VERSION ""

NS_ :

BS_:
BU_: SC PT BMS ME SC01 BMS01

BO_ 1600 SC01_DebugSlowMpex: 8 SC01
 SG_ pumpMAHLEshortCircuitErr_SC01 m44 : 26|1@0+ (1,0) [0|0] "" Vector__XXX
 SG_ pumpMAHLElowLoadOpErr_SC01 m44 : 25|1@0+ (1,0) [0|0] "" Vector__XXX
 SG_ pumpMAHLEstallFaultErr_SC01 m44 : 24|1@0+ (1,0) [0|0] "" Vector__XXX
 SG_ pumpMAHLEvoltageDeratingWarn_SC0 m44 : 39|1@0+ (1,0) [0|0] "" Vector__XXX
 SG_ pumpMAHLEunderVoltageErr_SC01 m44 : 38|1@0+ (1,0) [0|0] "" Vector__XXX
 SG_ pumpMAHLEoverVoltageErr_SC01 m44 : 37|1@0+ (1,0) [0|0] "" Vector__XXX
 SG_ pumpMAHLEoverTemperatureDerWarn_ m44 : 36|1@0+ (1,0) [0|0] "" Vector__XXX
 SG_ pumpMAHLEoverTemperatureErr_SC01 m44 : 35|1@0+ (1,0) [0|0] "" Vector__XXX
 SG_ pumpMAHLEoverCurrentErr_SC01 m44 : 34|1@0+ (1,0) [0|0] "" Vector__XXX
 SG_ pumpMAHLEinternalFaultErr_SC01 m44 : 33|1@0+ (1,0) [0|0] "" Vector__XXX
 SG_ pumpMAHLElinErr_SC01 m44 : 32|1@0+ (1,0) [0|0] "" Vector__XXX
 SG_ cmbSM30MinSettleTime_SC01 m44 : 15|16@0+ (1,0) [0|65535] "ms"  PT
 SG_ cmbSM30SettleTimeFault_SC01 m32 : 42|1@0+ (1,0) [0|1] ""  PT
 SG_ pressureSensSpecHumidity2_SC01 m43 : 55|16@0+ (0.01,0) [0|642.55] "g/kg" Vector__XXX
 SG_ pressureSensRelHumidity2_SC01 m43 : 15|8@0+ (0.4,0) [0|100] "%" Vector__XXX
 SG_ pressureSensIntakeTemp2_SC01 m43 : 23|16@0+ (0.03125,-273) [-273|1734.96875] "C" Vector__XXX
 SG_ pressureSensIntakePres2_SC01 m43 : 39|16@0+ (0.0078125,-250) [-250|251.99] "kPa" Vector__XXX
 SG_ pressure2_SC01 m22 : 15|8@0+ (0.4,0) [0|102] "psi" Vector__XXX
 SG_ cmbSM29ScoutTempIndex_SC01 m42 : 15|8@0+ (1,0) [0|255] "" Vector__XXX
 SG_ cmbSM19ScoutPDO_SC01 m42 : 55|16@0+ (0.0001,0) [0|6.5] "V" Vector__XXX
 SG_ cmbMaxSM15ratio_SC01 m41 : 39|16@0+ (0.00390625,0) [0|255.99609375] ""  PT
 SG_ cmbMinSM15ratio_SC01 m41 : 55|16@0+ (0.00390625,0) [0|255.99609375] ""  PT
 SG_ cmbMinSM17Ratio m42 : 39|16@0+ (0.00390625,0) [0|255.99609375] ""  PT
 SG_ cmbMaxSM17Ratio m42 : 23|16@0+ (0.00390625,0) [0|255.99609375] ""  PT
 SG_ cmbMaxSM16DiffC2S_SC01 m41 : 23|16@0+ (0.2,0) [0|13107] "mV"  PT
 SG_ isolationResInternRelaxed_SC01 m32 : 23|16@0+ (2,0) [0|130000] "kOhm"  PT
 SG_ pressureSensSpecHumidity_SC01 m40 : 55|16@0+ (0.01,0) [0|642.55] "g/kg"  PT
 SG_ pressureSensIntakePres_SC01 m40 : 39|16@0+ (0.0078125,-250) [-250|251.99] "kPa"  PT
 SG_ pressureSensIntakeTemp_SC01 m40 : 23|16@0+ (0.03125,-273) [-273|1734.96875] "C"  PT
 SG_ pressureSensRelHumidity_SC01 m40 : 15|8@0+ (0.4,0) [0|100] "%"  PT
 SG_ cmbVariantCodingVoltage_SC01 m32 : 55|16@0+ (0.0001,0) [0|6.5] "V"  PT
 SG_ isolationSelftestMaxDiff_SC01 m32 : 39|8@0+ (0.1,0) [0|25.5] "V"  PT
 SG_ packTypeDeterminationTime_SC01 m22 : 39|32@0+ (1,0) [0|0] "ms"  PT
 SG_ FEESector2Flags_SC01 m22 : 23|16@0+ (1,0) [0|0] ""  PT
 SG_ appTask500HzMaxAvg_SC01 m23 : 63|8@0+ (0.02,0) [0|5.1] "ms"  PT
 SG_ safetyHangLastLinkReg_SC01 m39 : 23|32@0+ (1,0) [0|4294967295] ""  PT
 SG_ safetyHangPresentLinkReg_SC01 m38 : 23|32@0+ (1,0) [0|4294967295] ""  PT
 SG_ safetyHangDataFaultStatus_SC01 m37 : 23|32@0+ (1,0) [0|4294967295] ""  PT
 SG_ safetyHangDataFaultAddr_SC01 m36 : 23|32@0+ (1,0) [0|4294967295] ""  PT
 SG_ safetyHangLastARMMode_SC01 m35 : 63|8@0+ (1,0) [0|255] ""  PT
 SG_ safetyHangPresARMMode_SC01 m35 : 55|8@0+ (1,0) [0|255] ""  PT
 SG_ safetyHangESMGrp3Reg_SC01 m35 : 23|32@0+ (1,0) [0|4294967295] ""  PT
 SG_ safetyHangInstrFaultStatus_SC01 m34 : 23|32@0+ (1,0) [0|4294967295] ""  PT
 SG_ safetyHangInstrFaultAddr_SC01 m33 : 23|32@0+ (1,0) [0|4294967295] ""  PT
 SG_ eaglePackType_SC01 m4 : 53|2@0+ (1,0) [0|3] ""  PT
 SG_ pressure_SC01 m4 : 63|8@0+ (0.4,0) [0|102] "psi"  PT
 SG_ cmbMaxSM33Diff_SC01 m31 : 15|8@0+ (0.001,0) [0|0.255] "V"  PT
 SG_ cmbMinSM29Diff_SC01 m17 : 15|8@0+ (0.001,0) [0|0.255] "V"  PT
 SG_ cmbSM4MinIndex_SC01 m24 : 15|8@0+ (1,0) [0|0] ""  PT
 SG_ cmbSM4DiffC2_SC01 m31 : 23|16@0+ (0.0001,0) [0|6.5] "V"  PT
 SG_ cmbMinSM4Diff_SC01 m31 : 39|16@0+ (0.0001,0) [0|6.5] "V"  PT
 SG_ cmbMaxSM4Diff_SC01 m21 : 55|16@0+ (0.0001,0) [0|6.5] "V"  PT
 SG_ cmbSM27MinIndex_SC01 m15 : 63|8@0+ (1,0) [0|0] ""  PT
 SG_ cmbSM27DiffC2_SC01 m24 : 55|16@0+ (0.0001,0) [0|6.5] "V"  PT
 SG_ cmbMinSM27Diff_SC01 m31 : 55|16@0+ (0.0001,0) [0|6.5] "V"  PT
 SG_ cmbMaxSM27Diff_SC01 m25 : 55|16@0+ (0.0001,0) [0|6.5] "V"  PT
 SG_ adcDriverFail_SC01 m4 : 51|4@0+ (1,0) [0|0] ""  PT
 SG_ mainUcHvilState_SC01 m32 : 41|2@0+ (1,0) [0|0] ""  PT
 SG_ mainUcIntIsoErr_SC01 m32 : 13|2@0+ (1,0) [0|0] ""  PT
 SG_ mainUcExtIsoErr_SC01 m32 : 15|2@0+ (1,0) [0|0] ""  PT
 SG_ safetyUcThermalStatus_SC01 m32 : 9|2@0+ (1,0) [0|0] ""  PT
 SG_ mainUcThermalStatus_SC01 m32 : 11|2@0+ (1,0) [0|0] ""  PT
 SG_ selfTestErrorAddress_SC01 m30 : 23|32@0+ (1,0) [0|4294967295] ""  PT
 SG_ selfTestDataFaultStatus_SC01 m29 : 23|32@0+ (1,0) [0|4294967295] ""  PT
 SG_ selfTestInstrFaultAddr_SC01 m28 : 23|32@0+ (1,0) [0|4294967295] ""  PT
 SG_ selfTestDataFaultAddr_SC01 m27 : 23|32@0+ (1,0) [0|4294967295] ""  PT
 SG_ selfTestInstrFaultStatus_SC01 m26 : 23|32@0+ (1,0) [0|4294967295] ""  PT
 SG_ internalIsolationError_SC01 m25 : 11|2@0+ (1,0) [0|0] ""  PT
 SG_ externalIsolationError_SC01 m25 : 13|2@0+ (1,0) [0|0] ""  PT
 SG_ isolationTestState_SC01 m25 : 9|2@0+ (1,0) [0|0] ""  PT
 SG_ isolationResistanceIntern_SC01 m25 : 23|16@0+ (2,0) [0|130000] "kOhm"  PT
 SG_ isolationResistanceExtern_SC01 m25 : 39|16@0+ (2,0) [0|130000] "kOhm"  PT
 SG_ maxAdolV13Diff_SC01 m24 : 23|16@0+ (0.0001,0) [0|6.5] "V"  PT
 SG_ maxAdolV7Diff_SC01 m24 : 39|16@0+ (0.0001,0) [0|6.5] "V"  PT
 SG_ pumpType_SC01 m23 : 55|8@0+ (1,0) [0|0] ""  PT
 SG_ pumpJomaLinErr_SC01 m23 : 30|1@0+ (1,0) [0|0] ""  PT
 SG_ pumpJomaPumpState_SC01 m23 : 18|3@0+ (1,0) [0|0] ""  PT
 SG_ pumpBoschPwmInStat_SC01 m23 : 27|2@0+ (1,0) [0|0] ""  PT
 SG_ pumpBoschRpmMonStat_SC01 m23 : 25|2@0+ (1,0) [0|0] ""  PT
 SG_ pumpBoschWakeupStat_SC01 m23 : 39|2@0+ (1,0) [0|0] ""  PT
 SG_ pumpBoschPostRunMode_SC01 m23 : 44|3@0+ (1,0) [0|0] ""  PT
 SG_ pumpPhaseCurrent_SC01 m23 : 15|8@0+ (0.1,0) [0|0] "A"  PT
 SG_ hvWithstandTestQual_SC01 m21 : 15|8@0+ (1,0) [0|255] ""  PT
 SG_ ESM_RAM_ODD_ADDR_UNCORR_SC01 m21 : 18|1@0+ (1,0) [0|0] ""  PT
 SG_ ESM_RAM_EVEN_ADDR_UNCORR_SC01 m21 : 17|1@0+ (1,0) [0|0] ""  PT
 SG_ ESM_FMC_UNCORR_ERR_SC01 m21 : 40|1@0+ (1,0) [0|0] ""  PT
 SG_ ESM_RAM_ODDECC_UNCORR_SC01 m21 : 23|1@0+ (1,0) [0|0] ""  PT
 SG_ ESM_RAM_EVENECC_UNCORR_SC01 m21 : 22|1@0+ (1,0) [0|0] ""  PT
 SG_ ESM_EFUSE_FARM_ERR_SC01 m21 : 21|1@0+ (1,0) [0|0] ""  PT
 SG_ ESM_RTI_WWD_NMI_SC01 m21 : 20|1@0+ (1,0) [0|0] ""  PT
 SG_ ESM_TCM_ECC_LIVE_LOCK_SC01 m21 : 19|1@0+ (1,0) [0|0] ""  PT
 SG_ ESM_RAM_ODD_UNCORR_ERR_SC01 m21 : 16|1@0+ (1,0) [0|0] ""  PT
 SG_ ESM_RAM_EVEN_UNCORR_ERR_SC01 m21 : 31|1@0+ (1,0) [0|0] ""  PT
 SG_ ESM_FMC_ADDR_UNCORR_ERR_SC01 m21 : 30|1@0+ (1,0) [0|0] ""  PT
 SG_ ESM_CCM4_COMPARE_FAULT_SC01 m21 : 29|1@0+ (1,0) [0|0] ""  PT
 SG_ ESM_RAM_ODD_CORR_ERR_SC01 m21 : 28|1@0+ (1,0) [0|0] ""  PT
 SG_ ESM_RAM_EVEN_CORR_ERR_SC01 m21 : 27|1@0+ (1,0) [0|0] ""  PT
 SG_ ESM_CLK_MONITOR_SC01 m21 : 26|1@0+ (1,0) [0|0] ""  PT
 SG_ ESM_PLL_SLIP_SC01 m21 : 25|1@0+ (1,0) [0|0] ""  PT
 SG_ ESM_FMC_CORR_ERR_SC01 m21 : 24|1@0+ (1,0) [0|0] ""  PT
 SG_ analogMMCUSleepTrigger_SC01 m20 : 55|8@0+ (0.015,0) [0|0] "V"  PT
 SG_ analogPyroLSDStatus_SC01 m20 : 63|8@0+ (0.015,0) [0|0] "V"  PT
 SG_ analogGPIO2Volt_SC01 m19 : 47|8@0+ (0.1,0) [0|25] "V"  PT
 SG_ analogGPIO2Current_SC01 m19 : 55|8@0+ (0.015,0) [0|3.825] "A"  PT
 SG_ analogGPIO1Volt_SC01 m19 : 63|8@0+ (0.1,0) [0|25] "V"  PT
 SG_ analogGPIO1Current_SC01 m20 : 15|8@0+ (0.015,0) [0|3.825] "A"  PT
 SG_ currentModuleMax_SC01 m1 : 55|16@0+ (0.1,-3200) [-3200|3200] "A"  PT
 SG_ currentModuleMin_SC01 m1 : 39|16@0+ (0.1,-3200) [-3200|3200] "A"  PT
 SG_ cmbSumOfCellSTATRef_SC01 m20 : 39|16@0+ (0.0015,0) [0|131.07] "V"  PT
 SG_ cmbSumOfCells_SC01 m20 : 23|16@0+ (0.0015,0) [0|131.07] "V"  PT
 SG_ maxCMBDieTemp_SC01 m1 : 31|8@0+ (1,-40) [-40|200] "C"  PT
 SG_ minCMBDieTemp_SC01 m1 : 23|8@0+ (1,-40) [-40|200] "C"  PT
 SG_ pumpBoschSuppVoltErr_SC01 m23 : 35|2@0+ (1,0) [0|0] ""  PT
 SG_ pumpBoschRsErr_SC01 m23 : 45|1@0+ (1,0) [0|0] ""  PT
 SG_ pumpBoschOverTempErr_SC01 m23 : 29|2@0+ (1,0) [0|0] ""  PT
 SG_ pumpBoschOverCurrErr_SC01 m23 : 47|2@0+ (1,0) [0|0] ""  PT
 SG_ pumpBoschElectricErr_SC01 m23 : 41|2@0+ (1,0) [0|0] ""  PT
 SG_ pumpBoschDryRunErr_SC01 m23 : 33|2@0+ (1,0) [0|0] ""  PT
 SG_ pumpDiagnosticBit_SC01 m23 : 31|1@0+ (1,0) [0|0] ""  PT
 SG_ pumpBoschBlockErr_SC01 m23 : 37|2@0+ (1,0) [0|0] ""  PT
 SG_ appTaskSpiRxTx_SC01 m16 : 15|8@0+ (0.02,0) [0|5.1] "ms"  PT
 SG_ variantCodingCounts_SC01 m4 : 39|8@0+ (1,0) [0|0] ""  PT
 SG_ cmbMaxUpdateTime_SC01 m17 : 23|8@0+ (2,0) [0|500] "ms"  PT
 SG_ pumpSetSpeed_SC01 m18 : 55|8@0+ (1,0) [0|255] "PCT"  PT
 SG_ hvilResistance_SC01 m17 : 31|8@0+ (2,0) [0|0] "Ohm"  PT
 SG_ cmbAvgUpdateTime_SC01 m18 : 63|8@0+ (2,0) [0|500] "ms"  PT
 SG_ pumpHCPTempProtect_SC01 m18 : 40|1@0+ (1,0) [0|0] ""  PT
 SG_ pumpHCPCommandErr_SC01 m18 : 41|1@0+ (1,0) [0|0] ""  PT
 SG_ pumpHCPRunDry_SC01 m18 : 42|1@0+ (1,0) [0|0] ""  PT
 SG_ pumpHCPUnderVoltage_SC01 m18 : 43|1@0+ (1,0) [0|0] ""  PT
 SG_ pumpHCPOverVoltage_SC01 m18 : 44|1@0+ (1,0) [0|0] ""  PT
 SG_ pumpHCPOverTemp_SC01 m18 : 45|1@0+ (1,0) [0|0] ""  PT
 SG_ pumpHCPHiCurrShutDown_SC01 m18 : 46|1@0+ (1,0) [0|0] ""  PT
 SG_ pumpHCPHwFault_SC01 m18 : 47|1@0+ (1,0) [0|0] ""  PT
 SG_ pumpTemperature_SC01 m18 : 39|8@0+ (1,-50) [0|0] "C"  PT
 SG_ pumpSpeed_SC01 m18 : 15|8@0+ (1,0) [0|255] "PCT"  PT
 SG_ pumpVoltage_SC01 m18 : 23|8@0+ (0.1,0) [0|0] "V"  PT
 SG_ pumpCurrent_SC01 m18 : 31|8@0+ (0.1,0) [0|0] "A"  PT
 SG_ posLink3_SC01 m17 : 39|16@0+ (0.04,-1250) [-1250|1371.4] "V"  PT
 SG_ negLink3_SC01 m17 : 55|16@0+ (0.04,-1250) [-1250|1371.4] "V"  PT
 SG_ posLink2_SC01 m16 : 39|16@0+ (0.04,-1250) [-1250|1371.4] "V"  PT
 SG_ negLink2_SC01 m16 : 55|16@0+ (0.04,-1250) [-1250|1371.4] "V"  PT
 SG_ cmbNrOfSamples_SC01 m16 : 23|8@0+ (1,0) [0|0] ""  PT
 SG_ cmbTaskTime_SC01 m16 : 31|8@0+ (1,0) [0|0] "ms"  PT
 SG_ appTask500HzMax_SC01 m15 : 15|8@0+ (0.02,0) [0|5.1] "ms"  PT
 SG_ moduleCount_SC01 m6 : 15|8@0+ (1,0) [0|0] ""  PT
 SG_ analogHallSense_SC01 m15 : 23|16@0+ (0.0001,0) [0|6.5535] "V"  PT
 SG_ cmbMaxDiagStepPeriodicity_SC01 m15 : 55|8@0+ (4,0) [0|1019] "ms"  PT
 SG_ minBrickVoltageLimit_SC01 m15 : 39|16@0+ (0.0001,0) [0|6.5535] "V"  PT
 SG_ appTask100Hz_SC01 m14 : 63|8@0+ (0.02,0) [0|5.1] "ms"  PT
 SG_ appTask10Hz_SC01 m14 : 55|8@0+ (0.02,0) [0|5.1] "ms"  PT
 SG_ appTaskAnalog_SC01 m14 : 47|8@0+ (0.02,0) [0|5.1] "ms"  PT
 SG_ appTaskADC_SC01 m14 : 39|8@0+ (0.02,0) [0|5.1] "ms"  PT
 SG_ appTask500HzAvg_SC01 m14 : 31|8@0+ (0.02,0) [0|5.1] "ms"  PT
 SG_ appTaskSBC_SC01 m14 : 23|8@0+ (0.02,0) [0|5.1] "ms"  PT
 SG_ appTaskCMBDriver_SC01 m14 : 15|8@0+ (0.02,0) [0|5.1] "ms"  PT
 SG_ safetyInitTime_SC01 m12 : 15|8@0+ (2,0) [0|500] "ms"  PT
 SG_ debugSlowMpex_SC01 M : 7|8@0+ (1,0) [0|0] ""  PT
 SG_ sbcWUAuto_SC01 m11 : 9|1@0+ (1,0) [0|0] ""  PT
 SG_ sbcWUUnknown_SC01 m11 : 8|1@0+ (1,0) [0|0] ""  PT
 SG_ sbcWUDebug_SC01 m11 : 10|1@0+ (1,0) [0|0] ""  PT
 SG_ sbcWUPOR_SC01 m11 : 11|1@0+ (1,0) [0|0] ""  PT
 SG_ sbcWUPressure_SC01 m11 : 12|1@0+ (1,0) [0|0] ""  PT
 SG_ sbcWUClock_SC01 m11 : 13|1@0+ (1,0) [0|0] ""  PT
 SG_ sbcWUCAN_SC01 m11 : 14|1@0+ (1,0) [0|0] ""  PT
 SG_ sbcWUKey_SC01 m11 : 15|1@0+ (1,0) [0|0] ""  PT
 SG_ mux960N3VRef_SC01 m13 : 39|16@0+ (-0.000805664,0) [0|0] "V"  PT
 SG_ mux960P2P5VRef_SC01 m13 : 55|16@0+ (0.000805664,0) [0|0] "V"  PT
 SG_ mux440Gnd_SC01 m10 : 15|8@0+ (0.000805664,0) [0|0] "V"  PT
 SG_ analogHallGain_SC01 m13 : 23|16@0+ (1E-005,0.8) [0.8|1.455] "k"  PT
 SG_ analogHallOffset_SC01 m13 : 15|8@0+ (0.0001,-0.005) [-0.005|0.0205] "V"  PT
 SG_ negPackPrime_SC01 m12 : 55|16@0+ (0.04,-1250) [-1250|1250] "V"  PT
 SG_ posPackPrime_SC01 m12 : 39|16@0+ (0.04,-1250) [-1250|1250] "V"  PT
 SG_ packVoltage_SC01 m12 : 23|16@0+ (0.04,-1250) [-1250|1250] "V"  PT
 SG_ sleepTime_SC01 m11 : 23|16@0+ (1,0) [0|0] "s"  PT
 SG_ analogNegHVOffset_SC01 m10 : 63|8@0+ (1,-120) [-120|120] "Bits"  PT
 SG_ analogPosHVOffset_SC01 m10 : 55|8@0+ (1,-120) [-120|120] "Bits"  PT
 SG_ analogNegHVGain_SC01 m10 : 39|16@0+ (1E-005,0.8) [0|0] "k"  PT
 SG_ analogPosHVGain_SC01 m10 : 23|16@0+ (1E-005,0.8) [0.8|1.45535] "k"  PT
 SG_ mux910Gnd_SC01 m8 : 15|8@0+ (0.000805664,0) [0|0] "V"  PT
 SG_ mux960Gnd_SC01 m9 : 15|8@0+ (0.000805664,0) [0|0] "V"  PT
 SG_ analogAddr5_SC01 m9 : 55|16@0+ (0.000805861,0) [0|0] "V"  PT
 SG_ analogAddr4_SC01 m9 : 39|16@0+ (0.000805861,0) [0|0] "V"  PT
 SG_ analogAddr3_SC01 m9 : 23|16@0+ (0.000805861,0) [0|0] "V"  PT
 SG_ analogAddr2_SC01 m8 : 55|16@0+ (0.000805861,0) [0|0] "V"  PT
 SG_ analogAddr1_SC01 m8 : 39|16@0+ (0.000805861,0) [0|0] "V"  PT
 SG_ analogAddr0_SC01 m8 : 23|16@0+ (0.000805861,0) [0|0] "V"  PT
 SG_ sbcVREF2P5_SC01 m7 : 15|8@0+ (0.003222656,2.25) [2.25|3.0715] "V"  PT
 SG_ mux910N3VRef_SC01 m7 : 39|16@0+ (-0.000805664,0) [0|0] "V"  PT
 SG_ mux910P2P5VRef_SC01 m7 : 55|16@0+ (0.000805664,0) [0|0] "V"  PT
 SG_ analogHvilCurrentPWM_SC01 m3 : 31|8@0+ (1,0) [0|255] "mA"  PT
 SG_ analogSBCSupply_SC01 m4 : 47|8@0+ (0.1,0) [0|25] "V"  PT
 SG_ analogHvilCurrent_SC01 m3 : 23|8@0+ (1,0) [0|255] "mA"  PT
 SG_ analogPressureSense_SC01 m4 : 23|8@0+ (0.025,0) [0|6.375] "V"  PT
 SG_ analog5VSensorSupply_SC01 m4 : 15|8@0+ (0.025,0) [0|6.375] "V"  PT
 SG_ analogPrechgRel2CoilMinus_SC01 m2 : 23|8@0+ (0.2,0) [0|51] "V"  PT
 SG_ analogPrechgRel1CoilMinus_SC01 m3 : 55|8@0+ (0.2,0) [0|51] "V"  PT
 SG_ analogNegCntr3CoilMinus_SC01 m2 : 31|8@0+ (0.2,0) [0|51] "V"  PT
 SG_ analogNegCntr2CoilMinus_SC01 m2 : 39|8@0+ (0.2,0) [0|51] "V"  PT
 SG_ analogNegCntr1CoilMinus_SC01 m2 : 47|8@0+ (0.2,0) [0|51] "V"  PT
 SG_ analogPosCntr3CoilMinus_SC01 m2 : 55|8@0+ (0.2,0) [0|51] "V"  PT
 SG_ analogPosCntr2CoilMinus_SC01 m2 : 63|8@0+ (0.2,0) [0|51] "V"  PT
 SG_ analogPosCntr1CoilMinus_SC01 m3 : 15|8@0+ (0.2,0) [0|51] "V"  PT
 SG_ minModuleTemperature_SC01 m1 : 15|8@0+ (1,-40) [-40|200] "C"  PT
 SG_ maxModuleTemperature_SC01 m2 : 15|8@0+ (1,-40) [-40|200] "C"  PT
 SG_ analogHvilReturn_SC01 m3 : 39|8@0+ (0.1,0) [0|25] "V"  PT
 SG_ analog5VDSupply_SC01 m3 : 47|8@0+ (0.025,0) [0|6.375] "V"  PT
 SG_ analogHvilOut_SC01 m3 : 63|8@0+ (0.1,0) [0|25] "V"  PT
 SG_ analogCurrentSensor12V_SC01 m4 : 31|8@0+ (0.075,0) [0|19] "V"  PT
 SG_ cmbErrorCounter_SC01 m6 : 47|8@0+ (1,0) [0|255] ""  PT
 SG_ PECErrorCounter_SC01 m6 : 39|8@0+ (1,0) [0|255] ""  PT
 SG_ maxVREF2_SC01 m7 : 23|16@0+ (0.0001,0) [0|6.5] "V"  PT
 SG_ minVREF2_SC01 m6 : 55|16@0+ (0.0001,0) [0|6.5] "V"  PT
 SG_ currentPlausiCounter_SC01 m5 : 15|8@0+ (1,0) [0|0] ""  PT
 SG_ hallCurrentOffset_SC01 m5 : 39|16@0+ (0.001,-30) [-30|30] "A"  PT
 SG_ sumOfCurrentsFiltered_SC01 m5 : 23|16@0+ (0.1,-3200) [-3200|3353.5] "A"  PT
 SG_ hallCurrentAveraged_SC01 m5 : 55|16@0+ (0.1,-3200) [-3200|3200] "A"  PT
 SG_ analogHallSupply_SC01 m6 : 23|16@0+ (0.0005,0) [0|32.7675] "V"  PT
 SG_ SWVersion_SC01 m11 : 39|32@0+ (1,0) [0|4294967295] ""  PT
 SG_ contactorControlPos1_SC01 m19 : 23|4@0+ (1,0) [0|7] ""  PT
 SG_ contactorControlNeg1_SC01 m19 : 19|4@0+ (1,0) [0|7] ""  PT
 SG_ contactorControlPre1_SC01 m19 : 11|4@0+ (1,0) [0|7] ""  PT
 SG_ contactorControlPos2_SC01 m19 : 31|4@0+ (1,0) [0|7] ""  PT
 SG_ contactorControlNeg2_SC01 m19 : 27|4@0+ (1,0) [0|7] ""  PT
 SG_ contactorControlPre2_SC01 m19 : 15|4@0+ (1,0) [0|7] ""  PT
 SG_ contactorControlPos3_SC01 m19 : 39|4@0+ (1,0) [0|7] ""  PT
 SG_ contactorControlNeg3_SC01 m19 : 35|4@0+ (1,0) [0|7] ""  PT

BO_ 1664 SC01_DebugFastMpex: 8 SC01
 SG_ selfTestFaultCntrCtrl_SC01 m11 : 23|8@0+ (1,0) [0|0] ""  PT
 SG_ cmbASICFault_SC01 m11 : 15|8@0+ (1,0) [0|0] ""  PT
 SG_ DIGIO_PYRO_LSD_EN_SC01 m2 : 12|1@0+ (1,0) [0|0] ""  PT
 SG_ mainUcExtIsoResistance_SC01 m10 : 55|16@0+ (1,0) [0|0] "KOhm"  PT
 SG_ BMS_C38_AR2MsgFault_SC01 m10 : 47|2@0+ (1,0) [0|0] ""  PT
 SG_ stateCoolant_SC01 m10 : 45|1@0+ (1,0) [0|0] ""  PT
 SG_ stateThermalEvent_SC01 m10 : 44|1@0+ (1,0) [0|0] ""  PT
 SG_ stateCANTx_SC01 m10 : 43|1@0+ (1,0) [0|0] ""  PT
 SG_ CANTxFaultTriggerFailed_SC01 m10 : 42|1@0+ (1,0) [0|0] ""  PT
 SG_ CANTxBMS1ST3MsgFault_SC01 m10 : 10|1@0+ (1,0) [0|0] ""  PT
 SG_ CANTxBMSDispReqMsgFault_SC01 m10 : 9|1@0+ (1,0) [0|0] ""  PT
 SG_ CANTxHVBatMsgFault_SC01 m10 : 8|1@0+ (1,0) [0|0] ""  PT
 SG_ mainUcCntrCtrlReq_SC01 m10 : 41|2@0+ (1,0) [0|0] ""  PT
 SG_ mainUcCntrWeldState_SC01 m10 : 39|4@0+ (1,0) [0|0] ""  PT
 SG_ safetyUcCntrState_SC01 m10 : 33|2@0+ (1,0) [0|0] ""  PT
 SG_ mainUcCntrState_SC01 m10 : 35|2@0+ (1,0) [0|0] ""  PT
 SG_ safetyCANMsg4Fault_SC01 m10 : 31|4@0+ (1,0) [0|0] ""  PT
 SG_ safetyCANMsg3Fault_SC01 m10 : 27|4@0+ (1,0) [0|0] ""  PT
 SG_ safetyCANMsg2Fault_SC01 m10 : 23|4@0+ (1,0) [0|0] ""  PT
 SG_ safetyCANMsg1Fault_SC01 m10 : 19|4@0+ (1,0) [0|0] ""  PT
 SG_ cmbBalancingDesired_SC01 m10 : 15|1@0+ (1,0) [0|0] ""  PT
 SG_ DIGIO_GPIO1_ON_SC01 m2 : 10|1@0+ (1,0) [0|0] ""  PT
 SG_ DIGIO_ZDW_LSD_EN_SC01 m2 : 11|1@0+ (1,0) [0|0] ""  PT
 SG_ currentShortCircuit_SC01 m2 : 9|1@0+ (1,0) [0|0] ""  PT
 SG_ contactorCntrSelfTest_SC01 m10 : 14|4@0+ (1,0) [0|15] ""  PT
 SG_ maxBrickVoltage_SC01 m11 : 39|16@0+ (0.0001,0) [0|6.5] "V"  PT
 SG_ minBrickVoltage_SC01 m11 : 55|16@0+ (0.0001,0) [0|6.5] "V"  PT
 SG_ cmbLastUpdateTime_SC01 m0 : 55|8@0+ (2,0) [0|500] "ms"  PT
 SG_ weldCheckState_SC01 m2 : 15|3@0+ (1,0) [0|0] ""  PT
 SG_ debugFastMpex_SC01 M : 7|8@0+ (1,0) [0|0] ""  PT
 SG_ SPIRxTxTimeAllPckts_SC01 m0 : 63|8@0+ (2,0) [0|500] "ms"  PT
 SG_ sleepRqASW_SC01 m2 : 8|1@0+ (1,0) [0|0] ""  PT
 SG_ prechgCtr1OnReqASW_SC01 m1 : 27|1@0+ (1,0) [0|0] ""  PT
 SG_ negCtr1OnReqASW_SC01 m1 : 25|1@0+ (1,0) [0|0] ""  PT
 SG_ posCtr1OnReqASW_SC01 m1 : 26|1@0+ (1,0) [0|0] ""  PT
 SG_ key_SC01 m1 : 24|1@0+ (1,0) [0|0] ""  PT
 SG_ stateContactorControl_SC01 m0 : 41|1@0+ (1,0) [0|0] ""  PT
 SG_ DIGIO_MULTIPLEX_m101_S3_SC01 m0 : 40|1@0+ (1,0) [0|0] ""  PT
 SG_ analogCntrPwrPlus_SC01 m1 : 15|8@0+ (0.2,0) [0|50] "V"  PT
 SG_ weldedState_SC01 m0 : 42|1@0+ (1,0) [0|0] ""  PT
 SG_ stateVoltage_SC01 m0 : 43|1@0+ (1,0) [0|0] ""  PT
 SG_ stateTemperature_SC01 m0 : 44|1@0+ (1,0) [0|0] ""  PT
 SG_ stateSelfTest_SC01 m0 : 45|1@0+ (1,0) [0|0] ""  PT
 SG_ stateHVIL_SC01 m0 : 46|1@0+ (1,0) [0|0] ""  PT
 SG_ stateCurrent_SC01 m0 : 47|1@0+ (1,0) [0|0] ""  PT
 SG_ stateCrash2_SC01 m0 : 36|1@0+ (1,0) [0|0] ""  PT
 SG_ stateCrash1_SC01 m0 : 37|1@0+ (1,0) [0|0] ""  PT
 SG_ stateContactors_SC01 m0 : 38|1@0+ (1,0) [0|0] ""  PT
 SG_ stateCANRx_SC01 m0 : 39|1@0+ (1,0) [0|0] ""  PT
 SG_ itemState_SC01 m0 : 35|4@0+ (1,0) [0|0] ""  PT
 SG_ DIGIO_SAFETY_GPIO0_SC01 m0 : 8|1@0+ (1,0) [0|0] ""  PT
 SG_ DIGIO_SC_LED501_CONTROL_SC01 m0 : 9|1@0+ (1,0) [0|0] ""  PT
 SG_ DIGIO_LNK_ISO_TST_SW_SC01 m0 : 10|1@0+ (1,0) [0|0] ""  PT
 SG_ DIGIO_SC_LED500_CONTROL_SC01 m0 : 11|1@0+ (1,0) [0|0] ""  PT
 SG_ DIGIO_POS_CNTR1_ON_SC01 m0 : 12|1@0+ (1,0) [0|0] ""  PT
 SG_ DIGIO_NEG_CNTR3_ON_SC01 m0 : 13|1@0+ (1,0) [0|0] ""  PT
 SG_ DIGIO_PRECHG_REL2_ON_SC01 m0 : 14|1@0+ (1,0) [0|0] ""  PT
 SG_ DIGIO_NEG_ISO_TEST_SW_SC01 m0 : 15|1@0+ (1,0) [0|0] ""  PT
 SG_ DIGIO_PRECHG_REL1_ON_SC01 m0 : 16|1@0+ (1,0) [0|0] ""  PT
 SG_ DIGIO_POS_ISO_TEST_SC01 m0 : 17|1@0+ (1,0) [0|0] ""  PT
 SG_ DIGIO_HVIL_PWM_SC01 m0 : 18|1@0+ (1,0) [0|0] ""  PT
 SG_ DIGIO_CNTR_HISIDE_ON_SC_SC01 m0 : 19|1@0+ (1,0) [0|0] ""  PT
 SG_ DIGIO_CRASH_DETECT_SC01 m0 : 20|1@0+ (1,0) [0|0] ""  PT
 SG_ DIGIO_NEG_CNTR2_ON_SC01 m0 : 21|1@0+ (1,0) [0|0] ""  PT
 SG_ DIGIO_NEG_CNTR1_ON_SC01 m0 : 22|1@0+ (1,0) [0|0] ""  PT
 SG_ DIGIO_POS_CNTR3_ON_SC01 m0 : 23|1@0+ (1,0) [0|0] ""  PT
 SG_ DIGIO_POS_CNTR2_ON_SC01 m0 : 24|1@0+ (1,0) [0|0] ""  PT
 SG_ DIGIO_MULTIPLEX_m101_S2_SC01 m0 : 25|1@0+ (1,0) [0|0] ""  PT
 SG_ DIGIO_MULTIPLEX_8TO1_S1_SC01 m0 : 26|1@0+ (1,0) [0|0] ""  PT
 SG_ DIGIO_CNTR_CLOSE_OK_CHCKD_SC01 m0 : 27|1@0+ (1,0) [0|0] ""  PT
 SG_ DIGIO_MULTIPLEX_8TO1_S2_SC01 m0 : 28|1@0+ (1,0) [0|0] ""  PT
 SG_ DIGIO_CNTR_CLOSE_OK_SC01 m0 : 29|1@0+ (1,0) [0|0] ""  PT
 SG_ DIGIO_MULTIPLEX_m101_S1_SC01 m0 : 30|1@0+ (1,0) [0|0] ""  PT
 SG_ DIGIO_CNTR_HISIDE_ON_CHCKD_SC01 m0 : 31|1@0+ (1,0) [0|0] ""  PT
 SG_ posPack_SC01 m2 : 23|16@0+ (0.04,-1250) [-1250|1250] "V"  PT
 SG_ posLink_SC01 m2 : 55|16@0+ (0.04,-1250) [-1250|1371.4] "V"  PT
 SG_ negPack_SC01 m2 : 39|16@0+ (0.04,-1250) [-1250|1250] "V"  PT
 SG_ negLink_SC01 m1 : 39|16@0+ (0.04,-1250) [-1250|1371.4] "V"  PT
 SG_ hallCurrent_SC01 m1 : 23|12@0+ (0.6,-1200) [-1200|1257] "A"  PT
 SG_ analogCntrPwrPlusISense_SC01 m1 : 63|8@0+ (0.05,0) [0|12.5] "A"  PT
 SG_ analogCntrPwrPlusSwitched_SC01 m1 : 55|8@0+ (0.2,0) [0|50] "V"  PT
 SG_ BIT_ANALOG_REF_FAIL_SC01 m3 : 8|1@0+ (1,0) [0|0] ""  PT
 SG_ BIT_ANALOG_ADCDRIVER_FAIL_SC01 m3 : 9|1@0+ (1,0) [0|0] ""  PT
 SG_ BIT_ANALOG_MUX910_HW_SC01 m3 : 10|1@0+ (1,0) [0|0] ""  PT
 SG_ BIT_ANALOG_MUX960_HW_SC01 m3 : 11|1@0+ (1,0) [0|0] ""  PT
 SG_ BIT_ANALOG_MUX301_HW_SC01 m3 : 12|1@0+ (1,0) [0|0] ""  PT
 SG_ BIT_ANALOG_MUX440_HW_SC01 m3 : 13|1@0+ (1,0) [0|0] ""  PT
 SG_ BIT_ANALOG_5VA_FAIL_SC01 m3 : 14|1@0+ (1,0) [0|0] ""  PT
 SG_ BIT_ANALOG_HV_SIGN_SC01 m3 : 15|1@0+ (1,0) [0|0] ""  PT
 SG_ BIT_CAN_ISENSE01_MIA_SC01 m3 : 24|1@0+ (1,0) [0|0] ""  PT
 SG_ BIT_CAN_ISENSE02_MIA_SC01 m3 : 25|1@0+ (1,0) [0|0] ""  PT
 SG_ BIT_CAN_ISENSE03_MIA_SC01 m3 : 26|1@0+ (1,0) [0|0] ""  PT
 SG_ BIT_CAN_ISENSE04_MIA_SC01 m3 : 27|1@0+ (1,0) [0|0] ""  PT
 SG_ BIT_CAN_ISENSE05_MIA_SC01 m3 : 28|1@0+ (1,0) [0|0] ""  PT
 SG_ BIT_CAN_PT_MIA_SC01 m3 : 29|1@0+ (1,0) [0|0] ""  PT
 SG_ BIT_CAN_PT_CRC_SC01 m3 : 30|1@0+ (1,0) [0|0] ""  PT
 SG_ BIT_CAN_PT_ALIVE_SC01 m3 : 31|1@0+ (1,0) [0|0] ""  PT
 SG_ BIT_CAN_SAFETYLIN_MIA_SC01 m3 : 32|1@0+ (1,0) [0|0] ""  PT
 SG_ BIT_CAN_SAFETYLIN_SHUTDOWN_SC01 m3 : 33|1@0+ (1,0) [0|0] ""  PT
 SG_ BIT_CMB_GPIO_SHORT_SC01 m3 : 40|1@0+ (1,0) [0|0] ""  PT
 SG_ BIT_CMB_C2S_LEAK_SC01 m3 : 41|1@0+ (1,0) [0|0] ""  PT
 SG_ BIT_CMB_SENSE_LINE_SC01 m3 : 42|1@0+ (1,0) [0|0] ""  PT
 SG_ BIT_CMB_SUMOFCELL_CHECK_SC01 m3 : 43|1@0+ (1,0) [0|0] ""  PT
 SG_ BIT_CMB_DRIVER_TIMING_SC01 m3 : 44|1@0+ (1,0) [0|0] ""  PT
 SG_ BIT_CMB_CLEAR_SC01 m3 : 45|1@0+ (1,0) [0|0] ""  PT
 SG_ BIT_CMB_SELFTEST_SC01 m3 : 46|1@0+ (1,0) [0|0] ""  PT
 SG_ BIT_CMB_GPIO_OPEN_SC01 m3 : 47|1@0+ (1,0) [0|0] ""  PT
 SG_ BIT_CMB_CELLV_RANGE_ERR_SC01 m3 : 48|1@0+ (1,0) [0|0] ""  PT
 SG_ BIT_CMB_ADOL_CHECK_SC01 m3 : 49|1@0+ (1,0) [0|0] ""  PT
 SG_ BIT_CMB_BALANCING_STUCK_SC01 m3 : 50|1@0+ (1,0) [0|0] ""  PT
 SG_ BIT_CMB_SUPPLY_SC01 m3 : 51|1@0+ (1,0) [0|0] ""  PT
 SG_ BIT_CMB_DEFECT_SC01 m3 : 52|1@0+ (1,0) [0|0] ""  PT
 SG_ BIT_CMB_PEC_ERROR_SC01 m3 : 53|1@0+ (1,0) [0|0] ""  PT
 SG_ BIT_CMB_GPIO_ERROR_SC01 m3 : 54|1@0+ (1,0) [0|0] ""  PT
 SG_ BIT_CMB_DIGTLREDNCY_LF_SC01 m3 : 55|1@0+ (1,0) [0|0] ""  PT
 SG_ BIT_CCTRL_SELFTEST_SC01 m4 : 8|1@0+ (1,0) [0|0] ""  PT
 SG_ BIT_CCTRL_DRIVER_FAULT_SC01 m4 : 9|1@0+ (1,0) [0|0] ""  PT
 SG_ BIT_CCTRL_HISIDE_STCLSD_SC01 m4 : 10|1@0+ (1,0) [0|0] ""  PT
 SG_ BIT_CCTRL_LOSIDE_STCLSD_SC01 m4 : 11|1@0+ (1,0) [0|0] ""  PT
 SG_ BIT_CCTRL_HISIDE_STUCK_OPEN_SC01 m4 : 12|1@0+ (1,0) [0|0] ""  PT
 SG_ BIT_CCTRL_HVOLTAGE_COND_SC01 m4 : 13|1@0+ (1,0) [0|0] ""  PT
 SG_ BIT_CCTRL_POS1_OPENCIRC_SC01 m4 : 14|1@0+ (1,0) [0|0] ""  PT
 SG_ BIT_CCTRL_NEG1_OPENCIRC_SC01 m4 : 15|1@0+ (1,0) [0|0] ""  PT
 SG_ BIT_CCTRL_PRECHG1_OPENCIRC_SC01 m4 : 16|1@0+ (1,0) [0|0] ""  PT
 SG_ BIT_CCTRL_POS2_OPENCIRC_SC01 m4 : 17|1@0+ (1,0) [0|0] ""  PT
 SG_ BIT_CCTRL_NEG2_OPENCIRC_SC01 m4 : 18|1@0+ (1,0) [0|0] ""  PT
 SG_ BIT_CCTRL_LOSDE_STOPEN_SC01 m4 : 19|1@0+ (1,0) [0|0] ""  PT
 SG_ BIT_CCTRL_POS3_OPENCIRC_SC01 m4 : 20|1@0+ (1,0) [0|0] ""  PT
 SG_ BIT_CCTRL_PRECHG2_OPENCIRC_SC01 m4 : 21|1@0+ (1,0) [0|0] ""  PT
 SG_ BIT_CCTRL_ITEM_OFF_OPEN_SC01 m4 : 22|1@0+ (1,0) [0|0] ""  PT
 SG_ BIT_CCTRL_UNEXPECTED_OPEN_SC01 m4 : 23|1@0+ (1,0) [0|0] ""  PT
 SG_ BIT_CNTR_ISOLATION_SC01 m4 : 24|1@0+ (1,0) [0|0] ""  PT
 SG_ BIT_CNTR_ISO_AND_POT_WELD_SC01 m4 : 25|1@0+ (1,0) [0|0] ""  PT
 SG_ BIT_CNTR_POS1_WELDED_SC01 m4 : 26|1@0+ (1,0) [0|0] ""  PT
 SG_ BIT_CNTR_NEG1_WELDED_SC01 m4 : 27|1@0+ (1,0) [0|0] ""  PT
 SG_ BIT_CNTR_POS2_WELDED_SC01 m4 : 28|1@0+ (1,0) [0|0] ""  PT
 SG_ BIT_CNTR_NEG2_WELDED_SC01 m4 : 29|1@0+ (1,0) [0|0] ""  PT
 SG_ BIT_CNTR_POS3_WELDED_SC01 m4 : 30|1@0+ (1,0) [0|0] ""  PT
 SG_ BIT_CNTR_NEG3_WELDED_SC01 m4 : 31|1@0+ (1,0) [0|0] ""  PT
 SG_ BIT_CNTR_P_ANDOR_N_WELD_SC01 m4 : 32|1@0+ (1,0) [0|0] ""  PT
 SG_ BIT_CNTR_HIGH_CY_SC01 m4 : 33|1@0+ (1,0) [0|0] ""  PT
 SG_ BIT_CNTR_WELDCHECK_TIMEOUT_SC01 m4 : 34|1@0+ (1,0) [0|0] ""  PT
 SG_ BIT_CURRENT_PLAUSIBILITY_SC01 m4 : 40|1@0+ (1,0) [0|0] ""  PT
 SG_ BIT_CURRENT_OVERCHARGE_SC01 m4 : 41|1@0+ (1,0) [0|0] ""  PT
 SG_ BIT_CURRENT_OVERDISCHARGE_SC01 m4 : 42|1@0+ (1,0) [0|0] ""  PT
 SG_ BIT_CURRENT_ISENSE1_INVALID_SC01 m4 : 43|1@0+ (1,0) [0|0] ""  PT
 SG_ BIT_CURRENT_ISENSE2_INVALID_SC01 m4 : 44|1@0+ (1,0) [0|0] ""  PT
 SG_ BIT_CURRENT_ISENSE3_INVALID_SC01 m4 : 45|1@0+ (1,0) [0|0] ""  PT
 SG_ BIT_CURRENT_ISENSE4_INVALID_SC01 m4 : 46|1@0+ (1,0) [0|0] ""  PT
 SG_ BIT_CURRENT_ISENSE5_INVALID_SC01 m4 : 47|1@0+ (1,0) [0|0] ""  PT
 SG_ BIT_CURRENT_HALL_INVALID_SC01 m4 : 48|1@0+ (1,0) [0|0] ""  PT
 SG_ BIT_CURRENT_OFFSET_FAULT_SC01 m4 : 49|1@0+ (1,0) [0|0] ""  PT
 SG_ BIT_FLUXGATE1_CURRENT_FAULT_SC01 m5 : 8|1@0+ (1,0) [0|0] ""  PT
 SG_ BIT_FLUXGATE_12V_LOW_SC01 m5 : 18|1@0+ (1,0) [0|0] ""  PT
 SG_ BIT_HALL_INVALID_SC01 m5 : 24|1@0+ (1,0) [0|0] ""  PT
 SG_ BIT_HALL_PWR_FAIL_LO_SC01 m5 : 25|1@0+ (1,0) [0|0] ""  PT
 SG_ BIT_HALL_SENSELO_SC01 m5 : 26|1@0+ (1,0) [0|0] ""  PT
 SG_ BIT_HALL_SENSEHI_SC01 m5 : 27|1@0+ (1,0) [0|0] ""  PT
 SG_ BIT_HVIL_HW_FAULT_SC01 m5 : 40|1@0+ (1,0) [0|0] ""  PT
 SG_ BIT_HVIL_OPEN_CIRCUIT_SC01 m5 : 41|1@0+ (1,0) [0|0] ""  PT
 SG_ BIT_HVIL_SHORT_SUPPLY_SC01 m5 : 42|1@0+ (1,0) [0|0] ""  PT
 SG_ BIT_HVIL_SHORT_CHASSIS_SC01 m5 : 43|1@0+ (1,0) [0|0] ""  PT
 SG_ BIT_HVIL_RESISTANCE_HIGH_SC01 m5 : 44|1@0+ (1,0) [0|0] ""  PT
 SG_ BIT_HVIL_SHORT_CIRCUIT_SC01 m5 : 45|1@0+ (1,0) [0|0] ""  PT
 SG_ BIT_ISASHUNT1_CURRENT_FAULT_SC01 m7 : 24|1@0+ (1,0) [0|0] ""  PT
 SG_ BIT_ISASHUNT2_CURRENT_FAULT_SC01 m7 : 25|1@0+ (1,0) [0|0] ""  PT
 SG_ BIT_ISASHUNT3_CURRENT_FAULT_SC01 m7 : 26|1@0+ (1,0) [0|0] ""  PT
 SG_ BIT_ISASHUNT4_CURRENT_FAULT_SC01 m7 : 27|1@0+ (1,0) [0|0] ""  PT
 SG_ BIT_ISASHUNT5_CURRENT_FAULT_SC01 m7 : 28|1@0+ (1,0) [0|0] ""  PT
 SG_ BIT_ISASHUNT1_CHARGE_FAULT_SC01 m7 : 29|1@0+ (1,0) [0|0] ""  PT
 SG_ BIT_ISASHUNT2_CHARGE_FAULT_SC01 m7 : 30|1@0+ (1,0) [0|0] ""  PT
 SG_ BIT_ISASHUNT3_CHARGE_FAULT_SC01 m7 : 31|1@0+ (1,0) [0|0] ""  PT
 SG_ BIT_ISASHUNT4_CHARGE_FAULT_SC01 m7 : 32|1@0+ (1,0) [0|0] ""  PT
 SG_ BIT_ISASHUNT5_CHARGE_FAULT_SC01 m7 : 33|1@0+ (1,0) [0|0] ""  PT
 SG_ BIT_ISASHUNT_SUPPLY_LOW_SC01 m7 : 34|1@0+ (1,0) [0|0] ""  PT
 SG_ BIT_LINK_POS_HW_FAIL_SC01 m7 : 40|1@0+ (1,0) [0|0] ""  PT
 SG_ BIT_LINK_NEG_HW_FAIL_SC01 m7 : 41|1@0+ (1,0) [0|0] ""  PT
 SG_ BIT_PUMP_LIN_FAILURE_SC01 m8 : 8|1@0+ (1,0) [0|0] ""  PT
 SG_ BIT_PUMP_OVERTEMPERATURE_SC01 m8 : 9|1@0+ (1,0) [0|0] ""  PT
 SG_ BIT_PUMP_SPEED_HIGH_SC01 m8 : 10|1@0+ (1,0) [0|0] ""  PT
 SG_ BIT_PUMP_SPEED_LOW_SC01 m8 : 11|1@0+ (1,0) [0|0] ""  PT
 SG_ BIT_PUMP_DRY_RUN_SC01 m8 : 12|1@0+ (1,0) [0|0] ""  PT
 SG_ BIT_SBC_VCORE_OOR_SC01 m6 : 8|1@0+ (1,0) [0|0] ""  PT
 SG_ BIT_SBC_SELFTEST_SC01 m6 : 9|1@0+ (1,0) [0|0] ""  PT
 SG_ BIT_SBC_INIT_SC01 m6 : 10|1@0+ (1,0) [0|0] ""  PT
 SG_ BIT_SBC_WATCHDOG_SC01 m6 : 11|1@0+ (1,0) [0|0] ""  PT
 SG_ BIT_SBC_FECBITFLIP_SC01 m6 : 12|1@0+ (1,0) [0|0] ""  PT
 SG_ BIT_SBC_VREUV_SC01 m6 : 13|1@0+ (1,0) [0|0] ""  PT
 SG_ BIT_SBC_FAILSAFE_SC01 m6 : 14|1@0+ (1,0) [0|0] ""  PT
 SG_ BIT_SBC_VAUX_OOR_SC01 m6 : 15|1@0+ (1,0) [0|0] ""  PT
 SG_ BIT_SBC_VCCA_OOR_SC01 m6 : 16|1@0+ (1,0) [0|0] ""  PT
 SG_ BIT_SBC_FCRBM_OOR_SC01 m6 : 17|1@0+ (1,0) [0|0] ""  PT
 SG_ BIT_SBC_FLT_ERR_CNTR_SC01 m6 : 18|1@0+ (1,0) [0|0] ""  PT
 SG_ BIT_SBC_FS0B_FAIL_SC01 m6 : 19|1@0+ (1,0) [0|0] ""  PT
 SG_ BIT_SBC_SPI_ERRORS_SC01 m6 : 20|1@0+ (1,0) [0|0] ""  PT
 SG_ BIT_SBC_SPI_TX_FAIL_SC01 m6 : 21|1@0+ (1,0) [0|0] ""  PT
 SG_ BIT_SBC_NERROR_ACTIVE_SC01 m6 : 22|1@0+ (1,0) [0|0] ""  PT
 SG_ BIT_SELFTEST_RAM_SC01 m6 : 24|1@0+ (1,0) [0|0] ""  PT
 SG_ BIT_SELFTEST_FLASH_SC01 m6 : 25|1@0+ (1,0) [0|0] ""  PT
 SG_ BIT_SELFTEST_CLOCK_SC01 m6 : 26|1@0+ (1,0) [0|0] ""  PT
 SG_ BIT_SELFTEST_WATCHDOG_SC01 m6 : 27|1@0+ (1,0) [0|0] ""  PT
 SG_ BIT_SELFTEST_STACK_SC01 m6 : 28|1@0+ (1,0) [0|0] ""  PT
 SG_ BIT_SELFTEST_L2L3_SC01 m6 : 29|1@0+ (1,0) [0|0] ""  PT
 SG_ BIT_SELFTEST_RTI_REG_SC01 m6 : 30|1@0+ (1,0) [0|0] ""  PT
 SG_ BIT_SELFTEST_EXCEPTION_SC01 m6 : 31|1@0+ (1,0) [0|0] ""  PT
 SG_ BIT_SELFTEST_5VD_FAIL_SC01 m6 : 32|1@0+ (1,0) [0|0] ""  PT
 SG_ BIT_SELFTEST_VIM_SC01 m6 : 33|1@0+ (1,0) [0|0] ""  PT
 SG_ BIT_SELFTEST_TASKTIME_SC01 m6 : 34|1@0+ (1,0) [0|0] ""  PT
 SG_ BIT_SELFTEST_RTI_SC01 m6 : 35|1@0+ (1,0) [0|0] ""  PT
 SG_ BIT_SELFTEST_ESM_SC01 m6 : 36|1@0+ (1,0) [0|0] ""  PT
 SG_ BIT_SELFTEST_IOM_SC01 m6 : 37|1@0+ (1,0) [0|0] ""  PT
 SG_ BIT_SELFTEST_SBC_SC01 m6 : 38|1@0+ (1,0) [0|0] ""  PT
 SG_ BIT_SELFTEST_CPU_SC01 m6 : 39|1@0+ (1,0) [0|0] ""  PT
 SG_ BIT_TEMP_MODULEOVERTEMP_SC01 m6 : 40|1@0+ (1,0) [0|0] ""  PT
 SG_ BIT_TEMP_MODULETEMP_INVALID_SC01 m6 : 41|1@0+ (1,0) [0|0] ""  PT
 SG_ BIT_TEMP_NTC_OPENWIRE_SC01 m6 : 42|1@0+ (1,0) [0|0] ""  PT
 SG_ BIT_TEMP_NTC_SHORT_SC01 m6 : 43|1@0+ (1,0) [0|0] ""  PT
 SG_ BIT_TEMP_PLAUSIBILITY_SC01 m6 : 44|1@0+ (1,0) [0|0] ""  PT
 SG_ BIT_VOLTAGE_BRICKV_INVALID_SC01 m7 : 8|1@0+ (1,0) [0|0] ""  PT
 SG_ BIT_VOLTAGE_BRICKUV_SC01 m7 : 9|1@0+ (1,0) [0|0] ""  PT
 SG_ BIT_VOLTAGE_BRICKOV_SC01 m7 : 10|1@0+ (1,0) [0|0] ""  PT
 SG_ BIT_VOLTAGE_BRICKDEEPDSCHG_SC01 m7 : 11|1@0+ (1,0) [0|0] ""  PT
 SG_ BIT_VOLTAGE_PACKV_INVALID_SC01 m7 : 12|1@0+ (1,0) [0|0] ""  PT
 SG_ BIT_VOLTAGE_PLAUSIBILITY_SC01 m7 : 13|1@0+ (1,0) [0|0] ""  PT
 SG_ BIT_VOLTAGE_CMB_PLAUSI_SC01 m7 : 14|1@0+ (1,0) [0|0] ""  PT
 SG_ BIT_VOLTAGE_SENSE_OPENWIRE_SC01 m7 : 15|1@0+ (1,0) [0|0] ""  PT
 SG_ BIT_VOLTAGE_BRICKV_FROZEN_SC01 m7 : 16|1@0+ (1,0) [0|0] ""  PT
 SG_ BIT_PUMP_BLOCK_SC01 m8 : 13|1@0+ (1,0) [0|0] ""  PT
 SG_ BIT_PUMP_SUPPLY_SC01 m8 : 14|1@0+ (1,0) [0|0] ""  PT
 SG_ BIT_PUMP_OVERCURRENT_SC01 m8 : 15|1@0+ (1,0) [0|0] ""  PT
 SG_ BIT_PUMP_ELECTRIC_SC01 m8 : 16|1@0+ (1,0) [0|0] ""  PT
 SG_ BIT_PUMP_RS_SC01 m8 : 17|1@0+ (1,0) [0|0] ""  PT
 SG_ BIT_HALL_PWR_FAIL_HI_SC01 m5 : 28|1@0+ (1,0) [0|0] ""  PT
 SG_ BIT_VOLTAGE_OUT_OF_RANGE_SC01 m7 : 17|1@0+ (1,0) [0|0] ""  PT
 SG_ BIT_ISO_OFF_TIME_SHORT_SC01 m8 : 24|1@0+ (1,0) [0|0] ""  PT
 SG_ BIT_ISO_ON_TIME_SHORT_SC01 m8 : 25|1@0+ (1,0) [0|0] ""  PT
 SG_ BIT_ISO_INTERNAL_INACTIVE_SC01 m8 : 26|1@0+ (1,0) [0|0] ""  PT
 SG_ BIT_ISO_SW_STATE_INVALID_SC01 m8 : 27|1@0+ (1,0) [0|0] ""  PT
 SG_ BIT_ISO_PACKV_SNA_SWOFF_SC01 m8 : 28|1@0+ (1,0) [0|0] ""  PT
 SG_ BIT_ISO_PACKV_SNA_SWON_SC01 m8 : 29|1@0+ (1,0) [0|0] ""  PT
 SG_ BIT_ISO_EXTERNAL_INACTIVE_SC01 m8 : 30|1@0+ (1,0) [0|0] ""  PT
 SG_ BIT_CANTX_CNTR_STAT_FAULT_SC01 m8 : 40|1@0+ (1,0) [0|0] ""  PT
 SG_ BIT_CANTX_CNTR_WELD_FAULT_SC01 m8 : 41|1@0+ (1,0) [0|0] ""  PT
 SG_ BIT_CANTX_THERMAL_FAULT_SC01 m8 : 42|1@0+ (1,0) [0|0] ""  PT
 SG_ BIT_CANTX_ISOLATION_FAULT_SC01 m8 : 43|1@0+ (1,0) [0|0] ""  PT
 SG_ BIT_CANTX_HVIL_FAULT_SC01 m8 : 44|1@0+ (1,0) [0|0] ""  PT
 SG_ BIT_VOLTAGE_STATELATCHED_SC01 m7 : 18|1@0+ (1,0) [0|0] ""  PT
 SG_ BIT_CANTX_ISOLATION_PREFLT_SC01 m8 : 45|1@0+ (1,0) [0|0] ""  PT
 SG_ BIT_CANTX_FLTRIGGER_FAILED_SC01 m8 : 46|1@0+ (1,0) [0|0] ""  PT
 SG_ BIT_ISO_TEST_SWITCH_FAULT_SC01 m8 : 31|1@0+ (1,0) [0|0] ""  PT
 SG_ BIT_THERMAL_ADC_FAULT_SC01 m9 : 8|1@0+ (1,0) [0|0] ""  PT
 SG_ BIT_THERMAL_PRESSURE_VHI_SC01 m9 : 9|1@0+ (1,0) [0|0] ""  PT
 SG_ BIT_THERMAL_PRESSURE_VLO_SC01 m9 : 10|1@0+ (1,0) [0|0] ""  PT
 SG_ BIT_THERMAL_PRIMARY_EVT_SC01 m9 : 11|1@0+ (1,0) [0|0] ""  PT
 SG_ BIT_THERMAL_SECONRY_EVT_SC01 m9 : 12|1@0+ (1,0) [0|0] ""  PT
 SG_ BIT_THERMAL_PRESSURE_INV_SC01 m9 : 13|1@0+ (1,0) [0|0] ""  PT
 SG_ BIT_THERMAL_EVTLATCHED_SC01 m9 : 14|1@0+ (1,0) [0|0] ""  PT
 SG_ BIT_COOLANT_CANMIA_SC01 m9 : 24|1@0+ (1,0) [0|0] ""  PT
 SG_ BIT_COOLANT_SENSRFAIL_SC01 m9 : 25|1@0+ (1,0) [0|0] ""  PT
 SG_ BIT_COOLANT_WATERDETCD_SC01 m9 : 26|1@0+ (1,0) [0|0] ""  PT
 SG_ BIT_COOLANT_LATCHED_SC01 m9 : 27|1@0+ (1,0) [0|0] ""  PT
 SG_ BIT_ANALOG_PULLUP_DSBLD_SC01 m3 : 17|1@0+ (1,0) [0|0] ""  PT
 SG_ BIT_ANALOG_PULLUP_DSBLRQ_SC01 m3 : 16|1@0+ (1,0) [0|0] ""  PT
 SG_ BIT_SBC_REG_ERROR_SC01 m6 : 23|1@0+ (1,0) [0|0] ""  PT
 SG_ BIT_CURRENT_LATCHED_SC01 m4 : 50|1@0+ (1,0) [0|0] ""  PT
 SG_ BIT_TEMP_LATCHED_SC01 m6 : 45|1@0+ (1,0) [0|0] ""  PT
 SG_ BIT_ISO_PLAUSI_SWOFF_SC01 m8 : 32|1@0+ (1,0) [0|0] ""  PT
 SG_ BIT_ISO_PLAUSI_SWON_SC01 m8 : 33|1@0+ (1,0) [0|0] ""  PT
 SG_ BIT_ISO_RELAXED_INACTIVE_SC01 m8 : 34|1@0+ (1,0) [0|0] ""  PT
 SG_ BIT_THERMAL_PRESSURE_MIA_SC01 m9 : 15|1@0+ (1,0) [0|0] ""  PT
 SG_ BIT_LINK_PACK_MISMATCH_SC01 m7 : 42|1@0+ (1,0) [0|0] ""  PT
 SG_ BIT_CAN_PT_EMERGENCY_SC01 m3 : 34|1@0+ (1,0) [0|0] ""  PT

BO_ 1920 BMS01_DebugOnboard: 7 BMS01
 SG_ cmbOnboardPressure32_BMS01 m32 : 39|16@0+ (1,0) [0|600] "kPa"  PT
 SG_ cmbOnboardPressure31_BMS01 m31 : 39|16@0+ (1,0) [0|600] "kPa"  PT
 SG_ cmbOnboardPressure30_BMS01 m30 : 39|16@0+ (1,0) [0|600] "kPa"  PT
 SG_ cmbOnboardPressure29_BMS01 m29 : 39|16@0+ (1,0) [0|600] "kPa"  PT
 SG_ cmbOnboardPressure28_BMS01 m28 : 39|16@0+ (1,0) [0|600] "kPa"  PT
 SG_ cmbOnboardPressure27_BMS01 m27 : 39|16@0+ (1,0) [0|600] "kPa"  PT
 SG_ cmbOnboardPressure26_BMS01 m26 : 39|16@0+ (1,0) [0|600] "kPa"  PT
 SG_ cmbOnboardPressure25_BMS01 m25 : 39|16@0+ (1,0) [0|600] "kPa"  PT
 SG_ cmbOnboardPressure24_BMS01 m24 : 39|16@0+ (1,0) [0|600] "kPa"  PT
 SG_ cmbOnboardPressure23_BMS01 m23 : 39|16@0+ (1,0) [0|600] "kPa"  PT
 SG_ cmbOnboardPressure22_BMS01 m22 : 39|16@0+ (1,0) [0|600] "kPa"  PT
 SG_ cmbOnboardPressure21_BMS01 m21 : 39|16@0+ (1,0) [0|600] "kPa"  PT
 SG_ cmbOnboardPressure20_BMS01 m20 : 39|16@0+ (1,0) [0|600] "kPa"  PT
 SG_ cmbOnboardPressure19_BMS01 m19 : 39|16@0+ (1,0) [0|600] "kPa"  PT
 SG_ cmbOnboardPressure18_BMS01 m18 : 39|16@0+ (1,0) [0|600] "kPa"  PT
 SG_ cmbOnboardPressure17_BMS01 m17 : 39|16@0+ (1,0) [0|600] "kPa"  PT
 SG_ cmbOnboardPressure16_BMS01 m16 : 39|16@0+ (1,0) [0|600] "kPa"  PT
 SG_ cmbOnboardPressure15_BMS01 m15 : 39|16@0+ (1,0) [0|600] "kPa"  PT
 SG_ cmbOnboardPressure14_BMS01 m14 : 39|16@0+ (1,0) [0|600] "kPa"  PT
 SG_ cmbOnboardPressure13_BMS01 m13 : 39|16@0+ (1,0) [0|600] "kPa"  PT
 SG_ cmbOnboardPressure12_BMS01 m12 : 39|16@0+ (1,0) [0|600] "kPa"  PT
 SG_ cmbOnboardPressure11_BMS01 m11 : 39|16@0+ (1,0) [0|600] "kPa"  PT
 SG_ cmbOnboardPressure10_BMS01 m10 : 39|16@0+ (1,0) [0|600] "kPa"  PT
 SG_ cmbOnboardPressure09_BMS01 m9 : 39|16@0+ (1,0) [0|600] "kPa"  PT
 SG_ cmbOnboardPressure08_BMS01 m8 : 39|16@0+ (1,0) [0|600] "kPa"  PT
 SG_ cmbOnboardPressure07_BMS01 m7 : 39|16@0+ (1,0) [0|600] "kPa"  PT
 SG_ cmbOnboardPressure06_BMS01 m6 : 39|16@0+ (1,0) [0|600] "kPa"  PT
 SG_ cmbOnboardPressure05_BMS01 m5 : 39|16@0+ (1,0) [0|600] "kPa"  PT
 SG_ cmbOnboardPressure04_BMS01 m4 : 39|16@0+ (1,0) [0|600] "kPa"  PT
 SG_ cmbOnboardPressure03_BMS01 m3 : 39|16@0+ (1,0) [0|600] "kPa"  PT
 SG_ cmbOnboardPressure02_BMS01 m2 : 39|16@0+ (1,0) [0|600] "kPa"  PT
 SG_ cmbOnboardPressure01_BMS01 m1 : 39|16@0+ (1,0) [0|600] "kPa"  PT
 SG_ onboardMultiplexor_BMS01 M : 7|8@0+ (1,0) [0|0] ""  PT
 SG_ minCmbOnboardTemperature_BMS01 m0 : 31|8@0+ (1,-40) [-40|200] "C"  PT
 SG_ minCmbOnboardHumidity_BMS01 m0 : 47|8@0+ (0.5,0) [0|120] "PCT"  PT
 SG_ maxCmbOnboardTemperature_BMS01 m0 : 39|8@0+ (1,-40) [-40|200] "C"  PT
 SG_ maxCmbOnboardHumidity_BMS01 m0 : 55|8@0+ (0.5,0) [0|120] "PCT"  PT
 SG_ bmsOnboardTemperature_BMS01 m0 : 15|8@0+ (1,-40) [-40|200] "C"  PT
 SG_ bmsOnboardHumidity_BMS01 m0 : 23|8@0+ (0.5,0) [0|120] "PCT"  PT
 SG_ cmbOnboardTemperature01_BMS01 m1 : 15|8@0+ (1,-40) [-40|200] "C"  PT
 SG_ cmbOnboardHumidity01_BMS01 m1 : 23|8@0+ (0.5,0) [0|120] "PCT"  PT
 SG_ moduleHeaterCurrent01_BMS01 m1 : 31|8@0+ (0.05,0) [0|10] "A"  PT
 SG_ cmbOnboardTemperature02_BMS01 m2 : 15|8@0+ (1,-40) [-40|200] "C"  PT
 SG_ cmbOnboardHumidity02_BMS01 m2 : 23|8@0+ (0.5,0) [0|120] "PCT"  PT
 SG_ moduleHeaterCurrent02_BMS01 m2 : 31|8@0+ (0.05,0) [0|10] "A"  PT
 SG_ cmbOnboardTemperature03_BMS01 m3 : 15|8@0+ (1,-40) [-40|200] "C"  PT
 SG_ cmbOnboardHumidity03_BMS01 m3 : 23|8@0+ (0.5,0) [0|120] "PCT"  PT
 SG_ moduleHeaterCurrent03_BMS01 m3 : 31|8@0+ (0.05,0) [0|10] "A"  PT
 SG_ cmbOnboardTemperature04_BMS01 m4 : 15|8@0+ (1,-40) [-40|200] "C"  PT
 SG_ cmbOnboardHumidity04_BMS01 m4 : 23|8@0+ (0.5,0) [0|120] "PCT"  PT
 SG_ moduleHeaterCurrent04_BMS01 m4 : 31|8@0+ (0.05,0) [0|10] "A"  PT
 SG_ cmbOnboardTemperature05_BMS01 m5 : 15|8@0+ (1,-40) [-40|200] "C"  PT
 SG_ cmbOnboardHumidity05_BMS01 m5 : 23|8@0+ (0.5,0) [0|120] "PCT"  PT
 SG_ moduleHeaterCurrent05_BMS01 m5 : 31|8@0+ (0.05,0) [0|10] "A"  PT
 SG_ cmbOnboardTemperature06_BMS01 m6 : 15|8@0+ (1,-40) [-40|200] "C"  PT
 SG_ cmbOnboardHumidity06_BMS01 m6 : 23|8@0+ (0.5,0) [0|120] "PCT"  PT
 SG_ moduleHeaterCurrent06_BMS01 m6 : 31|8@0+ (0.05,0) [0|10] "A"  PT
 SG_ cmbOnboardTemperature07_BMS01 m7 : 15|8@0+ (1,-40) [-40|200] "C"  PT
 SG_ cmbOnboardHumidity07_BMS01 m7 : 23|8@0+ (0.5,0) [0|120] "PCT"  PT
 SG_ moduleHeaterCurrent07_BMS01 m7 : 31|8@0+ (0.05,0) [0|10] "A"  PT
 SG_ cmbOnboardTemperature08_BMS01 m8 : 15|8@0+ (1,-40) [-40|200] "C"  PT
 SG_ cmbOnboardHumidity08_BMS01 m8 : 23|8@0+ (0.5,0) [0|120] "PCT"  PT
 SG_ moduleHeaterCurrent08_BMS01 m8 : 31|8@0+ (0.05,0) [0|10] "A"  PT
 SG_ cmbOnboardTemperature09_BMS01 m9 : 15|8@0+ (1,-40) [-40|200] "C"  PT
 SG_ cmbOnboardHumidity09_BMS01 m9 : 23|8@0+ (0.5,0) [0|120] "PCT"  PT
 SG_ moduleHeaterCurrent09_BMS01 m9 : 31|8@0+ (0.05,0) [0|10] "A"  PT
 SG_ cmbOnboardTemperature10_BMS01 m10 : 15|8@0+ (1,-40) [-40|200] "C"  PT
 SG_ cmbOnboardHumidity10_BMS01 m10 : 23|8@0+ (0.5,0) [0|120] "PCT"  PT
 SG_ moduleHeaterCurrent10_BMS01 m10 : 31|8@0+ (0.05,0) [0|10] "A"  PT
 SG_ cmbOnboardTemperature11_BMS01 m11 : 15|8@0+ (1,-40) [-40|200] "C"  PT
 SG_ cmbOnboardHumidity11_BMS01 m11 : 23|8@0+ (0.5,0) [0|120] "PCT"  PT
 SG_ moduleHeaterCurrent11_BMS01 m11 : 31|8@0+ (0.05,0) [0|10] "A"  PT
 SG_ cmbOnboardTemperature12_BMS01 m12 : 15|8@0+ (1,-40) [-40|200] "C"  PT
 SG_ cmbOnboardHumidity12_BMS01 m12 : 23|8@0+ (0.5,0) [0|120] "PCT"  PT
 SG_ moduleHeaterCurrent12_BMS01 m12 : 31|8@0+ (0.05,0) [0|10] "A"  PT
 SG_ cmbOnboardTemperature13_BMS01 m13 : 15|8@0+ (1,-40) [-40|200] "C"  PT
 SG_ cmbOnboardHumidity13_BMS01 m13 : 23|8@0+ (0.5,0) [0|120] "PCT"  PT
 SG_ moduleHeaterCurrent13_BMS01 m13 : 31|8@0+ (0.05,0) [0|10] "A"  PT
 SG_ cmbOnboardTemperature14_BMS01 m14 : 15|8@0+ (1,-40) [-40|200] "C"  PT
 SG_ cmbOnboardHumidity14_BMS01 m14 : 23|8@0+ (0.5,0) [0|120] "PCT"  PT
 SG_ moduleHeaterCurrent14_BMS01 m14 : 31|8@0+ (0.05,0) [0|10] "A"  PT
 SG_ cmbOnboardTemperature15_BMS01 m15 : 15|8@0+ (1,-40) [-40|200] "C"  PT
 SG_ cmbOnboardHumidity15_BMS01 m15 : 23|8@0+ (0.5,0) [0|120] "PCT"  PT
 SG_ moduleHeaterCurrent15_BMS01 m15 : 31|8@0+ (0.05,0) [0|10] "A"  PT
 SG_ cmbOnboardTemperature16_BMS01 m16 : 15|8@0+ (1,-40) [-40|200] "C"  PT
 SG_ cmbOnboardHumidity16_BMS01 m16 : 23|8@0+ (0.5,0) [0|120] "PCT"  PT
 SG_ moduleHeaterCurrent16_BMS01 m16 : 31|8@0+ (0.05,0) [0|10] "A"  PT
 SG_ cmbOnboardTemperature17_BMS01 m17 : 15|8@0+ (1,-40) [-40|200] "C"  PT
 SG_ cmbOnboardHumidity17_BMS01 m17 : 23|8@0+ (0.5,0) [0|120] "PCT"  PT
 SG_ moduleHeaterCurrent17_BMS01 m17 : 31|8@0+ (0.05,0) [0|10] "A"  PT
 SG_ cmbOnboardTemperature18_BMS01 m18 : 15|8@0+ (1,-40) [-40|200] "C"  PT
 SG_ cmbOnboardHumidity18_BMS01 m18 : 23|8@0+ (0.5,0) [0|120] "PCT"  PT
 SG_ moduleHeaterCurrent18_BMS01 m18 : 31|8@0+ (0.05,0) [0|10] "A"  PT
 SG_ cmbOnboardTemperature19_BMS01 m19 : 15|8@0+ (1,-40) [-40|200] "C"  PT
 SG_ cmbOnboardHumidity19_BMS01 m19 : 23|8@0+ (0.5,0) [0|120] "PCT"  PT
 SG_ moduleHeaterCurrent19_BMS01 m19 : 31|8@0+ (0.05,0) [0|10] "A"  PT
 SG_ cmbOnboardTemperature20_BMS01 m20 : 15|8@0+ (1,-40) [-40|200] "C"  PT
 SG_ cmbOnboardHumidity20_BMS01 m20 : 23|8@0+ (0.5,0) [0|120] "PCT"  PT
 SG_ moduleHeaterCurrent20_BMS01 m20 : 31|8@0+ (0.05,0) [0|10] "A"  PT
 SG_ cmbOnboardTemperature21_BMS01 m21 : 15|8@0+ (1,-40) [-40|200] "C"  PT
 SG_ cmbOnboardHumidity21_BMS01 m21 : 23|8@0+ (0.5,0) [0|120] "PCT"  PT
 SG_ moduleHeaterCurrent21_BMS01 m21 : 31|8@0+ (0.05,0) [0|10] "A"  PT
 SG_ cmbOnboardTemperature22_BMS01 m22 : 15|8@0+ (1,-40) [-40|200] "C"  PT
 SG_ cmbOnboardHumidity22_BMS01 m22 : 23|8@0+ (0.5,0) [0|120] "PCT"  PT
 SG_ moduleHeaterCurrent22_BMS01 m22 : 31|8@0+ (0.05,0) [0|10] "A"  PT
 SG_ cmbOnboardTemperature23_BMS01 m23 : 15|8@0+ (1,-40) [-40|200] "C"  PT
 SG_ cmbOnboardHumidity23_BMS01 m23 : 23|8@0+ (0.5,0) [0|120] "PCT"  PT
 SG_ moduleHeaterCurrent23_BMS01 m23 : 31|8@0+ (0.05,0) [0|10] "A"  PT
 SG_ cmbOnboardTemperature24_BMS01 m24 : 15|8@0+ (1,-40) [-40|200] "C"  PT
 SG_ cmbOnboardHumidity24_BMS01 m24 : 23|8@0+ (0.5,0) [0|120] "PCT"  PT
 SG_ moduleHeaterCurrent24_BMS01 m24 : 31|8@0+ (0.05,0) [0|10] "A"  PT
 SG_ cmbOnboardTemperature25_BMS01 m25 : 15|8@0+ (1,-40) [-40|200] "C"  PT
 SG_ cmbOnboardHumidity25_BMS01 m25 : 23|8@0+ (0.5,0) [0|120] "PCT"  PT
 SG_ moduleHeaterCurrent25_BMS01 m25 : 31|8@0+ (0.05,0) [0|10] "A"  PT
 SG_ cmbOnboardTemperature26_BMS01 m26 : 15|8@0+ (1,-40) [-40|200] "C"  PT
 SG_ cmbOnboardHumidity26_BMS01 m26 : 23|8@0+ (0.5,0) [0|120] "PCT"  PT
 SG_ moduleHeaterCurrent26_BMS01 m26 : 31|8@0+ (0.05,0) [0|10] "A"  PT
 SG_ cmbOnboardTemperature27_BMS01 m27 : 15|8@0+ (1,-40) [-40|200] "C"  PT
 SG_ cmbOnboardHumidity27_BMS01 m27 : 23|8@0+ (0.5,0) [0|120] "PCT"  PT
 SG_ moduleHeaterCurrent27_BMS01 m27 : 31|8@0+ (0.05,0) [0|10] "A"  PT
 SG_ cmbOnboardTemperature28_BMS01 m28 : 15|8@0+ (1,-40) [-40|200] "C"  PT
 SG_ cmbOnboardHumidity28_BMS01 m28 : 23|8@0+ (0.5,0) [0|120] "PCT"  PT
 SG_ moduleHeaterCurrent28_BMS01 m28 : 31|8@0+ (0.05,0) [0|10] "A"  PT
 SG_ cmbOnboardTemperature29_BMS01 m29 : 15|8@0+ (1,-40) [-40|200] "C"  PT
 SG_ cmbOnboardHumidity29_BMS01 m29 : 23|8@0+ (0.5,0) [0|120] "PCT"  PT
 SG_ moduleHeaterCurrent29_BMS01 m29 : 31|8@0+ (0.05,0) [0|10] "A"  PT
 SG_ cmbOnboardTemperature30_BMS01 m30 : 15|8@0+ (1,-40) [-40|200] "C"  PT
 SG_ cmbOnboardHumidity30_BMS01 m30 : 23|8@0+ (0.5,0) [0|120] "PCT"  PT
 SG_ moduleHeaterCurrent30_BMS01 m30 : 31|8@0+ (0.05,0) [0|10] "A"  PT
 SG_ cmbOnboardTemperature31_BMS01 m31 : 15|8@0+ (1,-40) [-40|200] "C"  PT
 SG_ cmbOnboardHumidity31_BMS01 m31 : 23|8@0+ (0.5,0) [0|120] "PCT"  PT
 SG_ moduleHeaterCurrent31_BMS01 m31 : 31|8@0+ (0.05,0) [0|10] "A"  PT
 SG_ cmbOnboardTemperature32_BMS01 m32 : 15|8@0+ (1,-40) [-40|200] "C"  PT
 SG_ cmbOnboardHumidity32_BMS01 m32 : 23|8@0+ (0.5,0) [0|120] "PCT"  PT
 SG_ moduleHeaterCurrent32_BMS01 m32 : 31|8@0+ (0.05,0) [0|10] "A"  PT

BO_ 1984 BMS01_DebugCMB: 8 BMS01
 SG_ cmbMultiplexor_BMS01 M : 7|8@0+ (1,0) [0|0] ""  PT
 SG_ moduleTemperature01_BMS01 m1 : 15|8@0+ (1,-40) [-40|200] "C"  PT
 SG_ brickVoltage001_BMS01 m1 : 23|16@0+ (0.0001,0) [0|6.5] "V"  PT
 SG_ brickVoltage002_BMS01 m1 : 39|16@0+ (0.0001,0) [0|6.5] "V"  PT
 SG_ brickVoltage003_BMS01 m1 : 55|16@0+ (0.0001,0) [0|6.5] "V"  PT
 SG_ moduleTemperature02_BMS01 m2 : 15|8@0+ (1,-40) [-40|200] "C"  PT
 SG_ brickVoltage004_BMS01 m2 : 23|16@0+ (0.0001,0) [0|6.5] "V"  PT
 SG_ brickVoltage005_BMS01 m2 : 39|16@0+ (0.0001,0) [0|6.5] "V"  PT
 SG_ brickVoltage006_BMS01 m2 : 55|16@0+ (0.0001,0) [0|6.5] "V"  PT
 SG_ moduleTemperature03_BMS01 m3 : 15|8@0+ (1,-40) [-40|200] "C"  PT
 SG_ brickVoltage007_BMS01 m3 : 23|16@0+ (0.0001,0) [0|6.5] "V"  PT
 SG_ brickVoltage008_BMS01 m3 : 39|16@0+ (0.0001,0) [0|6.5] "V"  PT
 SG_ brickVoltage009_BMS01 m3 : 55|16@0+ (0.0001,0) [0|6.5] "V"  PT
 SG_ moduleTemperature04_BMS01 m4 : 15|8@0+ (1,-40) [-40|200] "C"  PT
 SG_ brickVoltage010_BMS01 m4 : 23|16@0+ (0.0001,0) [0|6.5] "V"  PT
 SG_ brickVoltage011_BMS01 m4 : 39|16@0+ (0.0001,0) [0|6.5] "V"  PT
 SG_ brickVoltage012_BMS01 m4 : 55|16@0+ (0.0001,0) [0|6.5] "V"  PT
 SG_ moduleTemperature05_BMS01 m5 : 15|8@0+ (1,-40) [-40|200] "C"  PT
 SG_ brickVoltage013_BMS01 m5 : 23|16@0+ (0.0001,0) [0|6.5] "V"  PT
 SG_ brickVoltage014_BMS01 m5 : 39|16@0+ (0.0001,0) [0|6.5] "V"  PT
 SG_ brickVoltage015_BMS01 m5 : 55|16@0+ (0.0001,0) [0|6.5] "V"  PT
 SG_ moduleTemperature06_BMS01 m6 : 15|8@0+ (1,-40) [-40|200] "C"  PT
 SG_ brickVoltage016_BMS01 m6 : 23|16@0+ (0.0001,0) [0|6.5] "V"  PT
 SG_ brickVoltage017_BMS01 m6 : 39|16@0+ (0.0001,0) [0|6.5] "V"  PT
 SG_ brickVoltage018_BMS01 m6 : 55|16@0+ (0.0001,0) [0|6.5] "V"  PT
 SG_ moduleTemperature07_BMS01 m7 : 15|8@0+ (1,-40) [-40|200] "C"  PT
 SG_ brickVoltage019_BMS01 m7 : 23|16@0+ (0.0001,0) [0|6.5] "V"  PT
 SG_ brickVoltage020_BMS01 m7 : 39|16@0+ (0.0001,0) [0|6.5] "V"  PT
 SG_ brickVoltage021_BMS01 m7 : 55|16@0+ (0.0001,0) [0|6.5] "V"  PT
 SG_ moduleTemperature08_BMS01 m8 : 15|8@0+ (1,-40) [-40|200] "C"  PT
 SG_ brickVoltage022_BMS01 m8 : 23|16@0+ (0.0001,0) [0|6.5] "V"  PT
 SG_ brickVoltage023_BMS01 m8 : 39|16@0+ (0.0001,0) [0|6.5] "V"  PT
 SG_ brickVoltage024_BMS01 m8 : 55|16@0+ (0.0001,0) [0|6.5] "V"  PT
 SG_ moduleTemperature09_BMS01 m9 : 15|8@0+ (1,-40) [-40|200] "C"  PT
 SG_ brickVoltage025_BMS01 m9 : 23|16@0+ (0.0001,0) [0|6.5] "V"  PT
 SG_ brickVoltage026_BMS01 m9 : 39|16@0+ (0.0001,0) [0|6.5] "V"  PT
 SG_ brickVoltage027_BMS01 m9 : 55|16@0+ (0.0001,0) [0|6.5] "V"  PT
 SG_ moduleTemperature10_BMS01 m10 : 15|8@0+ (1,-40) [-40|200] "C"  PT
 SG_ brickVoltage028_BMS01 m10 : 23|16@0+ (0.0001,0) [0|6.5] "V"  PT
 SG_ brickVoltage029_BMS01 m10 : 39|16@0+ (0.0001,0) [0|6.5] "V"  PT
 SG_ brickVoltage030_BMS01 m10 : 55|16@0+ (0.0001,0) [0|6.5] "V"  PT
 SG_ moduleTemperature11_BMS01 m11 : 15|8@0+ (1,-40) [-40|200] "C"  PT
 SG_ brickVoltage031_BMS01 m11 : 23|16@0+ (0.0001,0) [0|6.5] "V"  PT
 SG_ brickVoltage032_BMS01 m11 : 39|16@0+ (0.0001,0) [0|6.5] "V"  PT
 SG_ brickVoltage033_BMS01 m11 : 55|16@0+ (0.0001,0) [0|6.5] "V"  PT
 SG_ moduleTemperature12_BMS01 m12 : 15|8@0+ (1,-40) [-40|200] "C"  PT
 SG_ brickVoltage034_BMS01 m12 : 23|16@0+ (0.0001,0) [0|6.5] "V"  PT
 SG_ brickVoltage035_BMS01 m12 : 39|16@0+ (0.0001,0) [0|6.5] "V"  PT
 SG_ brickVoltage036_BMS01 m12 : 55|16@0+ (0.0001,0) [0|6.5] "V"  PT
 SG_ moduleTemperature13_BMS01 m13 : 15|8@0+ (1,-40) [-40|200] "C"  PT
 SG_ brickVoltage037_BMS01 m13 : 23|16@0+ (0.0001,0) [0|6.5] "V"  PT
 SG_ brickVoltage038_BMS01 m13 : 39|16@0+ (0.0001,0) [0|6.5] "V"  PT
 SG_ brickVoltage039_BMS01 m13 : 55|16@0+ (0.0001,0) [0|6.5] "V"  PT
 SG_ moduleTemperature14_BMS01 m14 : 15|8@0+ (1,-40) [-40|200] "C"  PT
 SG_ brickVoltage040_BMS01 m14 : 23|16@0+ (0.0001,0) [0|6.5] "V"  PT
 SG_ brickVoltage041_BMS01 m14 : 39|16@0+ (0.0001,0) [0|6.5] "V"  PT
 SG_ brickVoltage042_BMS01 m14 : 55|16@0+ (0.0001,0) [0|6.5] "V"  PT
 SG_ moduleTemperature15_BMS01 m15 : 15|8@0+ (1,-40) [-40|200] "C"  PT
 SG_ brickVoltage043_BMS01 m15 : 23|16@0+ (0.0001,0) [0|6.5] "V"  PT
 SG_ brickVoltage044_BMS01 m15 : 39|16@0+ (0.0001,0) [0|6.5] "V"  PT
 SG_ brickVoltage045_BMS01 m15 : 55|16@0+ (0.0001,0) [0|6.5] "V"  PT
 SG_ moduleTemperature16_BMS01 m16 : 15|8@0+ (1,-40) [-40|200] "C"  PT
 SG_ brickVoltage046_BMS01 m16 : 23|16@0+ (0.0001,0) [0|6.5] "V"  PT
 SG_ brickVoltage047_BMS01 m16 : 39|16@0+ (0.0001,0) [0|6.5] "V"  PT
 SG_ brickVoltage048_BMS01 m16 : 55|16@0+ (0.0001,0) [0|6.5] "V"  PT
 SG_ moduleTemperature17_BMS01 m17 : 15|8@0+ (1,-40) [-40|200] "C"  PT
 SG_ brickVoltage049_BMS01 m17 : 23|16@0+ (0.0001,0) [0|6.5] "V"  PT
 SG_ brickVoltage050_BMS01 m17 : 39|16@0+ (0.0001,0) [0|6.5] "V"  PT
 SG_ brickVoltage051_BMS01 m17 : 55|16@0+ (0.0001,0) [0|6.5] "V"  PT
 SG_ moduleTemperature18_BMS01 m18 : 15|8@0+ (1,-40) [-40|200] "C"  PT
 SG_ brickVoltage052_BMS01 m18 : 23|16@0+ (0.0001,0) [0|6.5] "V"  PT
 SG_ brickVoltage053_BMS01 m18 : 39|16@0+ (0.0001,0) [0|6.5] "V"  PT
 SG_ brickVoltage054_BMS01 m18 : 55|16@0+ (0.0001,0) [0|6.5] "V"  PT
 SG_ moduleTemperature19_BMS01 m19 : 15|8@0+ (1,-40) [-40|200] "C"  PT
 SG_ brickVoltage055_BMS01 m19 : 23|16@0+ (0.0001,0) [0|6.5] "V"  PT
 SG_ brickVoltage056_BMS01 m19 : 39|16@0+ (0.0001,0) [0|6.5] "V"  PT
 SG_ brickVoltage057_BMS01 m19 : 55|16@0+ (0.0001,0) [0|6.5] "V"  PT
 SG_ moduleTemperature20_BMS01 m20 : 15|8@0+ (1,-40) [-40|200] "C"  PT
 SG_ brickVoltage058_BMS01 m20 : 23|16@0+ (0.0001,0) [0|6.5] "V"  PT
 SG_ brickVoltage059_BMS01 m20 : 39|16@0+ (0.0001,0) [0|6.5] "V"  PT
 SG_ brickVoltage060_BMS01 m20 : 55|16@0+ (0.0001,0) [0|6.5] "V"  PT
 SG_ moduleTemperature21_BMS01 m21 : 15|8@0+ (1,-40) [-40|200] "C"  PT
 SG_ brickVoltage061_BMS01 m21 : 23|16@0+ (0.0001,0) [0|6.5] "V"  PT
 SG_ brickVoltage062_BMS01 m21 : 39|16@0+ (0.0001,0) [0|6.5] "V"  PT
 SG_ brickVoltage063_BMS01 m21 : 55|16@0+ (0.0001,0) [0|6.5] "V"  PT
 SG_ moduleTemperature22_BMS01 m22 : 15|8@0+ (1,-40) [-40|200] "C"  PT
 SG_ brickVoltage064_BMS01 m22 : 23|16@0+ (0.0001,0) [0|6.5] "V"  PT
 SG_ brickVoltage065_BMS01 m22 : 39|16@0+ (0.0001,0) [0|6.5] "V"  PT
 SG_ brickVoltage066_BMS01 m22 : 55|16@0+ (0.0001,0) [0|6.5] "V"  PT
 SG_ moduleTemperature23_BMS01 m23 : 15|8@0+ (1,-40) [-40|200] "C"  PT
 SG_ brickVoltage067_BMS01 m23 : 23|16@0+ (0.0001,0) [0|6.5] "V"  PT
 SG_ brickVoltage068_BMS01 m23 : 39|16@0+ (0.0001,0) [0|6.5] "V"  PT
 SG_ brickVoltage069_BMS01 m23 : 55|16@0+ (0.0001,0) [0|6.5] "V"  PT
 SG_ moduleTemperature24_BMS01 m24 : 15|8@0+ (1,-40) [-40|200] "C"  PT
 SG_ brickVoltage070_BMS01 m24 : 23|16@0+ (0.0001,0) [0|6.5] "V"  PT
 SG_ brickVoltage071_BMS01 m24 : 39|16@0+ (0.0001,0) [0|6.5] "V"  PT
 SG_ brickVoltage072_BMS01 m24 : 55|16@0+ (0.0001,0) [0|6.5] "V"  PT
 SG_ moduleTemperature25_BMS01 m25 : 15|8@0+ (1,-40) [-40|200] "C"  PT
 SG_ brickVoltage073_BMS01 m25 : 23|16@0+ (0.0001,0) [0|6.5] "V"  PT
 SG_ brickVoltage074_BMS01 m25 : 39|16@0+ (0.0001,0) [0|6.5] "V"  PT
 SG_ brickVoltage075_BMS01 m25 : 55|16@0+ (0.0001,0) [0|6.5] "V"  PT
 SG_ moduleTemperature26_BMS01 m26 : 15|8@0+ (1,-40) [-40|200] "C"  PT
 SG_ brickVoltage076_BMS01 m26 : 23|16@0+ (0.0001,0) [0|6.5] "V"  PT
 SG_ brickVoltage077_BMS01 m26 : 39|16@0+ (0.0001,0) [0|6.5] "V"  PT
 SG_ brickVoltage078_BMS01 m26 : 55|16@0+ (0.0001,0) [0|6.5] "V"  PT
 SG_ moduleTemperature27_BMS01 m27 : 15|8@0+ (1,-40) [-40|200] "C"  PT
 SG_ brickVoltage079_BMS01 m27 : 23|16@0+ (0.0001,0) [0|6.5] "V"  PT
 SG_ brickVoltage080_BMS01 m27 : 39|16@0+ (0.0001,0) [0|6.5] "V"  PT
 SG_ brickVoltage081_BMS01 m27 : 55|16@0+ (0.0001,0) [0|6.5] "V"  PT
 SG_ moduleTemperature28_BMS01 m28 : 15|8@0+ (1,-40) [-40|200] "C"  PT
 SG_ brickVoltage082_BMS01 m28 : 23|16@0+ (0.0001,0) [0|6.5] "V"  PT
 SG_ brickVoltage083_BMS01 m28 : 39|16@0+ (0.0001,0) [0|6.5] "V"  PT
 SG_ brickVoltage084_BMS01 m28 : 55|16@0+ (0.0001,0) [0|6.5] "V"  PT
 SG_ moduleTemperature29_BMS01 m29 : 15|8@0+ (1,-40) [-40|200] "C"  PT
 SG_ brickVoltage085_BMS01 m29 : 23|16@0+ (0.0001,0) [0|6.5] "V"  PT
 SG_ brickVoltage086_BMS01 m29 : 39|16@0+ (0.0001,0) [0|6.5] "V"  PT
 SG_ brickVoltage087_BMS01 m29 : 55|16@0+ (0.0001,0) [0|6.5] "V"  PT
 SG_ moduleTemperature30_BMS01 m30 : 15|8@0+ (1,-40) [-40|200] "C"  PT
 SG_ brickVoltage088_BMS01 m30 : 23|16@0+ (0.0001,0) [0|6.5] "V"  PT
 SG_ brickVoltage089_BMS01 m30 : 39|16@0+ (0.0001,0) [0|6.5] "V"  PT
 SG_ brickVoltage090_BMS01 m30 : 55|16@0+ (0.0001,0) [0|6.5] "V"  PT
 SG_ moduleTemperature31_BMS01 m31 : 15|8@0+ (1,-40) [-40|200] "C"  PT
 SG_ brickVoltage091_BMS01 m31 : 23|16@0+ (0.0001,0) [0|6.5] "V"  PT
 SG_ brickVoltage092_BMS01 m31 : 39|16@0+ (0.0001,0) [0|6.5] "V"  PT
 SG_ brickVoltage093_BMS01 m31 : 55|16@0+ (0.0001,0) [0|6.5] "V"  PT
 SG_ moduleTemperature32_BMS01 m32 : 15|8@0+ (1,-40) [-40|200] "C"  PT
 SG_ brickVoltage094_BMS01 m32 : 23|16@0+ (0.0001,0) [0|6.5] "V"  PT
 SG_ brickVoltage095_BMS01 m32 : 39|16@0+ (0.0001,0) [0|6.5] "V"  PT
 SG_ brickVoltage096_BMS01 m32 : 55|16@0+ (0.0001,0) [0|6.5] "V"  PT
 SG_ brickVoltage097_BMS01 m33 : 23|16@0+ (0.0001,0) [0|6.5] "V"  PT
 SG_ brickVoltage098_BMS01 m33 : 39|16@0+ (0.0001,0) [0|6.5] "V"  PT
 SG_ brickVoltage099_BMS01 m33 : 55|16@0+ (0.0001,0) [0|6.5] "V"  PT
 SG_ brickVoltage100_BMS01 m34 : 23|16@0+ (0.0001,0) [0|6.5] "V"  PT
 SG_ brickVoltage101_BMS01 m34 : 39|16@0+ (0.0001,0) [0|6.5] "V"  PT
 SG_ brickVoltage102_BMS01 m34 : 55|16@0+ (0.0001,0) [0|6.5] "V"  PT
 SG_ brickVoltage103_BMS01 m35 : 23|16@0+ (0.0001,0) [0|6.5] "V"  PT
 SG_ brickVoltage104_BMS01 m35 : 39|16@0+ (0.0001,0) [0|6.5] "V"  PT
 SG_ brickVoltage105_BMS01 m35 : 55|16@0+ (0.0001,0) [0|6.5] "V"  PT
 SG_ brickVoltage106_BMS01 m36 : 23|16@0+ (0.0001,0) [0|6.5] "V"  PT
 SG_ brickVoltage107_BMS01 m36 : 39|16@0+ (0.0001,0) [0|6.5] "V"  PT
 SG_ brickVoltage108_BMS01 m36 : 55|16@0+ (0.0001,0) [0|6.5] "V"  PT
 SG_ brickVoltage109_BMS01 m37 : 23|16@0+ (0.0001,0) [0|6.5] "V"  PT
 SG_ brickVoltage110_BMS01 m37 : 39|16@0+ (0.0001,0) [0|6.5] "V"  PT
 SG_ brickVoltage111_BMS01 m37 : 55|16@0+ (0.0001,0) [0|6.5] "V"  PT
 SG_ brickVoltage112_BMS01 m38 : 23|16@0+ (0.0001,0) [0|6.5] "V"  PT
 SG_ brickVoltage113_BMS01 m38 : 39|16@0+ (0.0001,0) [0|6.5] "V"  PT
 SG_ brickVoltage114_BMS01 m38 : 55|16@0+ (0.0001,0) [0|6.5] "V"  PT
 SG_ brickVoltage115_BMS01 m39 : 23|16@0+ (0.0001,0) [0|6.5] "V"  PT
 SG_ brickVoltage116_BMS01 m39 : 39|16@0+ (0.0001,0) [0|6.5] "V"  PT
 SG_ brickVoltage117_BMS01 m39 : 55|16@0+ (0.0001,0) [0|6.5] "V"  PT
 SG_ brickVoltage118_BMS01 m40 : 23|16@0+ (0.0001,0) [0|6.5] "V"  PT
 SG_ brickVoltage119_BMS01 m40 : 39|16@0+ (0.0001,0) [0|6.5] "V"  PT
 SG_ brickVoltage120_BMS01 m40 : 55|16@0+ (0.0001,0) [0|6.5] "V"  PT
 SG_ brickVoltage121_BMS01 m41 : 23|16@0+ (0.0001,0) [0|6.5] "V"  PT
 SG_ brickVoltage122_BMS01 m41 : 39|16@0+ (0.0001,0) [0|6.5] "V"  PT
 SG_ brickVoltage123_BMS01 m41 : 55|16@0+ (0.0001,0) [0|6.5] "V"  PT
 SG_ brickVoltage124_BMS01 m42 : 23|16@0+ (0.0001,0) [0|6.5] "V"  PT
 SG_ brickVoltage125_BMS01 m42 : 39|16@0+ (0.0001,0) [0|6.5] "V"  PT
 SG_ brickVoltage126_BMS01 m42 : 55|16@0+ (0.0001,0) [0|6.5] "V"  PT
 SG_ brickVoltage127_BMS01 m43 : 23|16@0+ (0.0001,0) [0|6.5] "V"  PT
 SG_ brickVoltage128_BMS01 m43 : 39|16@0+ (0.0001,0) [0|6.5] "V"  PT
 SG_ brickVoltage129_BMS01 m43 : 55|16@0+ (0.0001,0) [0|6.5] "V"  PT
 SG_ brickVoltage130_BMS01 m44 : 23|16@0+ (0.0001,0) [0|6.5] "V"  PT
 SG_ brickVoltage131_BMS01 m44 : 39|16@0+ (0.0001,0) [0|6.5] "V"  PT
 SG_ brickVoltage132_BMS01 m44 : 55|16@0+ (0.0001,0) [0|6.5] "V"  PT
 SG_ brickVoltage133_BMS01 m45 : 23|16@0+ (0.0001,0) [0|6.5] "V"  PT
 SG_ brickVoltage134_BMS01 m45 : 39|16@0+ (0.0001,0) [0|6.5] "V"  PT
 SG_ brickVoltage135_BMS01 m45 : 55|16@0+ (0.0001,0) [0|6.5] "V"  PT
 SG_ brickVoltage136_BMS01 m46 : 23|16@0+ (0.0001,0) [0|6.5] "V"  PT
 SG_ brickVoltage137_BMS01 m46 : 39|16@0+ (0.0001,0) [0|6.5] "V"  PT
 SG_ brickVoltage138_BMS01 m46 : 55|16@0+ (0.0001,0) [0|6.5] "V"  PT
 SG_ brickVoltage139_BMS01 m47 : 23|16@0+ (0.0001,0) [0|6.5] "V"  PT
 SG_ brickVoltage140_BMS01 m47 : 39|16@0+ (0.0001,0) [0|6.5] "V"  PT
 SG_ brickVoltage141_BMS01 m47 : 55|16@0+ (0.0001,0) [0|6.5] "V"  PT
 SG_ brickVoltage142_BMS01 m48 : 23|16@0+ (0.0001,0) [0|6.5] "V"  PT
 SG_ brickVoltage143_BMS01 m48 : 39|16@0+ (0.0001,0) [0|6.5] "V"  PT
 SG_ brickVoltage144_BMS01 m48 : 55|16@0+ (0.0001,0) [0|6.5] "V"  PT
 SG_ brickVoltage145_BMS01 m49 : 23|16@0+ (0.0001,0) [0|6.5] "V"  PT
 SG_ brickVoltage146_BMS01 m49 : 39|16@0+ (0.0001,0) [0|6.5] "V"  PT
 SG_ brickVoltage147_BMS01 m49 : 55|16@0+ (0.0001,0) [0|6.5] "V"  PT
 SG_ brickVoltage148_BMS01 m50 : 23|16@0+ (0.0001,0) [0|6.5] "V"  PT
 SG_ brickVoltage149_BMS01 m50 : 39|16@0+ (0.0001,0) [0|6.5] "V"  PT
 SG_ brickVoltage150_BMS01 m50 : 55|16@0+ (0.0001,0) [0|6.5] "V"  PT
 SG_ brickVoltage151_BMS01 m51 : 23|16@0+ (0.0001,0) [0|6.5] "V"  PT
 SG_ brickVoltage152_BMS01 m51 : 39|16@0+ (0.0001,0) [0|6.5] "V"  PT
 SG_ brickVoltage153_BMS01 m51 : 55|16@0+ (0.0001,0) [0|6.5] "V"  PT
 SG_ brickVoltage154_BMS01 m52 : 23|16@0+ (0.0001,0) [0|6.5] "V"  PT
 SG_ brickVoltage155_BMS01 m52 : 39|16@0+ (0.0001,0) [0|6.5] "V"  PT
 SG_ brickVoltage156_BMS01 m52 : 55|16@0+ (0.0001,0) [0|6.5] "V"  PT
 SG_ brickVoltage157_BMS01 m53 : 23|16@0+ (0.0001,0) [0|6.5] "V"  PT
 SG_ brickVoltage158_BMS01 m53 : 39|16@0+ (0.0001,0) [0|6.5] "V"  PT
 SG_ brickVoltage159_BMS01 m53 : 55|16@0+ (0.0001,0) [0|6.5] "V"  PT
 SG_ brickVoltage160_BMS01 m54 : 23|16@0+ (0.0001,0) [0|6.5] "V"  PT
 SG_ brickVoltage161_BMS01 m54 : 39|16@0+ (0.0001,0) [0|6.5] "V"  PT
 SG_ brickVoltage162_BMS01 m54 : 55|16@0+ (0.0001,0) [0|6.5] "V"  PT
 SG_ brickVoltage163_BMS01 m55 : 23|16@0+ (0.0001,0) [0|6.5] "V"  PT
 SG_ brickVoltage164_BMS01 m55 : 39|16@0+ (0.0001,0) [0|6.5] "V"  PT
 SG_ brickVoltage165_BMS01 m55 : 55|16@0+ (0.0001,0) [0|6.5] "V"  PT
 SG_ brickVoltage166_BMS01 m56 : 23|16@0+ (0.0001,0) [0|6.5] "V"  PT
 SG_ brickVoltage167_BMS01 m56 : 39|16@0+ (0.0001,0) [0|6.5] "V"  PT
 SG_ brickVoltage168_BMS01 m56 : 55|16@0+ (0.0001,0) [0|6.5] "V"  PT
 SG_ brickVoltage169_BMS01 m57 : 23|16@0+ (0.0001,0) [0|6.5] "V"  PT
 SG_ brickVoltage170_BMS01 m57 : 39|16@0+ (0.0001,0) [0|6.5] "V"  PT
 SG_ brickVoltage171_BMS01 m57 : 55|16@0+ (0.0001,0) [0|6.5] "V"  PT
 SG_ brickVoltage172_BMS01 m58 : 23|16@0+ (0.0001,0) [0|6.5] "V"  PT
 SG_ brickVoltage173_BMS01 m58 : 39|16@0+ (0.0001,0) [0|6.5] "V"  PT
 SG_ brickVoltage174_BMS01 m58 : 55|16@0+ (0.0001,0) [0|6.5] "V"  PT
 SG_ brickVoltage175_BMS01 m59 : 23|16@0+ (0.0001,0) [0|6.5] "V"  PT
 SG_ brickVoltage176_BMS01 m59 : 39|16@0+ (0.0001,0) [0|6.5] "V"  PT
 SG_ brickVoltage177_BMS01 m59 : 55|16@0+ (0.0001,0) [0|6.5] "V"  PT
 SG_ brickVoltage178_BMS01 m60 : 23|16@0+ (0.0001,0) [0|6.5] "V"  PT
 SG_ brickVoltage179_BMS01 m60 : 39|16@0+ (0.0001,0) [0|6.5] "V"  PT
 SG_ brickVoltage180_BMS01 m60 : 55|16@0+ (0.0001,0) [0|6.5] "V"  PT
 SG_ brickVoltage181_BMS01 m61 : 23|16@0+ (0.0001,0) [0|6.5] "V"  PT
 SG_ brickVoltage182_BMS01 m61 : 39|16@0+ (0.0001,0) [0|6.5] "V"  PT
 SG_ brickVoltage183_BMS01 m61 : 55|16@0+ (0.0001,0) [0|6.5] "V"  PT
 SG_ brickVoltage184_BMS01 m62 : 23|16@0+ (0.0001,0) [0|6.5] "V"  PT
 SG_ brickVoltage185_BMS01 m62 : 39|16@0+ (0.0001,0) [0|6.5] "V"  PT
 SG_ brickVoltage186_BMS01 m62 : 55|16@0+ (0.0001,0) [0|6.5] "V"  PT
 SG_ brickVoltage187_BMS01 m63 : 23|16@0+ (0.0001,0) [0|6.5] "V"  PT
 SG_ brickVoltage188_BMS01 m63 : 39|16@0+ (0.0001,0) [0|6.5] "V"  PT
 SG_ brickVoltage189_BMS01 m63 : 55|16@0+ (0.0001,0) [0|6.5] "V"  PT
 SG_ brickVoltage190_BMS01 m64 : 23|16@0+ (0.0001,0) [0|6.5] "V"  PT
 SG_ brickVoltage191_BMS01 m64 : 39|16@0+ (0.0001,0) [0|6.5] "V"  PT
 SG_ brickVoltage192_BMS01 m64 : 55|16@0+ (0.0001,0) [0|6.5] "V"  PT
 SG_ brickVoltage193_BMS01 m65 : 23|16@0+ (0.0001,0) [0|6.5] "V"  PT
 SG_ brickVoltage194_BMS01 m65 : 39|16@0+ (0.0001,0) [0|6.5] "V"  PT
 SG_ brickVoltage195_BMS01 m65 : 55|16@0+ (0.0001,0) [0|6.5] "V"  PT
 SG_ brickVoltage196_BMS01 m66 : 23|16@0+ (0.0001,0) [0|6.5] "V"  PT
 SG_ brickVoltage197_BMS01 m66 : 39|16@0+ (0.0001,0) [0|6.5] "V"  PT
 SG_ brickVoltage198_BMS01 m66 : 55|16@0+ (0.0001,0) [0|6.5] "V"  PT
 SG_ brickVoltage199_BMS01 m67 : 23|16@0+ (0.0001,0) [0|6.5] "V"  PT
 SG_ brickVoltage200_BMS01 m67 : 39|16@0+ (0.0001,0) [0|6.5] "V"  PT
 SG_ brickVoltage201_BMS01 m67 : 55|16@0+ (0.0001,0) [0|6.5] "V"  PT
 SG_ brickVoltage202_BMS01 m68 : 23|16@0+ (0.0001,0) [0|6.5] "V"  PT
 SG_ brickVoltage203_BMS01 m68 : 39|16@0+ (0.0001,0) [0|6.5] "V"  PT
 SG_ brickVoltage204_BMS01 m68 : 55|16@0+ (0.0001,0) [0|6.5] "V"  PT
 SG_ brickVoltage205_BMS01 m69 : 23|16@0+ (0.0001,0) [0|6.5] "V"  PT
 SG_ brickVoltage206_BMS01 m69 : 39|16@0+ (0.0001,0) [0|6.5] "V"  PT
 SG_ brickVoltage207_BMS01 m69 : 55|16@0+ (0.0001,0) [0|6.5] "V"  PT
 SG_ brickVoltage208_BMS01 m70 : 23|16@0+ (0.0001,0) [0|6.5] "V"  PT
 SG_ brickVoltage209_BMS01 m70 : 39|16@0+ (0.0001,0) [0|6.5] "V"  PT
 SG_ brickVoltage210_BMS01 m70 : 55|16@0+ (0.0001,0) [0|6.5] "V"  PT
 SG_ brickVoltage211_BMS01 m71 : 23|16@0+ (0.0001,0) [0|6.5] "V"  PT
 SG_ brickVoltage212_BMS01 m71 : 39|16@0+ (0.0001,0) [0|6.5] "V"  PT
 SG_ brickVoltage213_BMS01 m71 : 55|16@0+ (0.0001,0) [0|6.5] "V"  PT
 SG_ brickVoltage214_BMS01 m72 : 23|16@0+ (0.0001,0) [0|6.5] "V"  PT
 SG_ brickVoltage215_BMS01 m72 : 39|16@0+ (0.0001,0) [0|6.5] "V"  PT
 SG_ brickVoltage216_BMS01 m72 : 55|16@0+ (0.0001,0) [0|6.5] "V"  PT
 SG_ brickVoltage217_BMS01 m73 : 23|16@0+ (0.0001,0) [0|6.5] "V"  PT
 SG_ brickVoltage218_BMS01 m73 : 39|16@0+ (0.0001,0) [0|6.5] "V"  PT
 SG_ brickVoltage219_BMS01 m73 : 55|16@0+ (0.0001,0) [0|6.5] "V"  PT
 SG_ brickVoltage220_BMS01 m74 : 23|16@0+ (0.0001,0) [0|6.5] "V"  PT
 SG_ brickVoltage221_BMS01 m74 : 39|16@0+ (0.0001,0) [0|6.5] "V"  PT
 SG_ brickVoltage222_BMS01 m74 : 55|16@0+ (0.0001,0) [0|6.5] "V"  PT
 SG_ brickVoltage223_BMS01 m75 : 23|16@0+ (0.0001,0) [0|6.5] "V"  PT
 SG_ brickVoltage224_BMS01 m75 : 39|16@0+ (0.0001,0) [0|6.5] "V"  PT
 SG_ brickVoltage225_BMS01 m75 : 55|16@0+ (0.0001,0) [0|6.5] "V"  PT
 SG_ brickVoltage226_BMS01 m76 : 23|16@0+ (0.0001,0) [0|6.5] "V"  PT
 SG_ brickVoltage227_BMS01 m76 : 39|16@0+ (0.0001,0) [0|6.5] "V"  PT
 SG_ brickVoltage228_BMS01 m76 : 55|16@0+ (0.0001,0) [0|6.5] "V"  PT
 SG_ brickVoltage229_BMS01 m77 : 23|16@0+ (0.0001,0) [0|6.5] "V"  PT
 SG_ brickVoltage230_BMS01 m77 : 39|16@0+ (0.0001,0) [0|6.5] "V"  PT
 SG_ brickVoltage231_BMS01 m77 : 55|16@0+ (0.0001,0) [0|6.5] "V"  PT
 SG_ brickVoltage232_BMS01 m78 : 23|16@0+ (0.0001,0) [0|6.5] "V"  PT
 SG_ brickVoltage233_BMS01 m78 : 39|16@0+ (0.0001,0) [0|6.5] "V"  PT
 SG_ brickVoltage234_BMS01 m78 : 55|16@0+ (0.0001,0) [0|6.5] "V"  PT
 SG_ brickVoltage235_BMS01 m79 : 23|16@0+ (0.0001,0) [0|6.5] "V"  PT
 SG_ brickVoltage236_BMS01 m79 : 39|16@0+ (0.0001,0) [0|6.5] "V"  PT
 SG_ brickVoltage237_BMS01 m79 : 55|16@0+ (0.0001,0) [0|6.5] "V"  PT
 SG_ brickVoltage238_BMS01 m80 : 23|16@0+ (0.0001,0) [0|6.5] "V"  PT
 SG_ brickVoltage239_BMS01 m80 : 39|16@0+ (0.0001,0) [0|6.5] "V"  PT
 SG_ brickVoltage240_BMS01 m80 : 55|16@0+ (0.0001,0) [0|6.5] "V"  PT
 SG_ brickVoltage241_BMS01 m81 : 23|16@0+ (0.0001,0) [0|6.5] "V"  PT
 SG_ brickVoltage242_BMS01 m81 : 39|16@0+ (0.0001,0) [0|6.5] "V"  PT
 SG_ brickVoltage243_BMS01 m81 : 55|16@0+ (0.0001,0) [0|6.5] "V"  PT
 SG_ brickVoltage244_BMS01 m82 : 23|16@0+ (0.0001,0) [0|6.5] "V"  PT
 SG_ brickVoltage245_BMS01 m82 : 39|16@0+ (0.0001,0) [0|6.5] "V"  PT
 SG_ brickVoltage246_BMS01 m82 : 55|16@0+ (0.0001,0) [0|6.5] "V"  PT
 SG_ brickVoltage247_BMS01 m83 : 23|16@0+ (0.0001,0) [0|6.5] "V"  PT
 SG_ brickVoltage248_BMS01 m83 : 39|16@0+ (0.0001,0) [0|6.5] "V"  PT
 SG_ brickVoltage249_BMS01 m83 : 55|16@0+ (0.0001,0) [0|6.5] "V"  PT
 SG_ brickVoltage250_BMS01 m84 : 23|16@0+ (0.0001,0) [0|6.5] "V"  PT
 SG_ brickVoltage251_BMS01 m84 : 39|16@0+ (0.0001,0) [0|6.5] "V"  PT
 SG_ brickVoltage252_BMS01 m84 : 55|16@0+ (0.0001,0) [0|6.5] "V"  PT
 SG_ brickVoltage253_BMS01 m85 : 23|16@0+ (0.0001,0) [0|6.5] "V"  PT
 SG_ brickVoltage254_BMS01 m85 : 39|16@0+ (0.0001,0) [0|6.5] "V"  PT
 SG_ brickVoltage255_BMS01 m85 : 55|16@0+ (0.0001,0) [0|6.5] "V"  PT
 SG_ brickVoltage256_BMS01 m86 : 23|16@0+ (0.0001,0) [0|6.5] "V"  PT
 SG_ brickVoltage257_BMS01 m86 : 39|16@0+ (0.0001,0) [0|6.5] "V"  PT
 SG_ brickVoltage258_BMS01 m86 : 55|16@0+ (0.0001,0) [0|6.5] "V"  PT
 SG_ brickVoltage259_BMS01 m87 : 23|16@0+ (0.0001,0) [0|6.5] "V"  PT
 SG_ brickVoltage260_BMS01 m87 : 39|16@0+ (0.0001,0) [0|6.5] "V"  PT
 SG_ brickVoltage261_BMS01 m87 : 55|16@0+ (0.0001,0) [0|6.5] "V"  PT
 SG_ brickVoltage262_BMS01 m88 : 23|16@0+ (0.0001,0) [0|6.5] "V"  PT
 SG_ brickVoltage263_BMS01 m88 : 39|16@0+ (0.0001,0) [0|6.5] "V"  PT
 SG_ brickVoltage264_BMS01 m88 : 55|16@0+ (0.0001,0) [0|6.5] "V"  PT
 SG_ brickVoltage265_BMS01 m89 : 23|16@0+ (0.0001,0) [0|6.5] "V"  PT
 SG_ brickVoltage266_BMS01 m89 : 39|16@0+ (0.0001,0) [0|6.5] "V"  PT
 SG_ brickVoltage267_BMS01 m89 : 55|16@0+ (0.0001,0) [0|6.5] "V"  PT
 SG_ brickVoltage268_BMS01 m90 : 23|16@0+ (0.0001,0) [0|6.5] "V"  PT
 SG_ brickVoltage269_BMS01 m90 : 39|16@0+ (0.0001,0) [0|6.5] "V"  PT
 SG_ brickVoltage270_BMS01 m90 : 55|16@0+ (0.0001,0) [0|6.5] "V"  PT
 SG_ brickVoltage271_BMS01 m91 : 23|16@0+ (0.0001,0) [0|6.5] "V"  PT
 SG_ brickVoltage272_BMS01 m91 : 39|16@0+ (0.0001,0) [0|6.5] "V"  PT
 SG_ brickVoltage273_BMS01 m91 : 55|16@0+ (0.0001,0) [0|6.5] "V"  PT
 SG_ brickVoltage274_BMS01 m92 : 23|16@0+ (0.0001,0) [0|6.5] "V"  PT
 SG_ brickVoltage275_BMS01 m92 : 39|16@0+ (0.0001,0) [0|6.5] "V"  PT
 SG_ brickVoltage276_BMS01 m92 : 55|16@0+ (0.0001,0) [0|6.5] "V"  PT
 SG_ brickVoltage277_BMS01 m93 : 23|16@0+ (0.0001,0) [0|6.5] "V"  PT
 SG_ brickVoltage278_BMS01 m93 : 39|16@0+ (0.0001,0) [0|6.5] "V"  PT
 SG_ brickVoltage279_BMS01 m93 : 55|16@0+ (0.0001,0) [0|6.5] "V"  PT
 SG_ brickVoltage280_BMS01 m94 : 23|16@0+ (0.0001,0) [0|6.5] "V"  PT
 SG_ brickVoltage281_BMS01 m94 : 39|16@0+ (0.0001,0) [0|6.5] "V"  PT
 SG_ brickVoltage282_BMS01 m94 : 55|16@0+ (0.0001,0) [0|6.5] "V"  PT
 SG_ brickVoltage283_BMS01 m95 : 23|16@0+ (0.0001,0) [0|6.5] "V"  PT
 SG_ brickVoltage284_BMS01 m95 : 39|16@0+ (0.0001,0) [0|6.5] "V"  PT
 SG_ brickVoltage285_BMS01 m95 : 55|16@0+ (0.0001,0) [0|6.5] "V"  PT
 SG_ brickVoltage286_BMS01 m96 : 23|16@0+ (0.0001,0) [0|6.5] "V"  PT
 SG_ brickVoltage287_BMS01 m96 : 39|16@0+ (0.0001,0) [0|6.5] "V"  PT
 SG_ brickVoltage288_BMS01 m96 : 55|16@0+ (0.0001,0) [0|6.5] "V"  PT
 SG_ brickVoltage289_BMS01 m97 : 23|16@0+ (0.0001,0) [0|6.5] "V"  PT
 SG_ brickVoltage290_BMS01 m97 : 39|16@0+ (0.0001,0) [0|6.5] "V"  PT
 SG_ brickVoltage291_BMS01 m97 : 55|16@0+ (0.0001,0) [0|6.5] "V"  PT
 SG_ brickVoltage292_BMS01 m98 : 23|16@0+ (0.0001,0) [0|6.5] "V"  PT
 SG_ brickVoltage293_BMS01 m98 : 39|16@0+ (0.0001,0) [0|6.5] "V"  PT
 SG_ brickVoltage294_BMS01 m98 : 55|16@0+ (0.0001,0) [0|6.5] "V"  PT
 SG_ brickVoltage295_BMS01 m99 : 23|16@0+ (0.0001,0) [0|6.5] "V"  PT
 SG_ brickVoltage296_BMS01 m99 : 39|16@0+ (0.0001,0) [0|6.5] "V"  PT
 SG_ brickVoltage297_BMS01 m99 : 55|16@0+ (0.0001,0) [0|6.5] "V"  PT
 SG_ brickVoltage298_BMS01 m100 : 23|16@0+ (0.0001,0) [0|6.5] "V"  PT
 SG_ brickVoltage299_BMS01 m100 : 39|16@0+ (0.0001,0) [0|6.5] "V"  PT
 SG_ brickVoltage300_BMS01 m100 : 55|16@0+ (0.0001,0) [0|6.5] "V"  PT
 SG_ moduleTemperature33_BMS01 m33 : 15|8@0+ (1,-40) [-40|200] "C"  PT
 SG_ moduleTemperature34_BMS01 m34 : 15|8@0+ (1,-40) [-40|200] "C"  PT
 SG_ moduleTemperature35_BMS01 m35 : 15|8@0+ (1,-40) [-40|200] "C"  PT
 SG_ moduleTemperature36_BMS01 m36 : 15|8@0+ (1,-40) [-40|200] "C"  PT
 SG_ moduleTemperature37_BMS01 m37 : 15|8@0+ (1,-40) [-40|200] "C"  PT
 SG_ moduleTemperature38_BMS01 m38 : 15|8@0+ (1,-40) [-40|200] "C"  PT
 SG_ moduleTemperature39_BMS01 m39 : 15|8@0+ (1,-40) [-40|200] "C"  PT
 SG_ moduleTemperature40_BMS01 m40 : 15|8@0+ (1,-40) [-40|200] "C"  PT
 SG_ moduleTemperature41_BMS01 m41 : 15|8@0+ (1,-40) [-40|200] "C"  PT
 SG_ moduleTemperature42_BMS01 m42 : 15|8@0+ (1,-40) [-40|200] "C"  PT
 SG_ moduleTemperature43_BMS01 m43 : 15|8@0+ (1,-40) [-40|200] "C"  PT
 SG_ moduleTemperature44_BMS01 m44 : 15|8@0+ (1,-40) [-40|200] "C"  PT
 SG_ moduleTemperature45_BMS01 m45 : 15|8@0+ (1,-40) [-40|200] "C"  PT
 SG_ moduleTemperature46_BMS01 m46 : 15|8@0+ (1,-40) [-40|200] "C"  PT
 SG_ moduleTemperature47_BMS01 m47 : 15|8@0+ (1,-40) [-40|200] "C"  PT
 SG_ moduleTemperature48_BMS01 m48 : 15|8@0+ (1,-40) [-40|200] "C"  PT
 SG_ moduleTemperature49_BMS01 m49 : 15|8@0+ (1,-40) [-40|200] "C"  PT
 SG_ moduleTemperature50_BMS01 m50 : 15|8@0+ (1,-40) [-40|200] "C"  PT
 SG_ moduleTemperature51_BMS01 m51 : 15|8@0+ (1,-40) [-40|200] "C"  PT
 SG_ moduleTemperature52_BMS01 m52 : 15|8@0+ (1,-40) [-40|200] "C"  PT
 SG_ moduleTemperature53_BMS01 m53 : 15|8@0+ (1,-40) [-40|200] "C"  PT
 SG_ moduleTemperature54_BMS01 m54 : 15|8@0+ (1,-40) [-40|200] "C"  PT
 SG_ moduleTemperature55_BMS01 m55 : 15|8@0+ (1,-40) [-40|200] "C"  PT
 SG_ moduleTemperature56_BMS01 m56 : 15|8@0+ (1,-40) [-40|200] "C"  PT
 SG_ moduleTemperature57_BMS01 m57 : 15|8@0+ (1,-40) [-40|200] "C"  PT
 SG_ moduleTemperature58_BMS01 m58 : 15|8@0+ (1,-40) [-40|200] "C"  PT
 SG_ moduleTemperature59_BMS01 m59 : 15|8@0+ (1,-40) [-40|200] "C"  PT
 SG_ moduleTemperature60_BMS01 m60 : 15|8@0+ (1,-40) [-40|200] "C"  PT
 SG_ moduleTemperature61_BMS01 m61 : 15|8@0+ (1,-40) [-40|200] "C"  PT
 SG_ moduleTemperature62_BMS01 m62 : 15|8@0+ (1,-40) [-40|200] "C"  PT
 SG_ moduleTemperature63_BMS01 m63 : 15|8@0+ (1,-40) [-40|200] "C"  PT
 SG_ moduleTemperature64_BMS01 m64 : 15|8@0+ (1,-40) [-40|200] "C"  PT
 SG_ moduleTemperature65_BMS01 m65 : 15|8@0+ (1,-40) [-40|200] "C"  PT
 SG_ moduleTemperature66_BMS01 m66 : 15|8@0+ (1,-40) [-40|200] "C"  PT
 SG_ moduleTemperature67_BMS01 m67 : 15|8@0+ (1,-40) [-40|200] "C"  PT
 SG_ moduleTemperature68_BMS01 m68 : 15|8@0+ (1,-40) [-40|200] "C"  PT
 SG_ moduleTemperature69_BMS01 m69 : 15|8@0+ (1,-40) [-40|200] "C"  PT
 SG_ moduleTemperature70_BMS01 m70 : 15|8@0+ (1,-40) [-40|200] "C"  PT
 SG_ moduleTemperature71_BMS01 m71 : 15|8@0+ (1,-40) [-40|200] "C"  PT
 SG_ moduleTemperature72_BMS01 m72 : 15|8@0+ (1,-40) [-40|200] "C"  PT
 SG_ moduleTemperature73_BMS01 m73 : 15|8@0+ (1,-40) [-40|200] "C"  PT
 SG_ moduleTemperature74_BMS01 m74 : 15|8@0+ (1,-40) [-40|200] "C"  PT
 SG_ moduleTemperature75_BMS01 m75 : 15|8@0+ (1,-40) [-40|200] "C"  PT
 SG_ moduleTemperature76_BMS01 m76 : 15|8@0+ (1,-40) [-40|200] "C"  PT
 SG_ moduleTemperature77_BMS01 m77 : 15|8@0+ (1,-40) [-40|200] "C"  PT
 SG_ moduleTemperature78_BMS01 m78 : 15|8@0+ (1,-40) [-40|200] "C"  PT
 SG_ moduleTemperature79_BMS01 m79 : 15|8@0+ (1,-40) [-40|200] "C"  PT
 SG_ moduleTemperature80_BMS01 m80 : 15|8@0+ (1,-40) [-40|200] "C"  PT
 SG_ moduleTemperature81_BMS01 m81 : 15|8@0+ (1,-40) [-40|200] "C"  PT
 SG_ moduleTemperature82_BMS01 m82 : 15|8@0+ (1,-40) [-40|200] "C"  PT
 SG_ moduleTemperature83_BMS01 m83 : 15|8@0+ (1,-40) [-40|200] "C"  PT
 SG_ moduleTemperature84_BMS01 m84 : 15|8@0+ (1,-40) [-40|200] "C"  PT
 SG_ moduleTemperature85_BMS01 m85 : 15|8@0+ (1,-40) [-40|200] "C"  PT
 SG_ moduleTemperature86_BMS01 m86 : 15|8@0+ (1,-40) [-40|200] "C"  PT
 SG_ moduleTemperature87_BMS01 m87 : 15|8@0+ (1,-40) [-40|200] "C"  PT
 SG_ moduleTemperature88_BMS01 m88 : 15|8@0+ (1,-40) [-40|200] "C"  PT
 SG_ moduleTemperature89_BMS01 m89 : 15|8@0+ (1,-40) [-40|200] "C"  PT
 SG_ moduleTemperature90_BMS01 m90 : 15|8@0+ (1,-40) [-40|200] "C"  PT
 SG_ moduleTemperature91_BMS01 m91 : 15|8@0+ (1,-40) [-40|200] "C"  PT
 SG_ moduleTemperature92_BMS01 m92 : 15|8@0+ (1,-40) [-40|200] "C"  PT
 SG_ moduleTemperature93_BMS01 m93 : 15|8@0+ (1,-40) [-40|200] "C"  PT
 SG_ moduleTemperature94_BMS01 m94 : 15|8@0+ (1,-40) [-40|200] "C"  PT
 SG_ moduleTemperature95_BMS01 m95 : 15|8@0+ (1,-40) [-40|200] "C"  PT
 SG_ moduleTemperature96_BMS01 m96 : 15|8@0+ (1,-40) [-40|200] "C"  PT
 SG_ moduleTemperature97_BMS01 m97 : 15|8@0+ (1,-40) [-40|200] "C"  PT
 SG_ moduleTemperature98_BMS01 m98 : 15|8@0+ (1,-40) [-40|200] "C"  PT
 SG_ moduleTemperature99_BMS01 m99 : 15|8@0+ (1,-40) [-40|200] "C"  PT
 SG_ moduleTemperature100_BMS01 m100 : 15|8@0+ (1,-40) [-40|200] "C"  PT
 SG_ moduleTemperature101_BMS01 m101 : 15|8@0+ (1,-40) [-40|200] "C"  PT
 SG_ moduleTemperature102_BMS01 m102 : 15|8@0+ (1,-40) [-40|200] "C"  PT
 SG_ moduleTemperature103_BMS01 m103 : 15|8@0+ (1,-40) [-40|200] "C"  PT
 SG_ moduleTemperature104_BMS01 m104 : 15|8@0+ (1,-40) [-40|200] "C"  PT
 SG_ moduleTemperature105_BMS01 m105 : 15|8@0+ (1,-40) [-40|200] "C"  PT
 SG_ moduleTemperature106_BMS01 m106 : 15|8@0+ (1,-40) [-40|200] "C"  PT
 SG_ moduleTemperature107_BMS01 m107 : 15|8@0+ (1,-40) [-40|200] "C"  PT
 SG_ moduleTemperature108_BMS01 m108 : 15|8@0+ (1,-40) [-40|200] "C"  PT
 SG_ moduleTemperature109_BMS01 m109 : 15|8@0+ (1,-40) [-40|200] "C"  PT
 SG_ moduleTemperature110_BMS01 m110 : 15|8@0+ (1,-40) [-40|200] "C"  PT
 SG_ moduleTemperature111_BMS01 m111 : 15|8@0+ (1,-40) [-40|200] "C"  PT
 SG_ moduleTemperature112_BMS01 m112 : 15|8@0+ (1,-40) [-40|200] "C"  PT
 SG_ moduleTemperature113_BMS01 m113 : 15|8@0+ (1,-40) [-40|200] "C"  PT
 SG_ moduleTemperature114_BMS01 m114 : 15|8@0+ (1,-40) [-40|200] "C"  PT
 SG_ moduleTemperature115_BMS01 m115 : 15|8@0+ (1,-40) [-40|200] "C"  PT
 SG_ moduleTemperature116_BMS01 m116 : 15|8@0+ (1,-40) [-40|200] "C"  PT
 SG_ moduleTemperature117_BMS01 m117 : 15|8@0+ (1,-40) [-40|200] "C"  PT
 SG_ moduleTemperature118_BMS01 m118 : 15|8@0+ (1,-40) [-40|200] "C"  PT
 SG_ moduleTemperature119_BMS01 m119 : 15|8@0+ (1,-40) [-40|200] "C"  PT
 SG_ moduleTemperature120_BMS01 m120 : 15|8@0+ (1,-40) [-40|200] "C"  PT
 SG_ moduleTemperature121_BMS01 m121 : 15|8@0+ (1,-40) [-40|200] "C"  PT
 SG_ moduleTemperature122_BMS01 m122 : 15|8@0+ (1,-40) [-40|200] "C"  PT
 SG_ moduleTemperature123_BMS01 m123 : 15|8@0+ (1,-40) [-40|200] "C"  PT
 SG_ moduleTemperature124_BMS01 m124 : 15|8@0+ (1,-40) [-40|200] "C"  PT
 SG_ moduleTemperature125_BMS01 m125 : 15|8@0+ (1,-40) [-40|200] "C"  PT
 SG_ moduleTemperature126_BMS01 m126 : 15|8@0+ (1,-40) [-40|200] "C"  PT
 SG_ moduleTemperature127_BMS01 m127 : 15|8@0+ (1,-40) [-40|200] "C"  PT
 SG_ moduleTemperature128_BMS01 m128 : 15|8@0+ (1,-40) [-40|200] "C"  PT
 SG_ moduleTemperature129_BMS01 m129 : 15|8@0+ (1,-40) [-40|200] "C"  PT
 SG_ moduleTemperature130_BMS01 m130 : 15|8@0+ (1,-40) [-40|200] "C"  PT
 SG_ moduleTemperature131_BMS01 m131 : 15|8@0+ (1,-40) [-40|200] "C"  PT
 SG_ moduleTemperature132_BMS01 m132 : 15|8@0+ (1,-40) [-40|200] "C"  PT
 SG_ moduleTemperature133_BMS01 m133 : 15|8@0+ (1,-40) [-40|200] "C"  PT
 SG_ moduleTemperature134_BMS01 m134 : 15|8@0+ (1,-40) [-40|200] "C"  PT
 SG_ moduleTemperature135_BMS01 m135 : 15|8@0+ (1,-40) [-40|200] "C"  PT
 SG_ moduleTemperature136_BMS01 m136 : 15|8@0+ (1,-40) [-40|200] "C"  PT
 SG_ moduleTemperature137_BMS01 m137 : 15|8@0+ (1,-40) [-40|200] "C"  PT
 SG_ moduleTemperature138_BMS01 m138 : 15|8@0+ (1,-40) [-40|200] "C"  PT
 SG_ moduleTemperature139_BMS01 m139 : 15|8@0+ (1,-40) [-40|200] "C"  PT
 SG_ moduleTemperature140_BMS01 m140 : 15|8@0+ (1,-40) [-40|200] "C"  PT
 SG_ moduleTemperature141_BMS01 m141 : 15|8@0+ (1,-40) [-40|200] "C"  PT
 SG_ moduleTemperature142_BMS01 m142 : 15|8@0+ (1,-40) [-40|200] "C"  PT
 SG_ moduleTemperature143_BMS01 m143 : 15|8@0+ (1,-40) [-40|200] "C"  PT
 SG_ moduleTemperature144_BMS01 m144 : 15|8@0+ (1,-40) [-40|200] "C"  PT
 SG_ moduleTemperature145_BMS01 m145 : 15|8@0+ (1,-40) [-40|200] "C"  PT
 SG_ moduleTemperature146_BMS01 m146 : 15|8@0+ (1,-40) [-40|200] "C"  PT
 SG_ moduleTemperature147_BMS01 m147 : 15|8@0+ (1,-40) [-40|200] "C"  PT
 SG_ moduleTemperature148_BMS01 m148 : 15|8@0+ (1,-40) [-40|200] "C"  PT
 SG_ moduleTemperature149_BMS01 m149 : 15|8@0+ (1,-40) [-40|200] "C"  PT
 SG_ moduleTemperature150_BMS01 m150 : 15|8@0+ (1,-40) [-40|200] "C"  PT
 SG_ moduleTemperature151_BMS01 m151 : 15|8@0+ (1,-40) [-40|200] "C"  PT
 SG_ moduleTemperature152_BMS01 m152 : 15|8@0+ (1,-40) [-40|200] "C"  PT
 SG_ moduleTemperature153_BMS01 m153 : 15|8@0+ (1,-40) [-40|200] "C"  PT
 SG_ moduleTemperature154_BMS01 m154 : 15|8@0+ (1,-40) [-40|200] "C"  PT
 SG_ moduleTemperature155_BMS01 m155 : 15|8@0+ (1,-40) [-40|200] "C"  PT
 SG_ moduleTemperature156_BMS01 m156 : 15|8@0+ (1,-40) [-40|200] "C"  PT
 SG_ moduleTemperature157_BMS01 m157 : 15|8@0+ (1,-40) [-40|200] "C"  PT
 SG_ moduleTemperature158_BMS01 m158 : 15|8@0+ (1,-40) [-40|200] "C"  PT
 SG_ moduleTemperature159_BMS01 m159 : 15|8@0+ (1,-40) [-40|200] "C"  PT
 SG_ moduleTemperature160_BMS01 m160 : 15|8@0+ (1,-40) [-40|200] "C"  PT
 SG_ moduleTemperature161_BMS01 m161 : 15|8@0+ (1,-40) [-40|200] "C"  PT
 SG_ moduleTemperature162_BMS01 m162 : 15|8@0+ (1,-40) [-40|200] "C"  PT
 SG_ moduleTemperature163_BMS01 m163 : 15|8@0+ (1,-40) [-40|200] "C"  PT
 SG_ moduleTemperature164_BMS01 m164 : 15|8@0+ (1,-40) [-40|200] "C"  PT
 SG_ moduleTemperature165_BMS01 m165 : 15|8@0+ (1,-40) [-40|200] "C"  PT
 SG_ moduleTemperature166_BMS01 m166 : 15|8@0+ (1,-40) [-40|200] "C"  PT
 SG_ moduleTemperature167_BMS01 m167 : 15|8@0+ (1,-40) [-40|200] "C"  PT
 SG_ moduleTemperature168_BMS01 m168 : 15|8@0+ (1,-40) [-40|200] "C"  PT
 SG_ moduleTemperature169_BMS01 m169 : 15|8@0+ (1,-40) [-40|200] "C"  PT
 SG_ moduleTemperature170_BMS01 m170 : 15|8@0+ (1,-40) [-40|200] "C"  PT
 SG_ moduleTemperature171_BMS01 m171 : 15|8@0+ (1,-40) [-40|200] "C"  PT
 SG_ moduleTemperature172_BMS01 m172 : 15|8@0+ (1,-40) [-40|200] "C"  PT
 SG_ moduleTemperature173_BMS01 m173 : 15|8@0+ (1,-40) [-40|200] "C"  PT
 SG_ moduleTemperature174_BMS01 m174 : 15|8@0+ (1,-40) [-40|200] "C"  PT
 SG_ moduleTemperature175_BMS01 m175 : 15|8@0+ (1,-40) [-40|200] "C"  PT
 SG_ moduleTemperature176_BMS01 m176 : 15|8@0+ (1,-40) [-40|200] "C"  PT
 SG_ moduleTemperature177_BMS01 m177 : 15|8@0+ (1,-40) [-40|200] "C"  PT
 SG_ moduleTemperature178_BMS01 m178 : 15|8@0+ (1,-40) [-40|200] "C"  PT
 SG_ moduleTemperature179_BMS01 m179 : 15|8@0+ (1,-40) [-40|200] "C"  PT
 SG_ moduleTemperature180_BMS01 m180 : 15|8@0+ (1,-40) [-40|200] "C"  PT
 SG_ moduleTemperature181_BMS01 m181 : 15|8@0+ (1,-40) [-40|200] "C"  PT
 SG_ moduleTemperature182_BMS01 m182 : 15|8@0+ (1,-40) [-40|200] "C"  PT
 SG_ moduleTemperature183_BMS01 m183 : 15|8@0+ (1,-40) [-40|200] "C"  PT
 SG_ moduleTemperature184_BMS01 m184 : 15|8@0+ (1,-40) [-40|200] "C"  PT
 SG_ moduleTemperature185_BMS01 m185 : 15|8@0+ (1,-40) [-40|200] "C"  PT
 SG_ moduleTemperature186_BMS01 m186 : 15|8@0+ (1,-40) [-40|200] "C"  PT
 SG_ moduleTemperature187_BMS01 m187 : 15|8@0+ (1,-40) [-40|200] "C"  PT
 SG_ moduleTemperature188_BMS01 m188 : 15|8@0+ (1,-40) [-40|200] "C"  PT
 SG_ moduleTemperature189_BMS01 m189 : 15|8@0+ (1,-40) [-40|200] "C"  PT
 SG_ moduleTemperature190_BMS01 m190 : 15|8@0+ (1,-40) [-40|200] "C"  PT
 SG_ moduleTemperature191_BMS01 m191 : 15|8@0+ (1,-40) [-40|200] "C"  PT
 SG_ moduleTemperature192_BMS01 m192 : 15|8@0+ (1,-40) [-40|200] "C"  PT

BO_ 768 BMS_DebugESSMaster1: 8 BMS
 SG_ essMstrChargeDerateFlag_BMS : 59|1@0+ (1,0) [0|1] ""  PT
 SG_ essShutdownTarget_BMS : 35|4@0+ (1,0) [0|0] ""  PT
 SG_ essShutdownTimer_BMS : 23|16@0+ (1,0) [0|0] ""  PT
 SG_ essMstrState_BMS01 : 55|4@0+ (1,0) [0|0] ""  PT
 SG_ essMstrStr00ShouldBeOn_BMS : 8|1@0+ (1,0) [0|1] ""  PT
 SG_ essMstrStr01ShouldBeOn_BMS : 9|1@0+ (1,0) [0|1] ""  PT
 SG_ essMstrStr02ShouldBeOn_BMS : 10|1@0+ (1,0) [0|1] ""  PT
 SG_ essMstrStr03ShouldBeOn_BMS : 11|1@0+ (1,0) [0|1] ""  PT
 SG_ essMstrStr04ShouldBeOn_BMS : 12|1@0+ (1,0) [0|1] ""  PT
 SG_ essMstrStr05ShouldBeOn_BMS : 13|1@0+ (1,0) [0|1] ""  PT
 SG_ essMstrStr06ShouldBeOn_BMS : 14|1@0+ (1,0) [0|1] ""  PT
 SG_ essMstrStr07ShouldBeOn_BMS : 15|1@0+ (1,0) [0|1] ""  PT
 SG_ essMstrStr08ShouldBeOn_BMS : 0|1@0+ (1,0) [0|1] ""  PT
 SG_ essMstrStr09ShouldBeOn_BMS : 1|1@0+ (1,0) [0|1] ""  PT
 SG_ essMstrStr10ShouldBeOn_BMS : 2|1@0+ (1,0) [0|1] ""  PT
 SG_ essMstrStr11ShouldBeOn_BMS : 3|1@0+ (1,0) [0|1] ""  PT
 SG_ essMstrStr12ShouldBeOn_BMS : 4|1@0+ (1,0) [0|1] ""  PT
 SG_ essMstrStr13ShouldBeOn_BMS : 5|1@0+ (1,0) [0|1] ""  PT
 SG_ essMstrStr14ShouldBeOn_BMS : 6|1@0+ (1,0) [0|1] ""  PT
 SG_ essMstrStr15ShouldBeOn_BMS : 7|1@0+ (1,0) [0|1] ""  PT
 SG_ essMstrStateRequest_BMS : 43|4@0+ (1,0) [0|0] ""  PT
 SG_ essMstrOverallChargeState_BMS : 51|4@0+ (1,0) [0|0] ""  PT
 SG_ essMstrDriveInhibit_BMS : 56|1@0+ (1,0) [0|1] ""  PT
 SG_ essMstrChargeInhibit_BMS : 57|1@0+ (1,0) [0|1] ""  PT
 SG_ essMstrAccInhibit_BMS : 58|1@0+ (1,0) [0|1] ""  PT
 SG_ essMstrNrOfStringsInPrchg_BMS : 47|4@0+ (1,0) [0|0] ""  PT

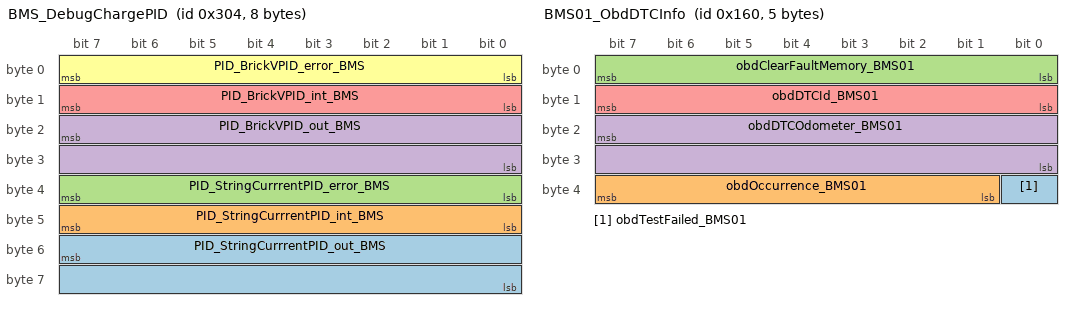
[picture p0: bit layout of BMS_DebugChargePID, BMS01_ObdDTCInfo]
BO_ 772 BMS_DebugChargePID: 8 BMS
 SG_ PID_StringCurrrentPID_out_BMS : 55|16@0+ (0.01,-325) [-325|325] ""  PT
 SG_ PID_StringCurrrentPID_int_BMS : 47|8@0+ (0.5,0) [0|125] ""  PT
 SG_ PID_StringCurrrentPID_error_BMS : 39|8@0+ (0.1,-12.5) [-12.5|12.5] "A"  PT
 SG_ PID_BrickVPID_out_BMS : 23|16@0+ (0.01,-325) [-325|325] ""  PT
 SG_ PID_BrickVPID_int_BMS : 15|8@0+ (0.5,0) [0|125] ""  PT
 SG_ PID_BrickVPID_error_BMS : 7|8@0+ (0.005,-0.5) [-0.5|0.5] "V"  PT

BO_ 284 ME_DebugCommand: 8 ME
 SG_ rangeRequestCmdIgnoreVehicle_ME m43 : 47|8@0+ (1,0) [0|65535] "" Vector__XXX
 SG_ rangeRequestCmdEepromValue_ME m43 : 39|8@0+ (1,0) [0|65535] "" Vector__XXX
 SG_ rangeRequestCmdPassword_ME m43 : 23|16@0+ (1,0) [0|65535] "" Vector__XXX
 SG_ BMSIDmult43_ME m43 : 15|8@0+ (1,0) [0|255] "" Vector__XXX
 SG_ resetAuxCntrOpnUnderLoadCntr_ME m23 : 55|8@0- (1,0) [0|0] "" Vector__XXX
 SG_ BMSIDmult42_ME m42 : 15|8@0+ (1,0) [0|255] ""  PT
 SG_ hvWithstandResetPass_ME m42 : 23|16@0+ (1,0) [0|65535] ""  PT
 SG_ hvWithstandReset_ME m42 : 39|8@0+ (1,0) [0|255] ""  PT
 SG_ thermalEventResetPass_ME m41 : 23|16@0+ (1,0) [0|65535] ""  PT
 SG_ thermalEventReset_ME m41 : 39|8@0+ (1,0) [0|255] ""  PT
 SG_ BMSIDmult41_ME m41 : 15|8@0+ (1,0) [0|255] ""  PT
 SG_ BMSIDmult40_ME m40 : 15|8@0+ (1,0) [0|255] "" Vector__XXX
 SG_ selfTestFault_ME m40 : 39|8@0+ (1,0) [0|255] "" Vector__XXX
 SG_ selfTestFaultInjectPass_ME m40 : 23|16@0+ (1,0) [0|65535] "" Vector__XXX
 SG_ resetStatistics_ME m23 : 47|8@0+ (1,0) [0|255] "" Vector__XXX
 SG_ safetyCANMsgFault_ME m39 : 47|8@0+ (1,0) [0|255] ""  PT
 SG_ safetyCANMsgID_ME m39 : 39|8@0+ (1,0) [0|255] ""  PT
 SG_ safetyCANFaultInjectPass_ME m39 : 23|16@0+ (1,0) [0|65535] ""  PT
 SG_ BMSIDmult39_ME m39 : 15|8@0+ (1,0) [0|255] ""  PT
 SG_ setResetHVLockPassword_ME m38 : 23|16@0+ (1,0) [0|65535] "" Vector__XXX
 SG_ setResetHVLock_ME m38 : 39|8@0+ (1,0) [0|255] "" Vector__XXX
 SG_ BMSIDmult38_ME m38 : 15|8@0+ (1,0) [0|255] "" Vector__XXX
 SG_ BMSIDmult37_ME m37 : 15|8@0+ (1,0) [0|255] ""  PT
 SG_ BMSIDmult36_ME m36 : 15|8@0+ (1,0) [0|255] ""  PT
 SG_ BMSIDmult35_ME m35 : 15|8@0+ (1,0) [0|255] ""  PT
 SG_ clearAuxWeldFlagsPW_ME m36 : 23|16@0+ (1,0) [0|65535] ""  PT
 SG_ clearAuxWeldFlags_ME m36 : 39|8@0+ (1,0) [0|0] ""  PT
 SG_ enableIsenseDebugging_ME m37 : 23|16@0+ (1,0) [0|65535] ""  PT
 SG_ initialCapacityPW_ME m35 : 23|16@0+ (1,0) [0|65535] ""  PT
 SG_ initialCapacity_ME m35 : 39|16@0+ (20,0) [0|1310700] "As"  PT
 SG_ BMSIDmult34_ME m34 : 15|8@0+ (1,0) [0|255] ""  PT
 SG_ resetFusiLockPassword_ME m34 : 23|16@0+ (1,0) [0|65535] ""  PT
 SG_ resetFusiLock_ME m34 : 39|8@0+ (1,0) [0|255] ""  PT
 SG_ eventMapDebugEventStatus_ME m13 : 55|8@0+ (1,0) [0|0] ""  PT
 SG_ BMSIDmult33_ME m33 : 15|8@0+ (1,0) [0|255] ""  PT
 SG_ setPerformanceMode_ME m33 : 23|8@0+ (1,0) [0|255] ""  PT
 SG_ debugCtrlChargerCC_ME m9 : 47|8@0+ (1,0) [0|0] ""  PT
 SG_ BMSIDmult32_ME m32 : 15|8@0+ (1,0) [0|255] ""  PT
 SG_ commandActiveIsoTest_ME m32 : 23|8@0+ (1,0) [0|255] ""  PT
 SG_ BMSIDmult31_ME m31 : 15|8@0+ (1,0) [0|255] ""  PT
 SG_ BMSIDmult30_ME m30 : 15|8@0+ (1,0) [0|255] ""  PT
 SG_ triggerReactionOnSCViaSpi_ME m30 : 23|8@0+ (1,0) [0|255] ""  PT
 SG_ storeCalibrationsInEeprom_ME m31 : 23|8@0+ (1,0) [0|0] ""  PT
 SG_ debugCtrlZDWLSDEN_ME m15 : 55|8@0+ (1,0) [0|0] ""  PT
 SG_ debugCtrlPyroEN_ME m15 : 63|8@0+ (1,0) [0|0] ""  PT
 SG_ ssaRTOffsetDay_ME m29 : 39|8@0+ (1,0) [0|0] "dd"  PT
 SG_ ssaRTOffsetMonth_ME m29 : 47|8@0+ (1,0) [0|0] "mm"  PT
 SG_ ssaRTOffsetYear_ME m29 : 55|16@0+ (1,0) [0|0] "yyyy"  PT
 SG_ resetSSATimePassword_ME m29 : 23|16@0+ (1,0) [0|65535] ""  PT
 SG_ BMSIDmult29_ME m29 : 15|8@0+ (1,0) [0|255] ""  PT
 SG_ enterBLPassword_ME m28 : 23|16@0+ (1,0) [0|65535] ""  PT
 SG_ BMSIDmult28_ME m28 : 15|8@0+ (1,0) [0|255] ""  PT
 SG_ setDebugMsgSpeed_ME m20 : 63|8@0+ (1,0) [0|255] ""  PT
 SG_ commandOCVRecalibration_ME m16 : 23|8@0+ (1,0) [0|255] ""  PT
 SG_ ctrOffTimeSetPW_ME m20 : 31|16@0+ (1,0) [0|65535] ""  PT
 SG_ setCtrOffTime_ME m20 : 47|16@0+ (1,0) [0|65535] "s"  PT
 SG_ ovrwrtLimitsAliveCtr_ME m27 : 63|8@0+ (1,0) [0|255] ""  PT
 SG_ BMSIDmult27_ME m27 : 15|8@0+ (1,0) [0|255] ""  PT
 SG_ BMSIDmult26_ME m26 : 15|8@0+ (1,0) [0|255] ""  PT
 SG_ BMSIDmult25_ME m25 : 15|8@0+ (1,0) [0|255] ""  PT
 SG_ ovrwrtPassword_ME m27 : 23|16@0+ (1,0) [0|65535] ""  PT
 SG_ ovrwrtMaxTemperatureErrLimit_ME m27 : 55|8@0+ (1,-40) [-40|215] "C"  PT
 SG_ ovrwrtMaxBrickVoltageErrLimit_ME m27 : 47|8@0+ (0.02,0) [0|5.1] "V"  PT
 SG_ ovrwrtMinBrickVoltageErrLimit_ME m27 : 39|8@0+ (0.02,0) [0|5.1] "V"  PT
 SG_ BMSIDmult24_ME m24 : 15|8@0+ (1,0) [0|255] ""  PT
 SG_ writeBMSProdDatePassword_ME m24 : 23|16@0+ (1,0) [0|65535] ""  PT
 SG_ writeBMSProdDateYear_ME m24 : 39|8@0+ (1,0) [0|255] ""  PT
 SG_ writeBMSProdDateWeek_ME m24 : 47|8@0+ (1,0) [0|255] ""  PT
 SG_ writeBMSProdDatePatch_ME m24 : 55|8@0+ (1,0) [0|255] ""  PT
 SG_ BMSIDmult23_ME m23 : 15|8@0+ (1,0) [0|255] ""  PT
 SG_ resetHistoPassword_ME m23 : 23|16@0+ (1,0) [0|65535] ""  PT
 SG_ resetCntrHistograms_ME m23 : 39|8@0+ (1,0) [0|255] ""  PT
 SG_ BMSIDmult22_ME m22 : 15|8@0+ (1,0) [0|255] ""  PT
 SG_ contactorTypeResetPassword_ME m22 : 23|16@0+ (1,0) [0|65535] ""  PT
 SG_ contactorType_ME m22 : 39|8@0+ (1,0) [0|0] ""  PT
 SG_ BMSIDmult21_ME m21 : 15|8@0+ (1,0) [0|255] ""  PT
 SG_ SOHRecalDiagPassword_ME m21 : 23|16@0+ (1,0) [0|65535] ""  PT
 SG_ SOHBrickIndex_ME m21 : 39|12@0+ (1,0) [0|4095] ""  PT
 SG_ SOHValue_ME m21 : 55|16@0+ (0.01,0) [0|655.35] "PCT"  PT
 SG_ SOHType_ME m21 : 43|4@0+ (1,0) [0|15] ""  PT
 SG_ clearEventDebugExtIso_ME m14 : 55|8@0+ (1,0) [0|0] ""  PT
 SG_ clearEventDebugVPlausibility_ME m14 : 47|8@0+ (1,0) [0|0] ""  PT
 SG_ clearEventDebugHighSevCrash_ME m14 : 63|8@0+ (1,0) [0|0] ""  PT
 SG_ BMSIDmult20_ME m20 : 15|8@0+ (1,0) [0|0] ""  PT
 SG_ enableDbgMsgsPTCAN_ME m20 : 23|8@0+ (1,0) [0|0] ""  PT
 SG_ BMSIDmult19_ME m19 : 15|8@0+ (1,0) [0|0] ""  PT
 SG_ contactorRequestPos3_ME m19 : 47|8@0+ (1,0) [0|0] ""  PT
 SG_ contactorRequestNeg3_ME m19 : 55|8@0+ (1,0) [0|0] ""  PT
 SG_ contactorRequestPrechg2_ME m19 : 39|8@0+ (1,0) [0|0] ""  PT
 SG_ contactorRequestPos2_ME m19 : 23|8@0+ (1,0) [0|0] ""  PT
 SG_ contactorRequestNeg2_ME m19 : 31|8@0+ (1,0) [0|0] ""  PT
 SG_ BMSIDmult18_ME m18 : 15|8@0+ (1,0) [0|0] ""  PT
 SG_ BMSIDmult17_ME m17 : 15|8@0+ (1,0) [0|0] ""  PT
 SG_ commandPumpSpeed_ME m18 : 23|8@0+ (1,0) [0|0] "PCT"  PT
 SG_ pumpSpeedMaxLimit_ME m17 : 23|8@0+ (1,0) [0|255] "PCT"  PT
 SG_ isoSwRequestLink_ME m9 : 39|8@0+ (1,0) [0|0] ""  PT
 SG_ debugCtrlGPIO2_ME m15 : 47|8@0+ (1,0) [0|0] ""  PT
 SG_ debugCtrlGPIO1_ME m15 : 39|8@0+ (1,0) [0|0] ""  PT
 SG_ debugCtrlGPIsenseSel_ME m15 : 31|8@0+ (1,0) [0|0] ""  PT
 SG_ BMSIDmult16_ME m16 : 15|8@0+ (1,0) [0|0] ""  PT
 SG_ numberOfPacksPerString_ME m11 : 47|8@0+ (1,0) [0|0] ""  PT
 SG_ BMSIDmult15_ME m15 : 15|8@0+ (1,0) [0|0] ""  PT
 SG_ debugCtrlCurrentSense_ME m15 : 23|8@0+ (1,0) [0|0] ""  PT
 SG_ BMSIDmult14_ME m14 : 15|8@0+ (1,0) [0|0] ""  PT
 SG_ clearEventDebugVDeepDch_ME m14 : 39|8@0+ (1,0) [0|0] ""  PT
 SG_ clearEventDebugDiagPassword_ME m14 : 23|16@0+ (1,0) [0|0] ""  PT
 SG_ BMSIDmult13_ME m13 : 15|8@0+ (1,0) [0|0] ""  PT
 SG_ eventMapDebugDiagPassword_ME m13 : 23|16@0+ (1,0) [0|0] ""  PT
 SG_ eventMapDebugEventID_ME m13 : 39|16@0+ (1,0) [0|0] ""  PT
 SG_ BMSIDmult12_ME m12 : 15|8@0+ (1,0) [0|0] ""  PT
 SG_ energyThroughputDiagPassword_ME m12 : 23|16@0+ (1,0) [0|0] ""  PT
 SG_ energyThroughput_ME m12 : 39|32@0+ (1,0) [0|0] "kWh"  PT
 SG_ BMSIDmult11_ME m11 : 15|8@0+ (1,0) [0|0] ""  PT
 SG_ numberOfStrings_ME m11 : 39|8@0+ (1,0) [0|0] ""  PT
 SG_ numberOfStringsDiagPassword_ME m11 : 23|16@0+ (1,0) [0|0] ""  PT
 SG_ BMSIDmult10_ME m10 : 15|8@0+ (1,0) [0|0] ""  PT
 SG_ desiccantTimer_ME m10 : 39|32@0+ (1,0) [0|4294967295] "s"  PT
 SG_ isoSwRequestPos_ME m9 : 23|8@0+ (1,0) [0|0] ""  PT
 SG_ isoSwRequestNeg_ME m9 : 31|8@0+ (1,0) [0|0] ""  PT
 SG_ eepromDiagPassword_ME m3 : 39|16@0+ (1,0) [0|0] ""  PT
 SG_ eepromResetStruct_ME m3 : 23|16@0+ (1,0) [0|0] ""  PT
 SG_ BMSIDmult09_ME m9 : 15|8@0+ (1,0) [0|0] ""  PT
 SG_ BMSIDmult08_ME m8 : 15|8@0+ (1,0) [0|0] ""  PT
 SG_ BMSIDmult07_ME m7 : 15|8@0+ (1,0) [0|0] ""  PT
 SG_ BMSIDmult06_ME m6 : 15|8@0+ (1,0) [0|0] ""  PT
 SG_ BMSIDmult05_ME m5 : 15|8@0+ (1,0) [0|0] ""  PT
 SG_ ecuSerialNumberChar01_ME m7 : 23|8@0+ (1,0) [0|0] ""  PT
 SG_ ecuSerialNumberChar02_ME m7 : 31|8@0+ (1,0) [0|0] ""  PT
 SG_ ecuSerialNumberChar03_ME m7 : 39|8@0+ (1,0) [0|0] ""  PT
 SG_ ecuSerialNumberChar04_ME m7 : 47|8@0+ (1,0) [0|0] ""  PT
 SG_ ecuSerialNumberChar05_ME m7 : 55|8@0+ (1,0) [0|0] ""  PT
 SG_ ecuSerialNumberChar06_ME m7 : 63|8@0+ (1,0) [0|0] ""  PT
 SG_ ecuSerialNumberChar07_ME m8 : 23|8@0+ (1,0) [0|0] ""  PT
 SG_ ecuSerialNumberChar08_ME m8 : 31|8@0+ (1,0) [0|0] ""  PT
 SG_ ecuSerialNumberChar09_ME m8 : 39|8@0+ (1,0) [0|0] ""  PT
 SG_ ecuSerialNumberChar10_ME m8 : 47|8@0+ (1,0) [0|0] ""  PT
 SG_ ecuSerialNumberChar11_ME m8 : 55|8@0+ (1,0) [0|0] ""  PT
 SG_ ecuSerialNumberChar12_ME m8 : 63|8@0+ (1,0) [0|0] ""  PT
 SG_ ecuSerialNumberChar13_ME m25 : 23|8@0+ (1,0) [0|0] ""  PT
 SG_ ecuSerialNumberChar14_ME m25 : 31|8@0+ (1,0) [0|0] ""  PT
 SG_ ecuSerialNumberChar15_ME m25 : 39|8@0+ (1,0) [0|0] ""  PT
 SG_ ecuSerialNumberChar16_ME m25 : 47|8@0+ (1,0) [0|0] ""  PT
 SG_ ecuSerialNumberChar17_ME m25 : 55|8@0+ (1,0) [0|0] ""  PT
 SG_ ecuSerialNumberChar18_ME m25 : 63|8@0+ (1,0) [0|0] ""  PT
 SG_ ecuSerialNumberChar19_ME m26 : 23|8@0+ (1,0) [0|0] ""  PT
 SG_ eepromWritePageNrOfPages_ME m5 : 55|16@0+ (1,0) [0|65535] "B"  PT
 SG_ eepromWritePageStartAddress_ME m5 : 39|16@0+ (1,0) [0|65535] "B"  PT
 SG_ eepromWriteWord_ME m5 : 23|16@0+ (1,0) [0|0] ""  PT
 SG_ eepromReadCount_ME m6 : 63|8@0+ (1,0) [0|255] "B"  PT
 SG_ BMSIDmult04_ME m4 : 15|8@0+ (1,0) [0|0] ""  PT
 SG_ eepromWriteByte_ME m4 : 55|8@0+ (1,0) [0|0] ""  PT
 SG_ eepromReadAddress_ME m6 : 23|16@0+ (1,0) [0|65535] "B"  PT
 SG_ eepromWriteByteToAddress_ME m4 : 39|16@0+ (1,0) [0|65535] "B"  PT
 SG_ balancingVoltageThreshold_ME m1 : 63|8@0+ (0.02,0) [0|5.1] "V"  PT
 SG_ BMSIDmult03_ME m3 : 15|8@0+ (1,0) [0|0] ""  PT
 SG_ BMSIDmult02_ME m2 : 15|8@0+ (1,0) [0|0] ""  PT
 SG_ BMSIDmult01_ME m1 : 15|8@0+ (1,0) [0|0] ""  PT
 SG_ sleepRequest_ME m1 : 55|8@0+ (1,0) [0|0] ""  PT
 SG_ heaterRequestCMB_ME m2 : 47|24@0+ (1,0) [0|0] ""  PT
 SG_ contactorRequestPrechg_ME m1 : 31|8@0+ (1,0) [0|0] ""  PT
 SG_ contactorRequestPos_ME m1 : 39|8@0+ (1,0) [0|0] ""  PT
 SG_ contactorRequestNeg_ME m1 : 23|8@0+ (1,0) [0|0] ""  PT
 SG_ balancingRequestCMB_ME m2 : 23|24@0+ (1,0) [0|0] ""  PT
 SG_ balancingRequestIndex_ME m1 : 47|8@0+ (1,0) [0|0] ""  PT
 SG_ commandMultiplexor_ME M : 7|8@0+ (1,0) [0|0] ""  PT

BO_ 384 BMS01_EnergyThroughput: 4 BMS
 SG_ energyThroughput_KWh_BMS01 : 7|32@0+ (0.01,0) [0|42949672.95] "KWh"  BMS

BO_ 369 BMS_FKTAnswer: 4 BMS
 SG_ fktSeed : 7|32@0+ (1,0) [0|0] "" Vector__XXX

BO_ 368 BMS_FKTCommand: 5 Vector__XXX
 SG_ fktKey : 15|32@0+ (1,0) [0|0] "" Vector__XXX
 SG_ fktCommand : 7|8@0+ (1,0) [0|0] "" Vector__XXX

BO_ 352 BMS01_ObdDTCInfo: 5 BMS
 SG_ obdTestFailed_BMS01 : 32|1@0+ (1,0) [0|1] ""  BMS
 SG_ obdOccurrence_BMS01 : 39|7@0+ (1,0) [0|126] ""  BMS
 SG_ obdClearFaultMemory_BMS01 : 7|8@0+ (1,0) [0|1] ""  BMS
 SG_ obdDTCOdometer_BMS01 : 23|16@0+ (1,0) [0|65535] "km"  BMS
 SG_ obdDTCId_BMS01 : 15|8@0+ (1,0) [0|255] ""  BMS

BO_ 336 BMS01_SOCIndeces: 4 BMS
 SG_ maxSOCIndex_BMS01 : 23|16@0+ (1,0) [0|65535] ""  BMS
 SG_ minSOCIndex_BMS01 : 7|16@0+ (1,0) [0|65535] ""  BMS

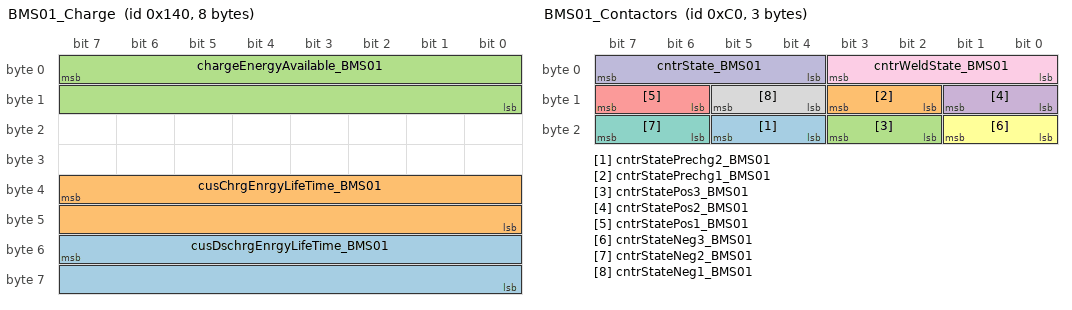
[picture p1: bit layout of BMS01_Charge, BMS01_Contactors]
BO_ 320 BMS01_Charge: 8 BMS
 SG_ cusDschrgEnrgyLifeTime_BMS01 : 55|16@0+ (0.1,0) [0|1310.7] "MWh"  BMS
 SG_ cusChrgEnrgyLifeTime_BMS01 : 39|16@0+ (0.1,0) [0|1310.7] "MWh"  BMS
 SG_ chargeEnergyAvailable_BMS01 : 7|16@0+ (0.01,0) [0|0] "kWh"  BMS

BO_ 208 BMS01_StringShutdown: 3 BMS
 SG_ stringShutdownTarget_BMS01 : 19|4@0+ (1,0) [0|0] ""  BMS
 SG_ stringShutdownTimer_BMS01 : 7|16@0+ (1,0) [0|0] ""  BMS

BO_ 192 BMS01_Contactors: 3 BMS
 SG_ cntrStatePrechg2_BMS01 : 21|2@0+ (1,0) [0|0] ""  BMS
 SG_ cntrStatePrechg1_BMS01 : 11|2@0+ (1,0) [0|0] ""  BMS
 SG_ cntrStatePos3_BMS01 : 19|2@0+ (1,0) [0|0] ""  BMS
 SG_ cntrStatePos2_BMS01 : 9|2@0+ (1,0) [0|0] ""  BMS
 SG_ cntrStatePos1_BMS01 : 15|2@0+ (1,0) [0|0] ""  BMS
 SG_ cntrStateNeg3_BMS01 : 17|2@0+ (1,0) [0|0] ""  BMS
 SG_ cntrStateNeg2_BMS01 : 23|2@0+ (1,0) [0|0] ""  BMS
 SG_ cntrStateNeg1_BMS01 : 13|2@0+ (1,0) [0|0] ""  BMS
 SG_ cntrWeldState_BMS01 : 3|4@0+ (1,0) [0|0] ""  BMS
 SG_ cntrState_BMS01 : 7|4@0+ (1,0) [0|0] ""  BMS

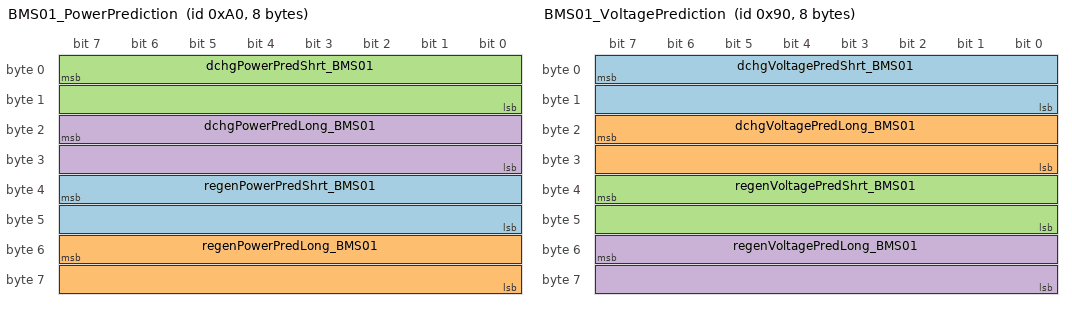
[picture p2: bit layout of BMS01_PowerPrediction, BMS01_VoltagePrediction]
BO_ 160 BMS01_PowerPrediction: 8 BMS
 SG_ regenPowerPredShrt_BMS01 : 39|16@0+ (0.01,0) [0|650] "kW"  BMS
 SG_ regenPowerPredLong_BMS01 : 55|16@0+ (0.01,0) [0|650] "kW"  BMS
 SG_ dchgPowerPredShrt_BMS01 : 7|16@0+ (0.01,0) [0|650] "kW"  BMS
 SG_ dchgPowerPredLong_BMS01 : 23|16@0+ (0.01,0) [0|650] "kW"  BMS

BO_ 176 BMS01_CellVLimits: 8 BMS
 SG_ cusMaxCellVLimit_BMS01 : 23|16@0+ (0.0001,0) [0|6.5] "V"  BMS
 SG_ cusMinCellVLimit_BMS01 : 7|16@0+ (0.0001,0) [0|6.5] "V"  BMS

BO_ 144 BMS01_VoltagePrediction: 8 BMS
 SG_ dchgVoltagePredShrt_BMS01 : 7|16@0+ (0.02,0) [0|1200] "V"  BMS
 SG_ dchgVoltagePredLong_BMS01 : 23|16@0+ (0.02,0) [0|1200] "V"  BMS
 SG_ regenVoltagePredShrt_BMS01 : 39|16@0+ (0.02,0) [0|1200] "V"  BMS
 SG_ regenVoltagePredLong_BMS01 : 55|16@0+ (0.02,0) [0|1200] "V"  BMS

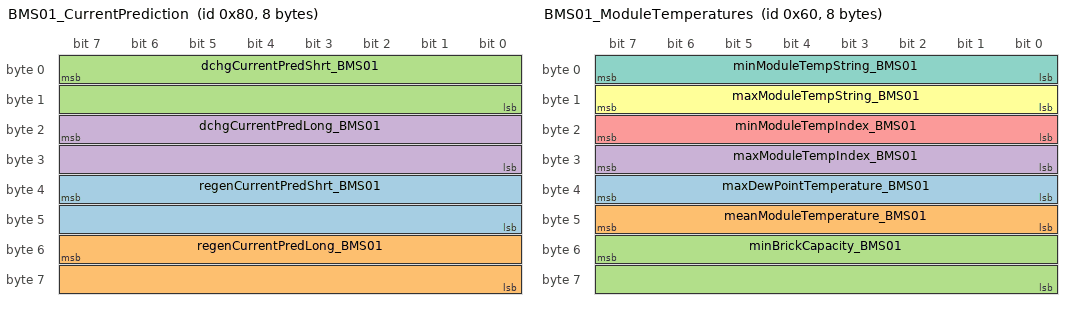
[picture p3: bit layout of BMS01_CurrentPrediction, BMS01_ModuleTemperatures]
BO_ 128 BMS01_CurrentPrediction: 8 BMS
 SG_ regenCurrentPredShrt_BMS01 : 39|16@0+ (0.05,0) [0|3200] "A"  BMS
 SG_ regenCurrentPredLong_BMS01 : 55|16@0+ (0.05,0) [0|3200] "A"  BMS
 SG_ dchgCurrentPredShrt_BMS01 : 7|16@0+ (0.05,0) [0|3200] "A"  BMS
 SG_ dchgCurrentPredLong_BMS01 : 23|16@0+ (0.05,0) [0|3200] "A"  BMS

BO_ 96 BMS01_ModuleTemperatures: 8 BMS
 SG_ maxDewPointTemperature_BMS01 : 39|8@0+ (0.5,-40) [-40|87.5] "C"  BMS
 SG_ meanModuleTemperature_BMS01 : 47|8@0+ (0.5,-40) [-40|87.5] "C"  BMS
 SG_ minBrickCapacity_BMS01 : 55|16@0+ (20,0) [0|1310700] "As"  BMS
 SG_ maxModuleTempIndex_BMS01 : 31|8@0+ (1,0) [0|255] ""  BMS
 SG_ minModuleTempIndex_BMS01 : 23|8@0+ (1,0) [0|255] ""  BMS
 SG_ maxModuleTempString_BMS01 : 15|8@0+ (0.5,-40) [-40|87.5] "C"  BMS
 SG_ minModuleTempString_BMS01 : 7|8@0+ (0.5,-40) [-40|87.5] "C"  BMS

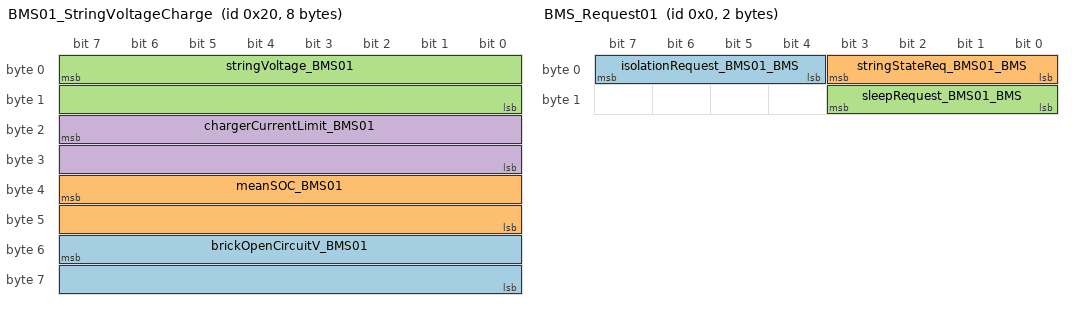
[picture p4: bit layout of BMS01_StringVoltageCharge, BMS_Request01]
BO_ 32 BMS01_StringVoltageCharge: 8 BMS
 SG_ brickOpenCircuitV_BMS01 : 55|16@0+ (0.0001,0) [0|6.5] "V"  BMS
 SG_ meanSOC_BMS01 : 39|16@0+ (0.01,0) [0|100] "PCT"  BMS
 SG_ stringVoltage_BMS01 : 7|16@0+ (0.02,0) [0|1200] "V"  BMS
 SG_ chargerCurrentLimit_BMS01 : 23|16@0+ (0.05,0) [0|3200] "A"  BMS

BO_ 0 BMS_Request01: 2 BMS
 SG_ isolationRequest_BMS01_BMS : 7|4@0+ (1,0) [0|0] ""  BMS
 SG_ stringStateReq_BMS01_BMS : 3|4@0+ (1,0) [0|0] ""  BMS
 SG_ sleepRequest_BMS01_BMS : 11|4@0+ (1,0) [0|0] ""  BMS

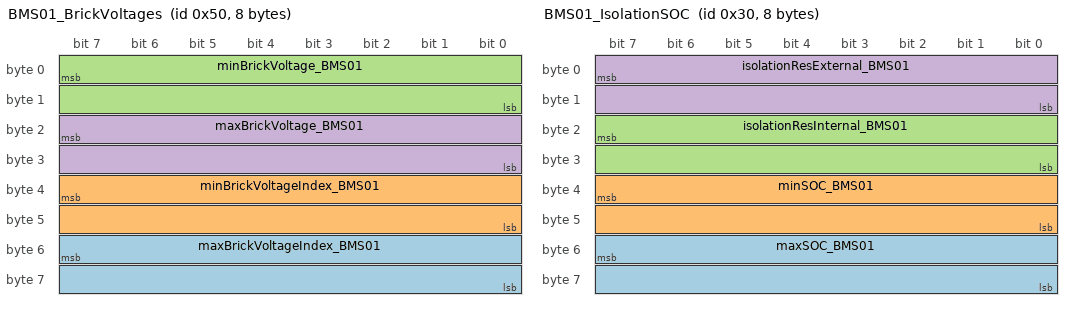
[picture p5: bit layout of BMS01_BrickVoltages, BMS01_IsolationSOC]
BO_ 80 BMS01_BrickVoltages: 8 BMS
 SG_ maxBrickVoltageIndex_BMS01 : 55|16@0+ (1,0) [0|65535] ""  BMS
 SG_ minBrickVoltageIndex_BMS01 : 39|16@0+ (1,0) [0|65535] ""  BMS
 SG_ minBrickVoltage_BMS01 : 7|16@0+ (0.0001,0) [0|6.5] "V"  BMS
 SG_ maxBrickVoltage_BMS01 : 23|16@0+ (0.0001,0) [0|6.5] "V"  BMS

BO_ 48 BMS01_IsolationSOC: 8 BMS
 SG_ maxSOC_BMS01 : 55|16@0+ (0.01,0) [0|100] "PCT"  BMS
 SG_ minSOC_BMS01 : 39|16@0+ (0.01,0) [0|100] "PCT"  BMS
 SG_ isolationResInternal_BMS01 : 23|16@0+ (2,0) [0|130000] "kOhm"  BMS
 SG_ isolationResExternal_BMS01 : 7|16@0+ (2,0) [0|130000] "kOhm"  BMS

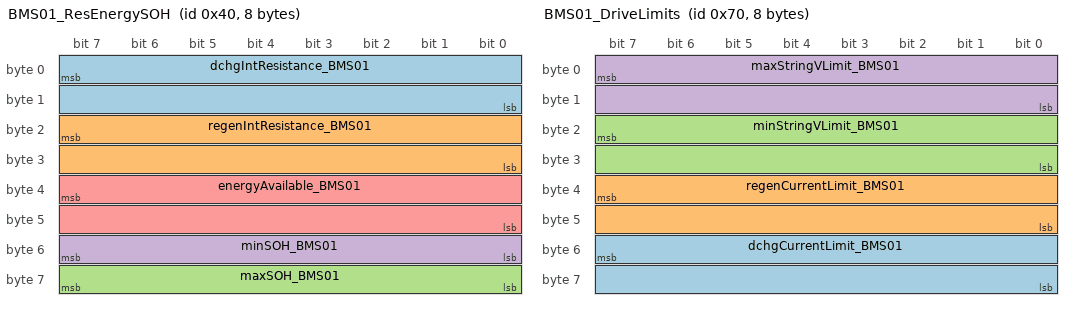
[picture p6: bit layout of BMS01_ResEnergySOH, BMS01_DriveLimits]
BO_ 64 BMS01_ResEnergySOH: 8 BMS
 SG_ dchgIntResistance_BMS01 : 7|16@0+ (0.05,0) [0|3276.75] "mOhm"  BMS
 SG_ regenIntResistance_BMS01 : 23|16@0+ (0.05,0) [0|3276.75] "mOhm"  BMS
 SG_ maxSOH_BMS01 : 63|8@0+ (0.5,0) [0|120] "PCT"  BMS
 SG_ minSOH_BMS01 : 55|8@0+ (0.5,0) [0|120] "PCT"  BMS
 SG_ energyAvailable_BMS01 : 39|16@0+ (0.01,0) [0|650] "kWh"  BMS

BO_ 112 BMS01_DriveLimits: 8 BMS
 SG_ dchgCurrentLimit_BMS01 : 55|16@0+ (0.05,0) [0|3200] "A"  BMS
 SG_ regenCurrentLimit_BMS01 : 39|16@0+ (0.05,0) [0|3200] "A"  BMS
 SG_ minStringVLimit_BMS01 : 23|16@0+ (0.02,0) [0|1200] "V"  BMS
 SG_ maxStringVLimit_BMS01 : 7|16@0+ (0.02,0) [0|1200] "V"  BMS

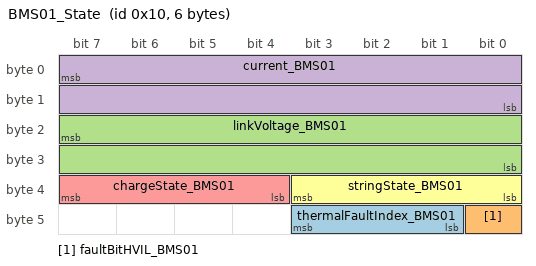
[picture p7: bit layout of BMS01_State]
BO_ 16 BMS01_State: 6 BMS
 SG_ thermalFaultIndex_BMS01 : 43|3@0+ (1,0) [0|7] "" Vector__XXX
 SG_ faultBitHVIL_BMS01 : 40|1@0+ (1,0) [0|1] ""  BMS
 SG_ linkVoltage_BMS01 : 23|16@0+ (0.02,0) [0|1200] "V"  BMS
 SG_ current_BMS01 : 7|16@0+ (0.1,-3200) [-3200|3353.5] "A"  BMS
 SG_ chargeState_BMS01 : 39|4@0+ (1,0) [0|15] ""  BMS
 SG_ stringState_BMS01 : 35|4@0+ (1,0) [0|0] ""  BMS

CM_ SG_ 1600 cmbMaxSM15ratio_SC01 "Max difference between balanced and non balanced sampling";
CM_ SG_ 1600 cmbMinSM15ratio_SC01 "Min difference between balanced and non balanced sampling";
CM_ SG_ 1600 cmbMinSM17Ratio "The min ratio obsereved between Sn& Cn-1 and Cn & Cn-1";
CM_ SG_ 1600 cmbMaxSM17Ratio "The max ratio obsereved between Sn& Cn-1 and Cn & Cn-1";
CM_ SG_ 1600 cmbMaxSM16DiffC2S_SC01 "Max difference between (C to Cn-1) Measurement pin  and (Sn to Sn-1) balancing pin of CMB 
This will show the leakage from measurement pin to balancing pin";
CM_ SG_ 1600 safetyHangLastLinkReg_SC01 "Only sent if valid safety hang attributes are being stored in FEE sectror 3. ";
CM_ SG_ 1600 safetyHangPresentLinkReg_SC01 "Only sent if valid safety hang attributes are being stored in FEE sectror 3. ";
CM_ SG_ 1600 safetyHangDataFaultStatus_SC01 "Only sent if valid safety hang attributes are being stored in FEE sectror 3. ";
CM_ SG_ 1600 safetyHangDataFaultAddr_SC01 "Only sent if valid safety hang attributes are being stored in FEE sectror 3. ";
CM_ SG_ 1600 safetyHangLastARMMode_SC01 "Only sent if valid safety hang attributes are being stored in FEE sectror 3. ";
CM_ SG_ 1600 safetyHangPresARMMode_SC01 "Only sent if valid safety hang attributes are being stored in FEE sectror 3. ";
CM_ SG_ 1600 safetyHangESMGrp3Reg_SC01 "Only sent if valid safety hang attributes are being stored in FEE sectror 3. ";
CM_ SG_ 1600 safetyHangInstrFaultStatus_SC01 "Only sent if valid safety hang attributes are being stored in FEE sectror 3. ";
CM_ SG_ 1600 safetyHangInstrFaultAddr_SC01 "Only sent if valid safety hang attributes are being stored in FEE sectror 3. ";
CM_ SG_ 1600 cmbSM4MinIndex_SC01 "Value index of minimum delta voltage between balancing on and off / cmbMinSM27VDiff_SC01";
CM_ SG_ 1600 cmbSM27MinIndex_SC01 "Value index of minimum delta voltage between balancing on and off / cmbMinSM27VDiff_SC01";
CM_ SG_ 1600 selfTestErrorAddress_SC01 "Flash memory address which caused the fault.If the controller tries to access the memory which has the invalid ECC, the address will be captured.";
CM_ SG_ 1600 selfTestDataFaultAddr_SC01 "Only sent if selfTest state is UNSAFE";
CM_ SG_ 1600 analogGPIO2Volt_SC01 "Voltage at GPIO 1";
CM_ SG_ 1600 analogGPIO1Volt_SC01 "Voltage at GPIO 1";
CM_ SG_ 1600 cmbMaxUpdateTime_SC01 "Total time in ms it look to go through one CMB communication task";
CM_ SG_ 1600 cmbAvgUpdateTime_SC01 "Total time in ms it look to go through one CMB communication task";
CM_ SG_ 1600 moduleCount_SC01 "Number of CMBs (modules) connected to the Safety Controller.";
CM_ SG_ 1600 cmbMaxDiagStepPeriodicity_SC01 "Total time in ms it look to go through one CMB communication task";
CM_ SG_ 1600 safetyInitTime_SC01 "Time for all packets in ms. Maximum of ECU cycle.";
CM_ SG_ 1600 sbcWUAuto_SC01 "Auto wakeup is triggered when SBC is commanded to do a reset using SPI interface (e.g. bootloading process)";
CM_ SG_ 1600 sbcWUUnknown_SC01 "SPI communication to SBC failed. Wake up source unknow.";
CM_ SG_ 1600 sbcWUDebug_SC01 "This flag is set, when safety controller tries to read wake up source from SBC, after SBC has left INIT mode, which happens on JTAG debugging";
CM_ SG_ 1600 analogPressureSense_SC01 "The voltage output of the pressure sensor. Note that the pressure sensor pinning varies from config to config. This variable outputs the voltage measured at the pin which is defined for the pressure sensor.";
CM_ SG_ 1600 sumOfCurrentsFiltered_SC01 "CurrentLocal.outputs.sumOfCurrentThroughParallelModulesFiltered_A ";
CM_ SG_ 1600 analogHallSupply_SC01 "Calibrated Hall Sensor Supply Voltage";
CM_ SG_ 1664 selfTestFaultCntrCtrl_SC01 "When the diagnostic bit DIAGNOSTICBIT_CCTRL_SELFTEST is being set, this signal provides the further information indicating which self test is being failed.";
CM_ SG_ 1664 cmbASICFault_SC01 "Signal indicates the fault inside the ASIC that would impact bothe brick voltages and module temperatures.";
CM_ SG_ 1664 DIGIO_GPIO1_ON_SC01 "Pin Status of GPIO 1 Pin of Safety Controller";
CM_ SG_ 1664 DIGIO_ZDW_LSD_EN_SC01 "Pin Status of Pin ZDW_LSD_EN";
CM_ SG_ 1664 cmbLastUpdateTime_SC01 "Total time in ms it look to go through one CMB communication task";
CM_ SG_ 1664 SPIRxTxTimeAllPckts_SC01 "Time for all packets in ms. Maximum of ECU cycle.";
CM_ BO_ 768 "Master BMS Debug Message";
CM_ SG_ 768 essMstrChargeDerateFlag_BMS "This is an input to MBRDI. The idea is that they can derate charge limits based on this input, prior to connecting another string (in cases where not all strings where connected to start with)";
CM_ SG_ 284 resetStatistics_ME "1 resets all of our statistics as defined in BBMS Spec";
CM_ SG_ 284 debugCtrlPyroEN_ME "Enable the low side switch of the pyro fuse; Set this to 0xf1 to fire it";
CM_ SG_ 369 fktSeed "The seed sent from app to FKT in the process of jumping to BL";
CM_ SG_ 368 fktKey "FKT Key for jumping to BL ";
CM_ SG_ 368 fktCommand "FKT command to jump to BL";
CM_ SG_ 352 obdTestFailed_BMS01 "Current status of the DTC";
CM_ SG_ 352 obdOccurrence_BMS01 "Occurrence count of the DTC";
CM_ SG_ 352 obdClearFaultMemory_BMS01 "Bit used to notify that Clear Fault Memory was triggered";
CM_ SG_ 352 obdDTCOdometer_BMS01 "Corresponding odometer value for the obdDTCId_BMS01";
CM_ SG_ 352 obdDTCId_BMS01 "DTC ID for OBD Master logic";
CM_ SG_ 160 regenPowerPredShrt_BMS01 "Current limit for discharging of all strings.";
CM_ SG_ 160 regenPowerPredLong_BMS01 "Current limit for discharging of all strings.";
CM_ SG_ 160 dchgPowerPredShrt_BMS01 "Current limit for discharging of all strings.";
CM_ SG_ 160 dchgPowerPredLong_BMS01 "Current limit for discharging of all strings.";
CM_ SG_ 176 cusMaxCellVLimit_BMS01 "Minimum brick voltage of all strings.";
CM_ SG_ 176 cusMinCellVLimit_BMS01 "Minimum brick voltage of all strings.";
CM_ SG_ 144 dchgVoltagePredShrt_BMS01 "Minimum string voltage of all strings.";
CM_ SG_ 144 dchgVoltagePredLong_BMS01 "Minimum string voltage of all strings.";
CM_ SG_ 144 regenVoltagePredShrt_BMS01 "Minimum string voltage of all strings.";
CM_ SG_ 144 regenVoltagePredLong_BMS01 "Minimum string voltage of all strings.";
CM_ SG_ 128 regenCurrentPredShrt_BMS01 "Current limit for discharging of all strings.";
CM_ SG_ 128 regenCurrentPredLong_BMS01 "Current limit for discharging of all strings.";
CM_ SG_ 128 dchgCurrentPredShrt_BMS01 "Current limit for discharging of all strings.";
CM_ SG_ 128 dchgCurrentPredLong_BMS01 "Current limit for discharging of all strings.";
CM_ SG_ 32 brickOpenCircuitV_BMS01 "Minimum string voltage of all strings.";
CM_ SG_ 32 meanSOC_BMS01 "Minimum SOC of all strings.";
CM_ SG_ 32 stringVoltage_BMS01 "Minimum string voltage of all strings.";
CM_ SG_ 32 chargerCurrentLimit_BMS01 "Current limit for charging of all strings.";
CM_ SG_ 0 isolationRequest_BMS01_BMS "Optional disabling of isolation monitoring.";
CM_ SG_ 0 stringStateReq_BMS01_BMS "BMS state request.";
CM_ SG_ 0 sleepRequest_BMS01_BMS "Sleep request to command the BMS to go to sleep.";
CM_ SG_ 80 minBrickVoltage_BMS01 "Minimum brick voltage of all strings.";
CM_ SG_ 80 maxBrickVoltage_BMS01 "Maximum brick voltage of all strings.";
CM_ SG_ 48 maxSOC_BMS01 "Minimum SOC of all strings.";
CM_ SG_ 48 minSOC_BMS01 "Minimum SOC of all strings.";
CM_ SG_ 48 isolationResInternal_BMS01 "Minimum isolation resistance of all strings.";
CM_ SG_ 48 isolationResExternal_BMS01 "Isolation resistance of the overall system.";
CM_ SG_ 64 dchgIntResistance_BMS01 "Minimum string voltage of all strings.";
CM_ SG_ 64 regenIntResistance_BMS01 "Minimum string voltage of all strings.";
CM_ SG_ 64 maxSOH_BMS01 "Minimum SOC of all strings.";
CM_ SG_ 64 minSOH_BMS01 "Minimum SOC of all strings.";
CM_ SG_ 64 energyAvailable_BMS01 "Energy available of all strings.";
CM_ SG_ 112 dchgCurrentLimit_BMS01 "Current limit for discharging of all strings.";
CM_ SG_ 112 regenCurrentLimit_BMS01 "Current limit for regenerating of all strings.";
CM_ SG_ 112 minStringVLimit_BMS01 "Minimum string voltage limit of all strings.";
CM_ SG_ 112 maxStringVLimit_BMS01 "Maximum string voltage limit of all strings.";
CM_ SG_ 16 thermalFaultIndex_BMS01 "Fault bit field
bit 0: String HVIL Fault bit
bit 1: String thermal event bit
bit 2-6: Reserved
bit 7: field SNA. If all bits are set then byte is SNA";
CM_ SG_ 16 faultBitHVIL_BMS01 "Fault bit field
bit 0: String HVIL Fault bit
bit 1: String thermal event bit
bit 2-6: Reserved
bit 7: field SNA. If all bits are set then byte is SNA";
CM_ SG_ 16 linkVoltage_BMS01 "DC link voltage.";
CM_ SG_ 16 current_BMS01 "Current of all strings.";
CM_ SG_ 16 chargeState_BMS01 "BMS state.";
CM_ SG_ 16 stringState_BMS01 "BMS state.";
BA_DEF_ SG_  "GenSigSendType" ENUM  "Cyclic","OnWrite","OnWriteWithRepetition","OnChange","OnChangeWithRepetition","IfActive","IfActiveWithRepetition","NoSigSendType";
BA_DEF_ BO_  "GenMsgCycleTime" INT 0 0;
BA_DEF_ BO_  "GenMsgSendType" ENUM  "Cyclic","not_used","not_used","not_used","not_used","Cyclic","not_used","IfActive","NoMsgSendType";
BA_DEF_DEF_  "GenSigSendType" "Cyclic";
BA_DEF_DEF_  "GenMsgCycleTime" 0;
BA_DEF_DEF_  "GenMsgSendType" "NoMsgSendType";
BA_ "GenMsgCycleTime" BO_ 1600 100;
BA_ "GenMsgCycleTime" BO_ 1664 10;
BA_ "GenMsgCycleTime" BO_ 1920 100;
BA_ "GenMsgCycleTime" BO_ 1984 100;
BA_ "GenMsgCycleTime" BO_ 768 100;
BA_ "GenMsgCycleTime" BO_ 772 100;
BA_ "SystemSignalLongSymbol" SG_ 1600 pumpMAHLEvoltageDeratingWarn_SC0 "pumpMAHLEvoltageDeratingWarn_SC01";
BA_ "SystemSignalLongSymbol" SG_ 1600 pumpMAHLEoverTemperatureDerWarn_ "pumpMAHLEoverTemperatureDerWarn_SC01";
BA_ "GenMsgCycleTime" BO_ 384 1000;
BA_ "GenMsgCycleTime" BO_ 352 1000;
BA_ "GenMsgCycleTime" BO_ 336 1000;
BA_ "GenMsgCycleTime" BO_ 320 1000;
BA_ "GenMsgCycleTime" BO_ 208 100;
BA_ "GenMsgCycleTime" BO_ 192 10;
BA_ "GenMsgCycleTime" BO_ 160 100;
BA_ "GenMsgCycleTime" BO_ 176 100;
BA_ "GenMsgCycleTime" BO_ 144 100;
BA_ "GenMsgCycleTime" BO_ 128 100;
BA_ "GenMsgCycleTime" BO_ 96 100;
BA_ "GenMsgCycleTime" BO_ 32 100;
BA_ "GenMsgCycleTime" BO_ 0 10;
BA_ "GenMsgCycleTime" BO_ 80 100;
BA_ "GenMsgCycleTime" BO_ 48 1000;
BA_ "GenMsgCycleTime" BO_ 64 1000;
BA_ "GenMsgCycleTime" BO_ 112 100;
BA_ "GenMsgCycleTime" BO_ 16 10;
VAL_ 1600 pumpMAHLEshortCircuitErr_SC01 1 "TRUE" 0 "FALSE" ;
VAL_ 1600 pumpMAHLElowLoadOpErr_SC01 1 "TRUE" 0 "FALSE" ;
VAL_ 1600 pumpMAHLEstallFaultErr_SC01 1 "TRUE" 0 "FALSE" ;
VAL_ 1600 pumpMAHLEvoltageDeratingWarn_SC0 1 "TRUE" 0 "FALSE" ;
VAL_ 1600 pumpMAHLEunderVoltageErr_SC01 1 "TRUE" 0 "FALSE" ;
VAL_ 1600 pumpMAHLEoverVoltageErr_SC01 1 "TRUE" 0 "FALSE" ;
VAL_ 1600 pumpMAHLEoverTemperatureDerWarn_ 1 "TRUE" 0 "FALSE" ;
VAL_ 1600 pumpMAHLEoverTemperatureErr_SC01 1 "TRUE" 0 "FALSE" ;
VAL_ 1600 pumpMAHLEoverCurrentErr_SC01 1 "TRUE" 0 "FALSE" ;
VAL_ 1600 pumpMAHLEinternalFaultErr_SC01 1 "TRUE" 0 "FALSE" ;
VAL_ 1600 pumpMAHLElinErr_SC01 1 "TRUE" 0 "FALSE" ;
VAL_ 1600 pressure2_SC01 255 "SNA" ;
VAL_ 1600 cmbSM29ScoutTempIndex_SC01 255 "SNA" ;
VAL_ 1600 cmbSM19ScoutPDO_SC01 65535 "SNA" ;
VAL_ 1600 isolationResInternRelaxed_SC01 65535 "SNA" ;
VAL_ 1600 cmbVariantCodingVoltage_SC01 65535 "SNA" ;
VAL_ 1600 appTask500HzMaxAvg_SC01 255 "SNA" ;
VAL_ 1600 safetyHangLastLinkReg_SC01 -1 "SNA" ;
VAL_ 1600 safetyHangPresentLinkReg_SC01 -1 "SNA" ;
VAL_ 1600 safetyHangDataFaultStatus_SC01 -1 "SNA" ;
VAL_ 1600 safetyHangDataFaultAddr_SC01 -1 "SNA" ;
VAL_ 1600 safetyHangLastARMMode_SC01 255 "MODE_UNKNOWN" 6 "MODE_SYS" 5 "MODE_UND" 4 "MODE_ABT" 3 "MODE_SVC" 2 "MODE_IRQ" 1 "MODE_FIQ" 0 "MODE_USER" ;
VAL_ 1600 safetyHangPresARMMode_SC01 255 "MODE_UNKNOWN" 6 "MODE_SYS" 5 "MODE_UND" 4 "MODE_ABT" 3 "MODE_SVC" 2 "MODE_IRQ" 1 "MODE_FIQ" 0 "MODE_USER" ;
VAL_ 1600 safetyHangESMGrp3Reg_SC01 -1 "SNA" ;
VAL_ 1600 safetyHangInstrFaultStatus_SC01 -1 "SNA" ;
VAL_ 1600 safetyHangInstrFaultAddr_SC01 -1 "SNA" ;
VAL_ 1600 eaglePackType_SC01 3 "SNA" 2 "EAGLE_UNKNOWN" 1 "EAGLE_CSAMPLE" 0 "EAGLE_BSAMPLE" ;
VAL_ 1600 pressure_SC01 255 "SNA" ;
VAL_ 1600 cmbMaxSM33Diff_SC01 255 "SNA" ;
VAL_ 1600 cmbMinSM29Diff_SC01 255 "SNA" ;
VAL_ 1600 cmbMinSM4Diff_SC01 65535 "SNA" ;
VAL_ 1600 cmbMaxSM4Diff_SC01 65535 "SNA" ;
VAL_ 1600 cmbMinSM27Diff_SC01 65535 "SNA" ;
VAL_ 1600 cmbMaxSM27Diff_SC01 65535 "SNA" ;
VAL_ 1600 adcDriverFail_SC01 12 "ADCDRIVER_SBCSUPPLY_FF" 11 "ADCDRIVER_MUX960_FF" 10 "ADCDRIVER_MUX910_FF" 9 "ADCDRIVER_UNDEF" 8 "ADCDRIVER_ADCVAR" 7 "ADCDRIVER_SLEEP_FF" 6 "ADCDRIVER_PYRO_FF" 5 "ADCDRIVER_MUX710_FF" 4 "ADCDRIVER_MUX440_FF" 3 "ADCDRIVER_MUX302A_FF" 2 "ADCDRIVER_MUX301B_FF" 1 "ADCDRIVER_MUX301A_FF" 0 "ADCDRIVER_NO_ISSUE" ;
VAL_ 1600 mainUcHvilState_SC01 2 "CANTX_HVIL_CLOSE" 3 "CANTX_HVIL_SNA" 1 "CANTX_HVIL_OPEN" 0 "CANTX_HVIL_NOT_AVAIL" ;
VAL_ 1600 mainUcIntIsoErr_SC01 3 "ISOLATION_SNA" 2 "ISOLATION_ERR_OFF" 1 "ISOLATION_ERROR" 0 "ISOLATION_OK" ;
VAL_ 1600 mainUcExtIsoErr_SC01 3 "ISOLATION_SNA" 2 "ISOLATION_ERR_OFF" 1 "ISOLATION_ERROR" 0 "ISOLATION_OK" ;
VAL_ 1600 safetyUcThermalStatus_SC01 3 "THERMALEVENT_SNA" 2 "THERMALEVENT_WARN_2" 1 "THERMALEVENT_WARN_1" 0 "THERMALEVENT_NO_WARN" ;
VAL_ 1600 mainUcThermalStatus_SC01 3 "THERMALEVENT_SNA" 2 "THERMALEVENT_WARN_2" 1 "THERMALEVENT_WARN_1" 0 "THERMALEVENT_NO_WARN" ;
VAL_ 1600 selfTestDataFaultStatus_SC01 -1 "SNA" ;
VAL_ 1600 selfTestInstrFaultAddr_SC01 -1 "SNA" ;
VAL_ 1600 selfTestDataFaultAddr_SC01 -1 "SNA" ;
VAL_ 1600 selfTestInstrFaultStatus_SC01 -1 "SNA" ;
VAL_ 1600 internalIsolationError_SC01 3 "ISOLATION_SNA" 2 "ISOLATION_ERR_OFF" 1 "ISOLATION_ERROR" 0 "ISOLATION_OK" ;
VAL_ 1600 externalIsolationError_SC01 3 "ISOLATION_SNA" 2 "ISOLATION_ERR_OFF" 1 "ISOLATION_ERROR" 0 "ISOLATION_OK" ;
VAL_ 1600 isolationTestState_SC01 3 "ISOLATION_TEST_POSNEG" 2 "ISOLATION_TEST_NEG" 1 "ISOLATION_TEST_POS" 0 "ISOLATION_OFF" ;
VAL_ 1600 isolationResistanceIntern_SC01 65535 "SNA" ;
VAL_ 1600 isolationResistanceExtern_SC01 65535 "SNA" ;
VAL_ 1600 maxAdolV13Diff_SC01 65535 "SNA" ;
VAL_ 1600 pumpType_SC01 2 "PUMPAMG_JOMA" 1 "PUMPAMG_BOSCH" 0 "PUMPAMG_NONE" 255 "SNA" ;
VAL_ 1600 pumpJomaLinErr_SC01 1 "TRUE" 0 "FALSE" ;
VAL_ 1600 pumpJomaPumpState_SC01 6 "ERROR" 5 "HARDWARE_ERROR" 1 "RUN" 0 "IDLE" 7 "SNA" ;
VAL_ 1600 pumpBoschPwmInStat_SC01 1 "HIGH" 0 "LOW" 3 "SNA" ;
VAL_ 1600 pumpBoschRpmMonStat_SC01 1 "NO_MON" 0 "MON_ACTIVE" 3 "SNA" ;
VAL_ 1600 pumpBoschWakeupStat_SC01 2 "NDEF2" 1 "ACTIVE_WUP" 0 "NO_WUP" 3 "SNA" ;
VAL_ 1600 pumpBoschPostRunMode_SC01 7 "SNA" 4 "SPEED_4" 3 "SPEED_3" 2 "SPEED_2" 1 "SPEED_1" 0 "NO_POST_RUN" ;
VAL_ 1600 pumpPhaseCurrent_SC01 255 "SNA" ;
VAL_ 1600 hvWithstandTestQual_SC01 1 "QUAL_ERROR" 0 "QUAL_VALID" ;
VAL_ 1600 currentModuleMax_SC01 65535 "SNA" ;
VAL_ 1600 currentModuleMin_SC01 65535 "SNA" ;
VAL_ 1600 maxCMBDieTemp_SC01 255 "SNA" ;
VAL_ 1600 minCMBDieTemp_SC01 255 "SNA" ;
VAL_ 1600 pumpBoschSuppVoltErr_SC01 1 "ERROR" 0 "NO_ERROR" 3 "SNA" ;
VAL_ 1600 pumpBoschOverTempErr_SC01 1 "ERROR" 0 "NO_ERROR" 3 "SNA" ;
VAL_ 1600 pumpBoschOverCurrErr_SC01 1 "ERROR" 0 "NO_ERROR" 3 "SNA" ;
VAL_ 1600 pumpBoschElectricErr_SC01 1 "ERROR" 0 "NO_ERROR" 3 "SNA" ;
VAL_ 1600 pumpBoschDryRunErr_SC01 1 "ERROR" 0 "NO_ERROR" 3 "SNA" ;
VAL_ 1600 pumpBoschBlockErr_SC01 0 "NO_ERROR" 1 "ERROR" 3 "SNA" ;
VAL_ 1600 appTaskSpiRxTx_SC01 255 "SNA" ;
VAL_ 1600 variantCodingCounts_SC01 255 "SNA" ;
VAL_ 1600 cmbMaxUpdateTime_SC01 255 "SNA" ;
VAL_ 1600 pumpSetSpeed_SC01 255 "SNA" ;
VAL_ 1600 hvilResistance_SC01 255 "SNA" ;
VAL_ 1600 cmbAvgUpdateTime_SC01 255 "SNA" ;
VAL_ 1600 pumpTemperature_SC01 255 "SNA" ;
VAL_ 1600 pumpSpeed_SC01 255 "SNA" ;
VAL_ 1600 pumpVoltage_SC01 255 "SNA" ;
VAL_ 1600 pumpCurrent_SC01 255 "SNA" ;
VAL_ 1600 posLink3_SC01 65535 "SNA" ;
VAL_ 1600 negLink3_SC01 65535 "SNA" ;
VAL_ 1600 posLink2_SC01 65535 "SNA" ;
VAL_ 1600 negLink2_SC01 65535 "SNA" ;
VAL_ 1600 cmbNrOfSamples_SC01 65535 "SNA" ;
VAL_ 1600 cmbTaskTime_SC01 65535 "SNA" ;
VAL_ 1600 appTask500HzMax_SC01 255 "SNA" ;
VAL_ 1600 analogHallSense_SC01 65535 "SNA" ;
VAL_ 1600 cmbMaxDiagStepPeriodicity_SC01 255 "SNA" ;
VAL_ 1600 minBrickVoltageLimit_SC01 65535 "SNA" ;
VAL_ 1600 appTask100Hz_SC01 255 "SNA" ;
VAL_ 1600 appTask10Hz_SC01 255 "SNA" ;
VAL_ 1600 appTaskAnalog_SC01 255 "SNA" ;
VAL_ 1600 appTaskADC_SC01 255 "SNA" ;
VAL_ 1600 appTask500HzAvg_SC01 255 "SNA" ;
VAL_ 1600 appTaskSBC_SC01 255 "SNA" ;
VAL_ 1600 appTaskCMBDriver_SC01 255 "SNA" ;
VAL_ 1600 safetyInitTime_SC01 255 "SNA" ;
VAL_ 1600 debugSlowMpex_SC01 44 "S44" 43 "S43" 42 "S42" 41 "S41" 0 "S00" 1 "S01" 2 "S02" 3 "S03" 4 "S04" 5 "S05" 6 "S06" 7 "S07" 8 "S08" 9 "S09" 10 "S10" 11 "S11" 12 "S12" 13 "S13" 14 "S14" 15 "S15" 16 "S16" 17 "S17" 18 "S18" 19 "S19" 20 "S20" 21 "S21" 22 "S22" 23 "S23" 24 "S24" 25 "S25" 26 "S26" 27 "S27" 28 "S28" 29 "S29" 30 "S30" 31 "S31" 32 "S32" 33 "S33" 34 "S34" 35 "S35" 36 "S36" 37 "S37" 38 "S38" 39 "S39" 40 "S40" ;
VAL_ 1600 mux440Gnd_SC01 255 "SNA" ;
VAL_ 1600 analogHallGain_SC01 65535 "SNA" ;
VAL_ 1600 analogHallOffset_SC01 255 "SNA" ;
VAL_ 1600 negPackPrime_SC01 65535 "SNA" ;
VAL_ 1600 posPackPrime_SC01 65535 "SNA" ;
VAL_ 1600 packVoltage_SC01 65535 "SNA" ;
VAL_ 1600 sleepTime_SC01 65535 "SNA" ;
VAL_ 1600 analogNegHVOffset_SC01 255 "SNA" ;
VAL_ 1600 analogPosHVOffset_SC01 255 "SNA" ;
VAL_ 1600 analogNegHVGain_SC01 65535 "SNA" ;
VAL_ 1600 analogPosHVGain_SC01 65535 "SNA" ;
VAL_ 1600 mux910Gnd_SC01 255 "SNA" ;
VAL_ 1600 mux960Gnd_SC01 255 "SNA" ;
VAL_ 1600 analogAddr5_SC01 65535 "SNA" ;
VAL_ 1600 analogAddr4_SC01 65535 "SNA" ;
VAL_ 1600 analogAddr3_SC01 65535 "SNA" ;
VAL_ 1600 analogAddr2_SC01 65535 "SNA" ;
VAL_ 1600 analogAddr1_SC01 65535 "SNA" ;
VAL_ 1600 analogAddr0_SC01 65535 "SNA" ;
VAL_ 1600 sbcVREF2P5_SC01 255 "SNA" ;
VAL_ 1600 mux910N3VRef_SC01 65535 "SNA" ;
VAL_ 1600 mux910P2P5VRef_SC01 65535 "SNA" ;
VAL_ 1600 analogHvilCurrentPWM_SC01 255 "SNA" ;
VAL_ 1600 analogSBCSupply_SC01 255 "SNA" ;
VAL_ 1600 analogHvilCurrent_SC01 255 "SNA" ;
VAL_ 1600 analogPressureSense_SC01 255 "SNA" ;
VAL_ 1600 analog5VSensorSupply_SC01 255 "SNA" ;
VAL_ 1600 analogPrechgRel2CoilMinus_SC01 255 "SNA" ;
VAL_ 1600 analogPrechgRel1CoilMinus_SC01 255 "SNA" ;
VAL_ 1600 analogNegCntr3CoilMinus_SC01 255 "SNA" ;
VAL_ 1600 analogNegCntr2CoilMinus_SC01 255 "SNA" ;
VAL_ 1600 analogNegCntr1CoilMinus_SC01 255 "SNA" ;
VAL_ 1600 analogPosCntr3CoilMinus_SC01 255 "SNA" ;
VAL_ 1600 analogPosCntr2CoilMinus_SC01 255 "SNA" ;
VAL_ 1600 analogPosCntr1CoilMinus_SC01 255 "SNA" ;
VAL_ 1600 minModuleTemperature_SC01 255 "SNA" ;
VAL_ 1600 maxModuleTemperature_SC01 255 "SNA" ;
VAL_ 1600 analogHvilReturn_SC01 255 "SNA" ;
VAL_ 1600 analog5VDSupply_SC01 255 "SNA" ;
VAL_ 1600 analogHvilOut_SC01 255 "SNA" ;
VAL_ 1600 analogCurrentSensor12V_SC01 255 "SNA" ;
VAL_ 1600 maxVREF2_SC01 65535 "SNA" ;
VAL_ 1600 minVREF2_SC01 65535 "SNA" ;
VAL_ 1600 hallCurrentOffset_SC01 65535 "SNA" ;
VAL_ 1600 sumOfCurrentsFiltered_SC01 65535 "SNA" ;
VAL_ 1600 hallCurrentAveraged_SC01 65535 "SNA" ;
VAL_ 1600 analogHallSupply_SC01 65535 "SNA" ;
VAL_ 1600 contactorControlPos1_SC01 4 "CTRCTRL_CTRFAIL" 3 "CTRCTRL_CTRON" 2 "CTRCTRL_CTRCHECK" 1 "CTRCTRL_ADDITIONAL_CTRCHECK" 0 "CTRCTRL_CTROFF" ;
VAL_ 1600 contactorControlNeg1_SC01 4 "CTRCTRL_CTRFAIL" 3 "CTRCTRL_CTRON" 2 "CTRCTRL_CTRCHECK" 1 "CTRCTRL_ADDITIONAL_CTRCHECK" 0 "CTRCTRL_CTROFF" ;
VAL_ 1600 contactorControlPre1_SC01 4 "CTRCTRL_CTRFAIL" 3 "CTRCTRL_CTRON" 2 "CTRCTRL_CTRCHECK" 1 "CTRCTRL_ADDITIONAL_CTRCHECK" 0 "CTRCTRL_CTROFF" ;
VAL_ 1600 contactorControlPos2_SC01 4 "CTRCTRL_CTRFAIL" 3 "CTRCTRL_CTRON" 2 "CTRCTRL_CTRCHECK" 1 "CTRCTRL_ADDITIONAL_CTRCHECK" 0 "CTRCTRL_CTROFF" ;
VAL_ 1600 contactorControlNeg2_SC01 4 "CTRCTRL_CTRFAIL" 3 "CTRCTRL_CTRON" 2 "CTRCTRL_CTRCHECK" 1 "CTRCTRL_ADDITIONAL_CTRCHECK" 0 "CTRCTRL_CTROFF" ;
VAL_ 1600 contactorControlPre2_SC01 4 "CTRCTRL_CTRFAIL" 3 "CTRCTRL_CTRON" 2 "CTRCTRL_CTRCHECK" 1 "CTRCTRL_ADDITIONAL_CTRCHECK" 0 "CTRCTRL_CTROFF" ;
VAL_ 1600 contactorControlPos3_SC01 4 "CTRCTRL_CTRFAIL" 3 "CTRCTRL_CTRON" 2 "CTRCTRL_CTRCHECK" 1 "CTRCTRL_ADDITIONAL_CTRCHECK" 0 "CTRCTRL_CTROFF" ;
VAL_ 1600 contactorControlNeg3_SC01 4 "CTRCTRL_CTRFAIL" 3 "CTRCTRL_CTRON" 2 "CTRCTRL_CTRCHECK" 1 "CTRCTRL_ADDITIONAL_CTRCHECK" 0 "CTRCTRL_CTROFF" ;
VAL_ 1664 selfTestFaultCntrCtrl_SC01 4 "CTRCTRL_SELFTEST_NONE" 3 "CTRCTRL_SELFTEST_4" 2 "CTRCTRL_SELFTEST_3" 1 "CTRCTRL_SELFTEST_2" 0 "CTRCTRL_SELFTEST_1" ;
VAL_ 1664 cmbASICFault_SC01 16 "CMBDRIVER_ASIC_REDUNDANT_FILTER" 15 "CMBDRIVER_ASIC_REDUNDANT_ADC" 14 "CMB_ASIC_CLOCK_LF" 13 "CMB_ASIC_CHARGE_PUMP_LF" 12 "CMB_ASIC_MUX_CHECK_LF" 11 "CMB_ASIC_INTERNAL_SUP_LF" 10 "CMB_ASIC_MUX_COMP_FAIL" 9 "CMB_ASIC_CHARGE_PUMP_FAIL" 8 "CMB_ASIC_OPEN_WIRE_CURR_FAIL" 255 "CMB_ASIC_FAULT_NONE" 7 "CMB_ASIC_VREF3_FAIL" 6 "CMB_ASIC_VREF2_FAIL" 5 "CMB_ASIC_ITEMP_FAIL" 4 "CMB_ASIC_VD_FAIL" 3 "CMB_ASIC_VA_FAIL" 2 "CMB_ASIC_TESTMODE" 1 "CMB_ASIC_CLOCK_FAIL" 0 "CMB_ASIC_MUX_FAIL" ;
VAL_ 1664 mainUcExtIsoResistance_SC01 65535 "SNA" ;
VAL_ 1664 BMS_C38_AR2MsgFault_SC01 3 "MSG_MISSING" 2 "MSG_SEQ_CNT_FAULT" 1 "MSG_CRC_FAULT" 0 "MSG_VALID" ;
VAL_ 1664 stateCoolant_SC01 1 "SAFESTATE_UNSAFE" 0 "SAFESTATE_SAFE" ;
VAL_ 1664 stateThermalEvent_SC01 1 "SAFESTATE_UNSAFE" 0 "SAFESTATE_SAFE" ;
VAL_ 1664 stateCANTx_SC01 1 "SAFESTATE_UNSAFE" 0 "SAFESTATE_SAFE" ;
VAL_ 1664 mainUcCntrCtrlReq_SC01 3 "SAFETYCAN_CNTR_CTRL_SNA" 1 "SAFETYCAN_CNTR_CTRL_CLS" 0 "SAFETYCAN_CNTR_CTRL_OPEN" ;
VAL_ 1664 mainUcCntrWeldState_SC01 7 "SAFETYCAN_WELD_HV_ALL_ERR" 6 "SAFETYCAN_WELD_HV_PLUS_MINUS_ERR" 15 "SAFETYCAN_WELD_SNA" 5 "SAFETYCAN_WELD_PRE_HV_MINUS_ERR" 4 "SAFETYCAN_WELD_HV_MINUS_ERR" 3 "SAFETYCAN_WELD_PRE_HV_PLUS_ERR" 2 "SAFETYCAN_WELD_HV_PLUS_ERR" 1 "SAFETYCAN_WELD_PRE_ERR" 0 "SAFETYCAN_WELD_NO_ERR" ;
VAL_ 1664 safetyUcCntrState_SC01 2 "SAFETYCAN_CNTR_CLS" 3 "SAFETYCAN_CNTR_SNA" 1 "SAFETYCAN_CNTR_PRECHRG" 0 "SAFETYCAN_CNTR_OPEN" ;
VAL_ 1664 mainUcCntrState_SC01 2 "SAFETYCAN_CNTR_CLS" 3 "SAFETYCAN_CNTR_SNA" 1 "SAFETYCAN_CNTR_PRECHRG" 0 "SAFETYCAN_CNTR_OPEN" ;
VAL_ 1664 safetyCANMsg4Fault_SC01 6 "SAFETYCAN_E2E_CRC" 15 "SAFETYCAN_SNA" 5 "SAFETYCAN_SPI_FAIL" 4 "SAFETYCAN_MSG_MISSING" 3 "SAFETYCAN_MSG_CNT_MISMATCH" 2 "SAFETYCAN_ALIVE_CNT" 1 "SAFETYCAN_SPI_CRC" 0 "SAFETYCAN_GOOD" ;
VAL_ 1664 safetyCANMsg3Fault_SC01 6 "SAFETYCAN_E2E_CRC" 15 "SAFETYCAN_SNA" 5 "SAFETYCAN_SPI_FAIL" 4 "SAFETYCAN_MSG_MISSING" 3 "SAFETYCAN_MSG_CNT_MISMATCH" 2 "SAFETYCAN_ALIVE_CNT" 1 "SAFETYCAN_SPI_CRC" 0 "SAFETYCAN_GOOD" ;
VAL_ 1664 safetyCANMsg2Fault_SC01 6 "SAFETYCAN_E2E_CRC" 15 "SAFETYCAN_SNA" 5 "SAFETYCAN_SPI_FAIL" 4 "SAFETYCAN_MSG_MISSING" 3 "SAFETYCAN_MSG_CNT_MISMATCH" 2 "SAFETYCAN_ALIVE_CNT" 1 "SAFETYCAN_SPI_CRC" 0 "SAFETYCAN_GOOD" ;
VAL_ 1664 safetyCANMsg1Fault_SC01 6 "SAFETYCAN_E2E_CRC" 15 "SAFETYCAN_SNA" 5 "SAFETYCAN_SPI_FAIL" 4 "SAFETYCAN_MSG_MISSING" 3 "SAFETYCAN_MSG_CNT_MISMATCH" 2 "SAFETYCAN_ALIVE_CNT" 1 "SAFETYCAN_SPI_CRC" 0 "SAFETYCAN_GOOD" ;
VAL_ 1664 contactorCntrSelfTest_SC01 9 "CTRCTRL_CHKLOSIDE_OPEN_CIRC" 8 "CTRCTRL_FAILED" 7 "CTRCTRL_PASSED" 6 "CTRCTRL_CHKHISIDE_STUCK_OPEN" 5 "CTRCTRL_CHK_CLOSE_OK_CIRCUIT" 4 "CTRCTRL_CHKLOSIDE_CTRL_OK" 3 "CTRCTRL_CHKLOSIDE_STUCK_CLOSED" 2 "CTRCTRL_CHKHISIDE_STUCK_CLOSED" 1 "CTRCTRL_PENDING" 0 "CTRCTRL_INIT" ;
VAL_ 1664 maxBrickVoltage_SC01 65535 "SNA" ;
VAL_ 1664 minBrickVoltage_SC01 65535 "SNA" ;
VAL_ 1664 cmbLastUpdateTime_SC01 255 "SNA" ;
VAL_ 1664 weldCheckState_SC01 4 "WELDCHECK_IDLE" 3 "WELDCHECK" 2 "WELDCHECK_ISO_2" 1 "WELDCHECK_ISO_1" 0 "WELDCHECK_INIT" ;
VAL_ 1664 debugFastMpex_SC01 0 "F00" 1 "F01" 2 "F02" 3 "F03" 4 "F04" 5 "F05" 6 "F06" 7 "F07" 8 "F08" 9 "F09" 10 "F10" 11 "F11" 12 "F12" 13 "F13" 14 "F14" 15 "F15" ;
VAL_ 1664 SPIRxTxTimeAllPckts_SC01 255 "SNA" ;
VAL_ 1664 stateContactorControl_SC01 1 "SAFESTATE_UNSAFE" 0 "SAFESTATE_SAFE" ;
VAL_ 1664 analogCntrPwrPlus_SC01 255 "SNA" ;
VAL_ 1664 weldedState_SC01 0 "CTR_NOTWELDED" 1 "CTR_ATLEASTONE_WELDED" ;
VAL_ 1664 stateVoltage_SC01 1 "SAFESTATE_UNSAFE" 0 "SAFESTATE_SAFE" ;
VAL_ 1664 stateTemperature_SC01 1 "SAFESTATE_UNSAFE" 0 "SAFESTATE_SAFE" ;
VAL_ 1664 stateSelfTest_SC01 1 "SAFESTATE_UNSAFE" 0 "SAFESTATE_SAFE" ;
VAL_ 1664 stateHVIL_SC01 1 "SAFESTATE_UNSAFE" 0 "SAFESTATE_SAFE" ;
VAL_ 1664 stateCurrent_SC01 1 "SAFESTATE_UNSAFE" 0 "SAFESTATE_SAFE" ;
VAL_ 1664 stateCrash2_SC01 1 "SAFESTATE_UNSAFE" 0 "SAFESTATE_SAFE" ;
VAL_ 1664 stateCrash1_SC01 1 "SAFESTATE_UNSAFE" 0 "SAFESTATE_SAFE" ;
VAL_ 1664 stateContactors_SC01 1 "SAFESTATE_UNSAFE" 0 "SAFESTATE_SAFE" ;
VAL_ 1664 stateCANRx_SC01 1 "SAFESTATE_UNSAFE" 0 "SAFESTATE_SAFE" ;
VAL_ 1664 itemState_SC01 15 "ITEM_INVALID" 2 "ITEM_EMERGENCY" 1 "ITEM_OFF" 0 "ITEM_ON" ;
VAL_ 1664 posPack_SC01 65535 "SNA" ;
VAL_ 1664 posLink_SC01 65535 "SNA" ;
VAL_ 1664 negPack_SC01 65535 "SNA" ;
VAL_ 1664 negLink_SC01 65535 "SNA" ;
VAL_ 1664 hallCurrent_SC01 4095 "SNA" ;
VAL_ 1664 analogCntrPwrPlusISense_SC01 255 "SNA" ;
VAL_ 1664 analogCntrPwrPlusSwitched_SC01 255 "SNA" ;
VAL_ 1920 cmbOnboardPressure32_BMS01 65535 "SNA" ;
VAL_ 1920 cmbOnboardPressure31_BMS01 65535 "SNA" ;
VAL_ 1920 cmbOnboardPressure30_BMS01 65535 "SNA" ;
VAL_ 1920 cmbOnboardPressure29_BMS01 65535 "SNA" ;
VAL_ 1920 cmbOnboardPressure28_BMS01 65535 "SNA" ;
VAL_ 1920 cmbOnboardPressure27_BMS01 65535 "SNA" ;
VAL_ 1920 cmbOnboardPressure26_BMS01 65535 "SNA" ;
VAL_ 1920 cmbOnboardPressure25_BMS01 65535 "SNA" ;
VAL_ 1920 cmbOnboardPressure24_BMS01 65535 "SNA" ;
VAL_ 1920 cmbOnboardPressure23_BMS01 65535 "SNA" ;
VAL_ 1920 cmbOnboardPressure22_BMS01 65535 "SNA" ;
VAL_ 1920 cmbOnboardPressure21_BMS01 65535 "SNA" ;
VAL_ 1920 cmbOnboardPressure20_BMS01 65535 "SNA" ;
VAL_ 1920 cmbOnboardPressure19_BMS01 65535 "SNA" ;
VAL_ 1920 cmbOnboardPressure18_BMS01 65535 "SNA" ;
VAL_ 1920 cmbOnboardPressure17_BMS01 65535 "SNA" ;
VAL_ 1920 cmbOnboardPressure16_BMS01 65535 "SNA" ;
VAL_ 1920 cmbOnboardPressure15_BMS01 65535 "SNA" ;
VAL_ 1920 cmbOnboardPressure14_BMS01 65535 "SNA" ;
VAL_ 1920 cmbOnboardPressure13_BMS01 65535 "SNA" ;
VAL_ 1920 cmbOnboardPressure12_BMS01 65535 "SNA" ;
VAL_ 1920 cmbOnboardPressure11_BMS01 65535 "SNA" ;
VAL_ 1920 cmbOnboardPressure10_BMS01 65535 "SNA" ;
VAL_ 1920 cmbOnboardPressure09_BMS01 65535 "SNA" ;
VAL_ 1920 cmbOnboardPressure08_BMS01 65535 "SNA" ;
VAL_ 1920 cmbOnboardPressure07_BMS01 65535 "SNA" ;
VAL_ 1920 cmbOnboardPressure06_BMS01 65535 "SNA" ;
VAL_ 1920 cmbOnboardPressure05_BMS01 65535 "SNA" ;
VAL_ 1920 cmbOnboardPressure04_BMS01 65535 "SNA" ;
VAL_ 1920 cmbOnboardPressure03_BMS01 65535 "SNA" ;
VAL_ 1920 cmbOnboardPressure02_BMS01 65535 "SNA" ;
VAL_ 1920 cmbOnboardPressure01_BMS01 65535 "SNA" ;
VAL_ 1920 onboardMultiplexor_BMS01 32 "O32" 31 "O31" 30 "O30" 29 "O29" 28 "O28" 27 "O27" 26 "O26" 25 "O25" 24 "O24" 23 "O23" 22 "O22" 21 "O21" 20 "O20" 19 "O19" 18 "O18" 17 "O17" 16 "O16" 15 "O15" 14 "O14" 13 "O13" 0 "O00" 1 "O01" 2 "O02" 3 "O03" 4 "O04" 5 "O05" 6 "O06" 7 "O07" 8 "O08" 9 "O09" 10 "O10" 11 "O11" 12 "O12" ;
VAL_ 1920 minCmbOnboardTemperature_BMS01 255 "SNA" ;
VAL_ 1920 minCmbOnboardHumidity_BMS01 255 "SNA" ;
VAL_ 1920 maxCmbOnboardTemperature_BMS01 255 "SNA" ;
VAL_ 1920 maxCmbOnboardHumidity_BMS01 255 "SNA" ;
VAL_ 1920 bmsOnboardTemperature_BMS01 255 "SNA" ;
VAL_ 1920 bmsOnboardHumidity_BMS01 255 "SNA" ;
VAL_ 1920 cmbOnboardTemperature01_BMS01 255 "SNA" ;
VAL_ 1920 cmbOnboardHumidity01_BMS01 255 "SNA" ;
VAL_ 1920 moduleHeaterCurrent01_BMS01 255 "SNA" ;
VAL_ 1920 cmbOnboardTemperature02_BMS01 255 "SNA" ;
VAL_ 1920 cmbOnboardHumidity02_BMS01 255 "SNA" ;
VAL_ 1920 moduleHeaterCurrent02_BMS01 255 "SNA" ;
VAL_ 1920 cmbOnboardTemperature03_BMS01 255 "SNA" ;
VAL_ 1920 cmbOnboardHumidity03_BMS01 255 "SNA" ;
VAL_ 1920 moduleHeaterCurrent03_BMS01 255 "SNA" ;
VAL_ 1920 cmbOnboardTemperature04_BMS01 255 "SNA" ;
VAL_ 1920 cmbOnboardHumidity04_BMS01 255 "SNA" ;
VAL_ 1920 moduleHeaterCurrent04_BMS01 255 "SNA" ;
VAL_ 1920 cmbOnboardTemperature05_BMS01 255 "SNA" ;
VAL_ 1920 cmbOnboardHumidity05_BMS01 255 "SNA" ;
VAL_ 1920 moduleHeaterCurrent05_BMS01 255 "SNA" ;
VAL_ 1920 cmbOnboardTemperature06_BMS01 255 "SNA" ;
VAL_ 1920 cmbOnboardHumidity06_BMS01 255 "SNA" ;
VAL_ 1920 moduleHeaterCurrent06_BMS01 255 "SNA" ;
VAL_ 1920 cmbOnboardTemperature07_BMS01 255 "SNA" ;
VAL_ 1920 cmbOnboardHumidity07_BMS01 255 "SNA" ;
VAL_ 1920 moduleHeaterCurrent07_BMS01 255 "SNA" ;
VAL_ 1920 cmbOnboardTemperature08_BMS01 255 "SNA" ;
VAL_ 1920 cmbOnboardHumidity08_BMS01 255 "SNA" ;
VAL_ 1920 moduleHeaterCurrent08_BMS01 255 "SNA" ;
VAL_ 1920 cmbOnboardTemperature09_BMS01 255 "SNA" ;
VAL_ 1920 cmbOnboardHumidity09_BMS01 255 "SNA" ;
VAL_ 1920 moduleHeaterCurrent09_BMS01 255 "SNA" ;
VAL_ 1920 cmbOnboardTemperature10_BMS01 255 "SNA" ;
VAL_ 1920 cmbOnboardHumidity10_BMS01 255 "SNA" ;
VAL_ 1920 moduleHeaterCurrent10_BMS01 255 "SNA" ;
VAL_ 1920 cmbOnboardTemperature11_BMS01 255 "SNA" ;
VAL_ 1920 cmbOnboardHumidity11_BMS01 255 "SNA" ;
VAL_ 1920 moduleHeaterCurrent11_BMS01 255 "SNA" ;
VAL_ 1920 cmbOnboardTemperature12_BMS01 255 "SNA" ;
VAL_ 1920 cmbOnboardHumidity12_BMS01 255 "SNA" ;
VAL_ 1920 moduleHeaterCurrent12_BMS01 255 "SNA" ;
VAL_ 1920 cmbOnboardTemperature13_BMS01 255 "SNA" ;
VAL_ 1920 cmbOnboardHumidity13_BMS01 255 "SNA" ;
VAL_ 1920 moduleHeaterCurrent13_BMS01 255 "SNA" ;
VAL_ 1920 cmbOnboardTemperature14_BMS01 255 "SNA" ;
VAL_ 1920 cmbOnboardHumidity14_BMS01 255 "SNA" ;
VAL_ 1920 moduleHeaterCurrent14_BMS01 255 "SNA" ;
VAL_ 1920 cmbOnboardTemperature15_BMS01 255 "SNA" ;
VAL_ 1920 cmbOnboardHumidity15_BMS01 255 "SNA" ;
VAL_ 1920 moduleHeaterCurrent15_BMS01 255 "SNA" ;
VAL_ 1920 cmbOnboardTemperature16_BMS01 255 "SNA" ;
VAL_ 1920 cmbOnboardHumidity16_BMS01 255 "SNA" ;
VAL_ 1920 moduleHeaterCurrent16_BMS01 255 "SNA" ;
VAL_ 1920 cmbOnboardTemperature17_BMS01 255 "SNA" ;
VAL_ 1920 cmbOnboardHumidity17_BMS01 255 "SNA" ;
VAL_ 1920 moduleHeaterCurrent17_BMS01 255 "SNA" ;
VAL_ 1920 cmbOnboardTemperature18_BMS01 255 "SNA" ;
VAL_ 1920 cmbOnboardHumidity18_BMS01 255 "SNA" ;
VAL_ 1920 moduleHeaterCurrent18_BMS01 255 "SNA" ;
VAL_ 1920 cmbOnboardTemperature19_BMS01 255 "SNA" ;
VAL_ 1920 cmbOnboardHumidity19_BMS01 255 "SNA" ;
VAL_ 1920 moduleHeaterCurrent19_BMS01 255 "SNA" ;
VAL_ 1920 cmbOnboardTemperature20_BMS01 255 "SNA" ;
VAL_ 1920 cmbOnboardHumidity20_BMS01 255 "SNA" ;
VAL_ 1920 moduleHeaterCurrent20_BMS01 255 "SNA" ;
VAL_ 1920 cmbOnboardTemperature21_BMS01 255 "SNA" ;
VAL_ 1920 cmbOnboardHumidity21_BMS01 255 "SNA" ;
VAL_ 1920 moduleHeaterCurrent21_BMS01 255 "SNA" ;
VAL_ 1920 cmbOnboardTemperature22_BMS01 255 "SNA" ;
VAL_ 1920 cmbOnboardHumidity22_BMS01 255 "SNA" ;
VAL_ 1920 moduleHeaterCurrent22_BMS01 255 "SNA" ;
VAL_ 1920 cmbOnboardTemperature23_BMS01 255 "SNA" ;
VAL_ 1920 cmbOnboardHumidity23_BMS01 255 "SNA" ;
VAL_ 1920 moduleHeaterCurrent23_BMS01 255 "SNA" ;
VAL_ 1920 cmbOnboardTemperature24_BMS01 255 "SNA" ;
VAL_ 1920 cmbOnboardHumidity24_BMS01 255 "SNA" ;
VAL_ 1920 moduleHeaterCurrent24_BMS01 255 "SNA" ;
VAL_ 1920 cmbOnboardTemperature25_BMS01 255 "SNA" ;
VAL_ 1920 cmbOnboardHumidity25_BMS01 255 "SNA" ;
VAL_ 1920 moduleHeaterCurrent25_BMS01 255 "SNA" ;
VAL_ 1920 cmbOnboardTemperature26_BMS01 255 "SNA" ;
VAL_ 1920 cmbOnboardHumidity26_BMS01 255 "SNA" ;
VAL_ 1920 moduleHeaterCurrent26_BMS01 255 "SNA" ;
VAL_ 1920 cmbOnboardTemperature27_BMS01 255 "SNA" ;
VAL_ 1920 cmbOnboardHumidity27_BMS01 255 "SNA" ;
VAL_ 1920 moduleHeaterCurrent27_BMS01 255 "SNA" ;
VAL_ 1920 cmbOnboardTemperature28_BMS01 255 "SNA" ;
VAL_ 1920 cmbOnboardHumidity28_BMS01 255 "SNA" ;
VAL_ 1920 moduleHeaterCurrent28_BMS01 255 "SNA" ;
VAL_ 1920 cmbOnboardTemperature29_BMS01 255 "SNA" ;
VAL_ 1920 cmbOnboardHumidity29_BMS01 255 "SNA" ;
VAL_ 1920 moduleHeaterCurrent29_BMS01 255 "SNA" ;
VAL_ 1920 cmbOnboardTemperature30_BMS01 255 "SNA" ;
VAL_ 1920 cmbOnboardHumidity30_BMS01 255 "SNA" ;
VAL_ 1920 moduleHeaterCurrent30_BMS01 255 "SNA" ;
VAL_ 1920 cmbOnboardTemperature31_BMS01 255 "SNA" ;
VAL_ 1920 cmbOnboardHumidity31_BMS01 255 "SNA" ;
VAL_ 1920 moduleHeaterCurrent31_BMS01 255 "SNA" ;
VAL_ 1920 cmbOnboardTemperature32_BMS01 255 "SNA" ;
VAL_ 1920 cmbOnboardHumidity32_BMS01 255 "SNA" ;
VAL_ 1920 moduleHeaterCurrent32_BMS01 255 "SNA" ;
VAL_ 1984 cmbMultiplexor_BMS01 0 "C000" 1 "C001" 2 "C002" 3 "C003" 4 "C004" 5 "C005" 6 "C006" 7 "C007" 8 "C008" 9 "C009" 10 "C010" 11 "C011" 12 "C012" 13 "C013" 14 "C014" 15 "C015" 16 "C016" 17 "C017" 18 "C018" 19 "C019" 20 "C020" 21 "C021" 22 "C022" 23 "C023" 24 "C024" 25 "C025" 26 "C026" 27 "C027" 28 "C028" 29 "C029" 30 "C030" 31 "C031" 32 "C032" 33 "C033" 34 "C034" 35 "C035" 36 "C036" 37 "C037" 38 "C038" 39 "C039" 40 "C040" 41 "C041" 42 "C042" 43 "C043" 44 "C044" 45 "C045" 46 "C046" 47 "C047" 48 "C048" 49 "C049" 50 "C050" 51 "C051" 52 "C052" 53 "C053" 54 "C054" 55 "C055" 56 "C056" 57 "C057" 58 "C058" 59 "C059" 60 "C060" 61 "C061" 62 "C062" 63 "C063" 64 "C064" 65 "C065" 66 "C066" 67 "C067" 68 "C068" 69 "C069" 70 "C070" 71 "C071" 72 "C072" 73 "C073" 74 "C074" 75 "C075" 76 "C076" 77 "C077" 78 "C078" 79 "C079" 80 "C080" 81 "C081" 82 "C082" 83 "C083" 84 "C084" 85 "C085" 86 "C086" 87 "C087" 88 "C088" 89 "C089" 90 "C090" 91 "C091" 92 "C092" 93 "C093" 94 "C094" 95 "C095" 96 "C096" 97 "C097" 98 "C098" 99 "C099" 100 "C100" 101 "C101" 102 "C102" 103 "C103" 104 "C104" 105 "C105" 106 "C106" 107 "C107" 108 "C108" 109 "C109" 110 "C110" 111 "C111" 112 "C112" 113 "C113" 114 "C114" 115 "C115" 116 "C116" 117 "C117" 118 "C118" 119 "C119" 120 "C120" 121 "C121" 122 "C122" 123 "C123" 124 "C124" 125 "C125" 126 "C126" 127 "C127" 128 "C128" 129 "C129" 130 "C130" 131 "C131" 132 "C132" 133 "C133" 134 "C134" 135 "C135" 136 "C136" 137 "C137" 138 "C138" 139 "C139" 140 "C140" 141 "C141" 142 "C142" 143 "C143" 144 "C144" 145 "C145" 146 "C146" 147 "C147" 148 "C148" 149 "C149" 150 "C150" 151 "C151" 152 "C152" 153 "C153" 154 "C154" 155 "C155" 156 "C156" 157 "C157" 158 "C158" 159 "C159" 160 "C160" 161 "C161" 162 "C162" 163 "C163" 164 "C164" 165 "C165" 166 "C166" 167 "C167" 168 "C168" 169 "C169" 170 "C170" 171 "C171" 172 "C172" 173 "C173" 174 "C174" 175 "C175" 176 "C176" 177 "C177" 178 "C178" 179 "C179" 180 "C180" 181 "C181" 182 "C182" 183 "C183" 184 "C184" 185 "C185" 186 "C186" 187 "C187" 188 "C188" 189 "C189" 190 "C190" 191 "C191" 192 "C192" ;
VAL_ 1984 moduleTemperature01_BMS01 255 "SNA" ;
VAL_ 1984 brickVoltage001_BMS01 65535 "SNA" ;
VAL_ 1984 brickVoltage002_BMS01 65535 "SNA" ;
VAL_ 1984 brickVoltage003_BMS01 65535 "SNA" ;
VAL_ 1984 moduleTemperature02_BMS01 255 "SNA" ;
VAL_ 1984 brickVoltage004_BMS01 65535 "SNA" ;
VAL_ 1984 brickVoltage005_BMS01 65535 "SNA" ;
VAL_ 1984 brickVoltage006_BMS01 65535 "SNA" ;
VAL_ 1984 moduleTemperature03_BMS01 255 "SNA" ;
VAL_ 1984 brickVoltage007_BMS01 65535 "SNA" ;
VAL_ 1984 brickVoltage008_BMS01 65535 "SNA" ;
VAL_ 1984 brickVoltage009_BMS01 65535 "SNA" ;
VAL_ 1984 moduleTemperature04_BMS01 255 "SNA" ;
VAL_ 1984 brickVoltage010_BMS01 65535 "SNA" ;
VAL_ 1984 brickVoltage011_BMS01 65535 "SNA" ;
VAL_ 1984 brickVoltage012_BMS01 65535 "SNA" ;
VAL_ 1984 moduleTemperature05_BMS01 255 "SNA" ;
VAL_ 1984 brickVoltage013_BMS01 65535 "SNA" ;
VAL_ 1984 brickVoltage014_BMS01 65535 "SNA" ;
VAL_ 1984 brickVoltage015_BMS01 65535 "SNA" ;
VAL_ 1984 moduleTemperature06_BMS01 255 "SNA" ;
VAL_ 1984 brickVoltage016_BMS01 65535 "SNA" ;
VAL_ 1984 brickVoltage017_BMS01 65535 "SNA" ;
VAL_ 1984 brickVoltage018_BMS01 65535 "SNA" ;
VAL_ 1984 moduleTemperature07_BMS01 255 "SNA" ;
VAL_ 1984 brickVoltage019_BMS01 65535 "SNA" ;
VAL_ 1984 brickVoltage020_BMS01 65535 "SNA" ;
VAL_ 1984 brickVoltage021_BMS01 65535 "SNA" ;
VAL_ 1984 moduleTemperature08_BMS01 255 "SNA" ;
VAL_ 1984 brickVoltage022_BMS01 65535 "SNA" ;
VAL_ 1984 brickVoltage023_BMS01 65535 "SNA" ;
VAL_ 1984 brickVoltage024_BMS01 65535 "SNA" ;
VAL_ 1984 moduleTemperature09_BMS01 255 "SNA" ;
VAL_ 1984 brickVoltage025_BMS01 65535 "SNA" ;
VAL_ 1984 brickVoltage026_BMS01 65535 "SNA" ;
VAL_ 1984 brickVoltage027_BMS01 65535 "SNA" ;
VAL_ 1984 moduleTemperature10_BMS01 255 "SNA" ;
VAL_ 1984 brickVoltage028_BMS01 65535 "SNA" ;
VAL_ 1984 brickVoltage029_BMS01 65535 "SNA" ;
VAL_ 1984 brickVoltage030_BMS01 65535 "SNA" ;
VAL_ 1984 moduleTemperature11_BMS01 255 "SNA" ;
VAL_ 1984 brickVoltage031_BMS01 65535 "SNA" ;
VAL_ 1984 brickVoltage032_BMS01 65535 "SNA" ;
VAL_ 1984 brickVoltage033_BMS01 65535 "SNA" ;
VAL_ 1984 moduleTemperature12_BMS01 255 "SNA" ;
VAL_ 1984 brickVoltage034_BMS01 65535 "SNA" ;
VAL_ 1984 brickVoltage035_BMS01 65535 "SNA" ;
VAL_ 1984 brickVoltage036_BMS01 65535 "SNA" ;
VAL_ 1984 moduleTemperature13_BMS01 255 "SNA" ;
VAL_ 1984 brickVoltage037_BMS01 65535 "SNA" ;
VAL_ 1984 brickVoltage038_BMS01 65535 "SNA" ;
VAL_ 1984 brickVoltage039_BMS01 65535 "SNA" ;
VAL_ 1984 moduleTemperature14_BMS01 255 "SNA" ;
VAL_ 1984 brickVoltage040_BMS01 65535 "SNA" ;
VAL_ 1984 brickVoltage041_BMS01 65535 "SNA" ;
VAL_ 1984 brickVoltage042_BMS01 65535 "SNA" ;
VAL_ 1984 moduleTemperature15_BMS01 255 "SNA" ;
VAL_ 1984 brickVoltage043_BMS01 65535 "SNA" ;
VAL_ 1984 brickVoltage044_BMS01 65535 "SNA" ;
VAL_ 1984 brickVoltage045_BMS01 65535 "SNA" ;
VAL_ 1984 moduleTemperature16_BMS01 255 "SNA" ;
VAL_ 1984 brickVoltage046_BMS01 65535 "SNA" ;
VAL_ 1984 brickVoltage047_BMS01 65535 "SNA" ;
VAL_ 1984 brickVoltage048_BMS01 65535 "SNA" ;
VAL_ 1984 moduleTemperature17_BMS01 255 "SNA" ;
VAL_ 1984 brickVoltage049_BMS01 65535 "SNA" ;
VAL_ 1984 brickVoltage050_BMS01 65535 "SNA" ;
VAL_ 1984 brickVoltage051_BMS01 65535 "SNA" ;
VAL_ 1984 moduleTemperature18_BMS01 255 "SNA" ;
VAL_ 1984 brickVoltage052_BMS01 65535 "SNA" ;
VAL_ 1984 brickVoltage053_BMS01 65535 "SNA" ;
VAL_ 1984 brickVoltage054_BMS01 65535 "SNA" ;
VAL_ 1984 moduleTemperature19_BMS01 255 "SNA" ;
VAL_ 1984 brickVoltage055_BMS01 65535 "SNA" ;
VAL_ 1984 brickVoltage056_BMS01 65535 "SNA" ;
VAL_ 1984 brickVoltage057_BMS01 65535 "SNA" ;
VAL_ 1984 moduleTemperature20_BMS01 255 "SNA" ;
VAL_ 1984 brickVoltage058_BMS01 65535 "SNA" ;
VAL_ 1984 brickVoltage059_BMS01 65535 "SNA" ;
VAL_ 1984 brickVoltage060_BMS01 65535 "SNA" ;
VAL_ 1984 moduleTemperature21_BMS01 255 "SNA" ;
VAL_ 1984 brickVoltage061_BMS01 65535 "SNA" ;
VAL_ 1984 brickVoltage062_BMS01 65535 "SNA" ;
VAL_ 1984 brickVoltage063_BMS01 65535 "SNA" ;
VAL_ 1984 moduleTemperature22_BMS01 255 "SNA" ;
VAL_ 1984 brickVoltage064_BMS01 65535 "SNA" ;
VAL_ 1984 brickVoltage065_BMS01 65535 "SNA" ;
VAL_ 1984 brickVoltage066_BMS01 65535 "SNA" ;
VAL_ 1984 moduleTemperature23_BMS01 255 "SNA" ;
VAL_ 1984 brickVoltage067_BMS01 65535 "SNA" ;
VAL_ 1984 brickVoltage068_BMS01 65535 "SNA" ;
VAL_ 1984 brickVoltage069_BMS01 65535 "SNA" ;
VAL_ 1984 moduleTemperature24_BMS01 255 "SNA" ;
VAL_ 1984 brickVoltage070_BMS01 65535 "SNA" ;
VAL_ 1984 brickVoltage071_BMS01 65535 "SNA" ;
VAL_ 1984 brickVoltage072_BMS01 65535 "SNA" ;
VAL_ 1984 moduleTemperature25_BMS01 255 "SNA" ;
VAL_ 1984 brickVoltage073_BMS01 65535 "SNA" ;
VAL_ 1984 brickVoltage074_BMS01 65535 "SNA" ;
VAL_ 1984 brickVoltage075_BMS01 65535 "SNA" ;
VAL_ 1984 moduleTemperature26_BMS01 255 "SNA" ;
VAL_ 1984 brickVoltage076_BMS01 65535 "SNA" ;
VAL_ 1984 brickVoltage077_BMS01 65535 "SNA" ;
VAL_ 1984 brickVoltage078_BMS01 65535 "SNA" ;
VAL_ 1984 moduleTemperature27_BMS01 255 "SNA" ;
VAL_ 1984 brickVoltage079_BMS01 65535 "SNA" ;
VAL_ 1984 brickVoltage080_BMS01 65535 "SNA" ;
VAL_ 1984 brickVoltage081_BMS01 65535 "SNA" ;
VAL_ 1984 moduleTemperature28_BMS01 255 "SNA" ;
VAL_ 1984 brickVoltage082_BMS01 65535 "SNA" ;
VAL_ 1984 brickVoltage083_BMS01 65535 "SNA" ;
VAL_ 1984 brickVoltage084_BMS01 65535 "SNA" ;
VAL_ 1984 moduleTemperature29_BMS01 255 "SNA" ;
VAL_ 1984 brickVoltage085_BMS01 65535 "SNA" ;
VAL_ 1984 brickVoltage086_BMS01 65535 "SNA" ;
VAL_ 1984 brickVoltage087_BMS01 65535 "SNA" ;
VAL_ 1984 moduleTemperature30_BMS01 255 "SNA" ;
VAL_ 1984 brickVoltage088_BMS01 65535 "SNA" ;
VAL_ 1984 brickVoltage089_BMS01 65535 "SNA" ;
VAL_ 1984 brickVoltage090_BMS01 65535 "SNA" ;
VAL_ 1984 moduleTemperature31_BMS01 255 "SNA" ;
VAL_ 1984 brickVoltage091_BMS01 65535 "SNA" ;
VAL_ 1984 brickVoltage092_BMS01 65535 "SNA" ;
VAL_ 1984 brickVoltage093_BMS01 65535 "SNA" ;
VAL_ 1984 moduleTemperature32_BMS01 255 "SNA" ;
VAL_ 1984 brickVoltage094_BMS01 65535 "SNA" ;
VAL_ 1984 brickVoltage095_BMS01 65535 "SNA" ;
VAL_ 1984 brickVoltage096_BMS01 65535 "SNA" ;
VAL_ 1984 brickVoltage097_BMS01 65535 "SNA" ;
VAL_ 1984 brickVoltage098_BMS01 65535 "SNA" ;
VAL_ 1984 brickVoltage099_BMS01 65535 "SNA" ;
VAL_ 1984 brickVoltage100_BMS01 65535 "SNA" ;
VAL_ 1984 brickVoltage101_BMS01 65535 "SNA" ;
VAL_ 1984 brickVoltage102_BMS01 65535 "SNA" ;
VAL_ 1984 brickVoltage103_BMS01 65535 "SNA" ;
VAL_ 1984 brickVoltage104_BMS01 65535 "SNA" ;
VAL_ 1984 brickVoltage105_BMS01 65535 "SNA" ;
VAL_ 1984 brickVoltage106_BMS01 65535 "SNA" ;
VAL_ 1984 brickVoltage107_BMS01 65535 "SNA" ;
VAL_ 1984 brickVoltage108_BMS01 65535 "SNA" ;
VAL_ 1984 brickVoltage109_BMS01 65535 "SNA" ;
VAL_ 1984 brickVoltage110_BMS01 65535 "SNA" ;
VAL_ 1984 brickVoltage111_BMS01 65535 "SNA" ;
VAL_ 1984 brickVoltage112_BMS01 65535 "SNA" ;
VAL_ 1984 brickVoltage113_BMS01 65535 "SNA" ;
VAL_ 1984 brickVoltage114_BMS01 65535 "SNA" ;
VAL_ 1984 brickVoltage115_BMS01 65535 "SNA" ;
VAL_ 1984 brickVoltage116_BMS01 65535 "SNA" ;
VAL_ 1984 brickVoltage117_BMS01 65535 "SNA" ;
VAL_ 1984 brickVoltage118_BMS01 65535 "SNA" ;
VAL_ 1984 brickVoltage119_BMS01 65535 "SNA" ;
VAL_ 1984 brickVoltage120_BMS01 65535 "SNA" ;
VAL_ 1984 brickVoltage121_BMS01 65535 "SNA" ;
VAL_ 1984 brickVoltage122_BMS01 65535 "SNA" ;
VAL_ 1984 brickVoltage123_BMS01 65535 "SNA" ;
VAL_ 1984 brickVoltage124_BMS01 65535 "SNA" ;
VAL_ 1984 brickVoltage125_BMS01 65535 "SNA" ;
VAL_ 1984 brickVoltage126_BMS01 65535 "SNA" ;
VAL_ 1984 brickVoltage127_BMS01 65535 "SNA" ;
VAL_ 1984 brickVoltage128_BMS01 65535 "SNA" ;
VAL_ 1984 brickVoltage129_BMS01 65535 "SNA" ;
VAL_ 1984 brickVoltage130_BMS01 65535 "SNA" ;
VAL_ 1984 brickVoltage131_BMS01 65535 "SNA" ;
VAL_ 1984 brickVoltage132_BMS01 65535 "SNA" ;
VAL_ 1984 brickVoltage133_BMS01 65535 "SNA" ;
VAL_ 1984 brickVoltage134_BMS01 65535 "SNA" ;
VAL_ 1984 brickVoltage135_BMS01 65535 "SNA" ;
VAL_ 1984 brickVoltage136_BMS01 65535 "SNA" ;
VAL_ 1984 brickVoltage137_BMS01 65535 "SNA" ;
VAL_ 1984 brickVoltage138_BMS01 65535 "SNA" ;
VAL_ 1984 brickVoltage139_BMS01 65535 "SNA" ;
VAL_ 1984 brickVoltage140_BMS01 65535 "SNA" ;
VAL_ 1984 brickVoltage141_BMS01 65535 "SNA" ;
VAL_ 1984 brickVoltage142_BMS01 65535 "SNA" ;
VAL_ 1984 brickVoltage143_BMS01 65535 "SNA" ;
VAL_ 1984 brickVoltage144_BMS01 65535 "SNA" ;
VAL_ 1984 brickVoltage145_BMS01 65535 "SNA" ;
VAL_ 1984 brickVoltage146_BMS01 65535 "SNA" ;
VAL_ 1984 brickVoltage147_BMS01 65535 "SNA" ;
VAL_ 1984 brickVoltage148_BMS01 65535 "SNA" ;
VAL_ 1984 brickVoltage149_BMS01 65535 "SNA" ;
VAL_ 1984 brickVoltage150_BMS01 65535 "SNA" ;
VAL_ 1984 brickVoltage151_BMS01 65535 "SNA" ;
VAL_ 1984 brickVoltage152_BMS01 65535 "SNA" ;
VAL_ 1984 brickVoltage153_BMS01 65535 "SNA" ;
VAL_ 1984 brickVoltage154_BMS01 65535 "SNA" ;
VAL_ 1984 brickVoltage155_BMS01 65535 "SNA" ;
VAL_ 1984 brickVoltage156_BMS01 65535 "SNA" ;
VAL_ 1984 brickVoltage157_BMS01 65535 "SNA" ;
VAL_ 1984 brickVoltage158_BMS01 65535 "SNA" ;
VAL_ 1984 brickVoltage159_BMS01 65535 "SNA" ;
VAL_ 1984 brickVoltage160_BMS01 65535 "SNA" ;
VAL_ 1984 brickVoltage161_BMS01 65535 "SNA" ;
VAL_ 1984 brickVoltage162_BMS01 65535 "SNA" ;
VAL_ 1984 brickVoltage163_BMS01 65535 "SNA" ;
VAL_ 1984 brickVoltage164_BMS01 65535 "SNA" ;
VAL_ 1984 brickVoltage165_BMS01 65535 "SNA" ;
VAL_ 1984 brickVoltage166_BMS01 65535 "SNA" ;
VAL_ 1984 brickVoltage167_BMS01 65535 "SNA" ;
VAL_ 1984 brickVoltage168_BMS01 65535 "SNA" ;
VAL_ 1984 brickVoltage169_BMS01 65535 "SNA" ;
VAL_ 1984 brickVoltage170_BMS01 65535 "SNA" ;
VAL_ 1984 brickVoltage171_BMS01 65535 "SNA" ;
VAL_ 1984 brickVoltage172_BMS01 65535 "SNA" ;
VAL_ 1984 brickVoltage173_BMS01 65535 "SNA" ;
VAL_ 1984 brickVoltage174_BMS01 65535 "SNA" ;
VAL_ 1984 brickVoltage175_BMS01 65535 "SNA" ;
VAL_ 1984 brickVoltage176_BMS01 65535 "SNA" ;
VAL_ 1984 brickVoltage177_BMS01 65535 "SNA" ;
VAL_ 1984 brickVoltage178_BMS01 65535 "SNA" ;
VAL_ 1984 brickVoltage179_BMS01 65535 "SNA" ;
VAL_ 1984 brickVoltage180_BMS01 65535 "SNA" ;
VAL_ 1984 brickVoltage181_BMS01 65535 "SNA" ;
VAL_ 1984 brickVoltage182_BMS01 65535 "SNA" ;
VAL_ 1984 brickVoltage183_BMS01 65535 "SNA" ;
VAL_ 1984 brickVoltage184_BMS01 65535 "SNA" ;
VAL_ 1984 brickVoltage185_BMS01 65535 "SNA" ;
VAL_ 1984 brickVoltage186_BMS01 65535 "SNA" ;
VAL_ 1984 brickVoltage187_BMS01 65535 "SNA" ;
VAL_ 1984 brickVoltage188_BMS01 65535 "SNA" ;
VAL_ 1984 brickVoltage189_BMS01 65535 "SNA" ;
VAL_ 1984 brickVoltage190_BMS01 65535 "SNA" ;
VAL_ 1984 brickVoltage191_BMS01 65535 "SNA" ;
VAL_ 1984 brickVoltage192_BMS01 65535 "SNA" ;
VAL_ 1984 brickVoltage193_BMS01 65535 "SNA" ;
VAL_ 1984 brickVoltage194_BMS01 65535 "SNA" ;
VAL_ 1984 brickVoltage195_BMS01 65535 "SNA" ;
VAL_ 1984 brickVoltage196_BMS01 65535 "SNA" ;
VAL_ 1984 brickVoltage197_BMS01 65535 "SNA" ;
VAL_ 1984 brickVoltage198_BMS01 65535 "SNA" ;
VAL_ 1984 brickVoltage199_BMS01 65535 "SNA" ;
VAL_ 1984 brickVoltage200_BMS01 65535 "SNA" ;
VAL_ 1984 brickVoltage201_BMS01 65535 "SNA" ;
VAL_ 1984 brickVoltage202_BMS01 65535 "SNA" ;
VAL_ 1984 brickVoltage203_BMS01 65535 "SNA" ;
VAL_ 1984 brickVoltage204_BMS01 65535 "SNA" ;
VAL_ 1984 brickVoltage205_BMS01 65535 "SNA" ;
VAL_ 1984 brickVoltage206_BMS01 65535 "SNA" ;
VAL_ 1984 brickVoltage207_BMS01 65535 "SNA" ;
VAL_ 1984 brickVoltage208_BMS01 65535 "SNA" ;
VAL_ 1984 brickVoltage209_BMS01 65535 "SNA" ;
VAL_ 1984 brickVoltage210_BMS01 65535 "SNA" ;
VAL_ 1984 brickVoltage211_BMS01 65535 "SNA" ;
VAL_ 1984 brickVoltage212_BMS01 65535 "SNA" ;
VAL_ 1984 brickVoltage213_BMS01 65535 "SNA" ;
VAL_ 1984 brickVoltage214_BMS01 65535 "SNA" ;
VAL_ 1984 brickVoltage215_BMS01 65535 "SNA" ;
VAL_ 1984 brickVoltage216_BMS01 65535 "SNA" ;
VAL_ 1984 brickVoltage217_BMS01 65535 "SNA" ;
VAL_ 1984 brickVoltage218_BMS01 65535 "SNA" ;
VAL_ 1984 brickVoltage219_BMS01 65535 "SNA" ;
VAL_ 1984 brickVoltage220_BMS01 65535 "SNA" ;
VAL_ 1984 brickVoltage221_BMS01 65535 "SNA" ;
VAL_ 1984 brickVoltage222_BMS01 65535 "SNA" ;
VAL_ 1984 brickVoltage223_BMS01 65535 "SNA" ;
VAL_ 1984 brickVoltage224_BMS01 65535 "SNA" ;
VAL_ 1984 brickVoltage225_BMS01 65535 "SNA" ;
VAL_ 1984 brickVoltage226_BMS01 65535 "SNA" ;
VAL_ 1984 brickVoltage227_BMS01 65535 "SNA" ;
VAL_ 1984 brickVoltage228_BMS01 65535 "SNA" ;
VAL_ 1984 brickVoltage229_BMS01 65535 "SNA" ;
VAL_ 1984 brickVoltage230_BMS01 65535 "SNA" ;
VAL_ 1984 brickVoltage231_BMS01 65535 "SNA" ;
VAL_ 1984 brickVoltage232_BMS01 65535 "SNA" ;
VAL_ 1984 brickVoltage233_BMS01 65535 "SNA" ;
VAL_ 1984 brickVoltage234_BMS01 65535 "SNA" ;
VAL_ 1984 brickVoltage235_BMS01 65535 "SNA" ;
VAL_ 1984 brickVoltage236_BMS01 65535 "SNA" ;
VAL_ 1984 brickVoltage237_BMS01 65535 "SNA" ;
VAL_ 1984 brickVoltage238_BMS01 65535 "SNA" ;
VAL_ 1984 brickVoltage239_BMS01 65535 "SNA" ;
VAL_ 1984 brickVoltage240_BMS01 65535 "SNA" ;
VAL_ 1984 brickVoltage241_BMS01 65535 "SNA" ;
VAL_ 1984 brickVoltage242_BMS01 65535 "SNA" ;
VAL_ 1984 brickVoltage243_BMS01 65535 "SNA" ;
VAL_ 1984 brickVoltage244_BMS01 65535 "SNA" ;
VAL_ 1984 brickVoltage245_BMS01 65535 "SNA" ;
VAL_ 1984 brickVoltage246_BMS01 65535 "SNA" ;
VAL_ 1984 brickVoltage247_BMS01 65535 "SNA" ;
VAL_ 1984 brickVoltage248_BMS01 65535 "SNA" ;
VAL_ 1984 brickVoltage249_BMS01 65535 "SNA" ;
VAL_ 1984 brickVoltage250_BMS01 65535 "SNA" ;
VAL_ 1984 brickVoltage251_BMS01 65535 "SNA" ;
VAL_ 1984 brickVoltage252_BMS01 65535 "SNA" ;
VAL_ 1984 brickVoltage253_BMS01 65535 "SNA" ;
VAL_ 1984 brickVoltage254_BMS01 65535 "SNA" ;
VAL_ 1984 brickVoltage255_BMS01 65535 "SNA" ;
VAL_ 1984 brickVoltage256_BMS01 65535 "SNA" ;
VAL_ 1984 brickVoltage257_BMS01 65535 "SNA" ;
VAL_ 1984 brickVoltage258_BMS01 65535 "SNA" ;
VAL_ 1984 brickVoltage259_BMS01 65535 "SNA" ;
VAL_ 1984 brickVoltage260_BMS01 65535 "SNA" ;
VAL_ 1984 brickVoltage261_BMS01 65535 "SNA" ;
VAL_ 1984 brickVoltage262_BMS01 65535 "SNA" ;
VAL_ 1984 brickVoltage263_BMS01 65535 "SNA" ;
VAL_ 1984 brickVoltage264_BMS01 65535 "SNA" ;
VAL_ 1984 brickVoltage265_BMS01 65535 "SNA" ;
VAL_ 1984 brickVoltage266_BMS01 65535 "SNA" ;
VAL_ 1984 brickVoltage267_BMS01 65535 "SNA" ;
VAL_ 1984 brickVoltage268_BMS01 65535 "SNA" ;
VAL_ 1984 brickVoltage269_BMS01 65535 "SNA" ;
VAL_ 1984 brickVoltage270_BMS01 65535 "SNA" ;
VAL_ 1984 brickVoltage271_BMS01 65535 "SNA" ;
VAL_ 1984 brickVoltage272_BMS01 65535 "SNA" ;
VAL_ 1984 brickVoltage273_BMS01 65535 "SNA" ;
VAL_ 1984 brickVoltage274_BMS01 65535 "SNA" ;
VAL_ 1984 brickVoltage275_BMS01 65535 "SNA" ;
VAL_ 1984 brickVoltage276_BMS01 65535 "SNA" ;
VAL_ 1984 brickVoltage277_BMS01 65535 "SNA" ;
VAL_ 1984 brickVoltage278_BMS01 65535 "SNA" ;
VAL_ 1984 brickVoltage279_BMS01 65535 "SNA" ;
VAL_ 1984 brickVoltage280_BMS01 65535 "SNA" ;
VAL_ 1984 brickVoltage281_BMS01 65535 "SNA" ;
VAL_ 1984 brickVoltage282_BMS01 65535 "SNA" ;
VAL_ 1984 brickVoltage283_BMS01 65535 "SNA" ;
VAL_ 1984 brickVoltage284_BMS01 65535 "SNA" ;
VAL_ 1984 brickVoltage285_BMS01 65535 "SNA" ;
VAL_ 1984 brickVoltage286_BMS01 65535 "SNA" ;
VAL_ 1984 brickVoltage287_BMS01 65535 "SNA" ;
VAL_ 1984 brickVoltage288_BMS01 65535 "SNA" ;
VAL_ 1984 brickVoltage289_BMS01 65535 "SNA" ;
VAL_ 1984 brickVoltage290_BMS01 65535 "SNA" ;
VAL_ 1984 brickVoltage291_BMS01 65535 "SNA" ;
VAL_ 1984 brickVoltage292_BMS01 65535 "SNA" ;
VAL_ 1984 brickVoltage293_BMS01 65535 "SNA" ;
VAL_ 1984 brickVoltage294_BMS01 65535 "SNA" ;
VAL_ 1984 brickVoltage295_BMS01 65535 "SNA" ;
VAL_ 1984 brickVoltage296_BMS01 65535 "SNA" ;
VAL_ 1984 brickVoltage297_BMS01 65535 "SNA" ;
VAL_ 1984 brickVoltage298_BMS01 65535 "SNA" ;
VAL_ 1984 brickVoltage299_BMS01 65535 "SNA" ;
VAL_ 1984 brickVoltage300_BMS01 65535 "SNA" ;
VAL_ 1984 moduleTemperature33_BMS01 255 "SNA" ;
VAL_ 1984 moduleTemperature34_BMS01 255 "SNA" ;
VAL_ 1984 moduleTemperature35_BMS01 255 "SNA" ;
VAL_ 1984 moduleTemperature36_BMS01 255 "SNA" ;
VAL_ 1984 moduleTemperature37_BMS01 255 "SNA" ;
VAL_ 1984 moduleTemperature38_BMS01 255 "SNA" ;
VAL_ 1984 moduleTemperature39_BMS01 255 "SNA" ;
VAL_ 1984 moduleTemperature40_BMS01 255 "SNA" ;
VAL_ 1984 moduleTemperature41_BMS01 255 "SNA" ;
VAL_ 1984 moduleTemperature42_BMS01 255 "SNA" ;
VAL_ 1984 moduleTemperature43_BMS01 255 "SNA" ;
VAL_ 1984 moduleTemperature44_BMS01 255 "SNA" ;
VAL_ 1984 moduleTemperature45_BMS01 255 "SNA" ;
VAL_ 1984 moduleTemperature46_BMS01 255 "SNA" ;
VAL_ 1984 moduleTemperature47_BMS01 255 "SNA" ;
VAL_ 1984 moduleTemperature48_BMS01 255 "SNA" ;
VAL_ 1984 moduleTemperature49_BMS01 255 "SNA" ;
VAL_ 1984 moduleTemperature50_BMS01 255 "SNA" ;
VAL_ 1984 moduleTemperature51_BMS01 255 "SNA" ;
VAL_ 1984 moduleTemperature52_BMS01 255 "SNA" ;
VAL_ 1984 moduleTemperature53_BMS01 255 "SNA" ;
VAL_ 1984 moduleTemperature54_BMS01 255 "SNA" ;
VAL_ 1984 moduleTemperature55_BMS01 255 "SNA" ;
VAL_ 1984 moduleTemperature56_BMS01 255 "SNA" ;
VAL_ 1984 moduleTemperature57_BMS01 255 "SNA" ;
VAL_ 1984 moduleTemperature58_BMS01 255 "SNA" ;
VAL_ 1984 moduleTemperature59_BMS01 255 "SNA" ;
VAL_ 1984 moduleTemperature60_BMS01 255 "SNA" ;
VAL_ 1984 moduleTemperature61_BMS01 255 "SNA" ;
VAL_ 1984 moduleTemperature62_BMS01 255 "SNA" ;
VAL_ 1984 moduleTemperature63_BMS01 255 "SNA" ;
VAL_ 1984 moduleTemperature64_BMS01 255 "SNA" ;
VAL_ 1984 moduleTemperature65_BMS01 255 "SNA" ;
VAL_ 1984 moduleTemperature66_BMS01 255 "SNA" ;
VAL_ 1984 moduleTemperature67_BMS01 255 "SNA" ;
VAL_ 1984 moduleTemperature68_BMS01 255 "SNA" ;
VAL_ 1984 moduleTemperature69_BMS01 255 "SNA" ;
VAL_ 1984 moduleTemperature70_BMS01 255 "SNA" ;
VAL_ 1984 moduleTemperature71_BMS01 255 "SNA" ;
VAL_ 1984 moduleTemperature72_BMS01 255 "SNA" ;
VAL_ 1984 moduleTemperature73_BMS01 255 "SNA" ;
VAL_ 1984 moduleTemperature74_BMS01 255 "SNA" ;
VAL_ 1984 moduleTemperature75_BMS01 255 "SNA" ;
VAL_ 1984 moduleTemperature76_BMS01 255 "SNA" ;
VAL_ 1984 moduleTemperature77_BMS01 255 "SNA" ;
VAL_ 1984 moduleTemperature78_BMS01 255 "SNA" ;
VAL_ 1984 moduleTemperature79_BMS01 255 "SNA" ;
VAL_ 1984 moduleTemperature80_BMS01 255 "SNA" ;
VAL_ 1984 moduleTemperature81_BMS01 255 "SNA" ;
VAL_ 1984 moduleTemperature82_BMS01 255 "SNA" ;
VAL_ 1984 moduleTemperature83_BMS01 255 "SNA" ;
VAL_ 1984 moduleTemperature84_BMS01 255 "SNA" ;
VAL_ 1984 moduleTemperature85_BMS01 255 "SNA" ;
VAL_ 1984 moduleTemperature86_BMS01 255 "SNA" ;
VAL_ 1984 moduleTemperature87_BMS01 255 "SNA" ;
VAL_ 1984 moduleTemperature88_BMS01 255 "SNA" ;
VAL_ 1984 moduleTemperature89_BMS01 255 "SNA" ;
VAL_ 1984 moduleTemperature90_BMS01 255 "SNA" ;
VAL_ 1984 moduleTemperature91_BMS01 255 "SNA" ;
VAL_ 1984 moduleTemperature92_BMS01 255 "SNA" ;
VAL_ 1984 moduleTemperature93_BMS01 255 "SNA" ;
VAL_ 1984 moduleTemperature94_BMS01 255 "SNA" ;
VAL_ 1984 moduleTemperature95_BMS01 255 "SNA" ;
VAL_ 1984 moduleTemperature96_BMS01 255 "SNA" ;
VAL_ 1984 moduleTemperature97_BMS01 255 "SNA" ;
VAL_ 1984 moduleTemperature98_BMS01 255 "SNA" ;
VAL_ 1984 moduleTemperature99_BMS01 255 "SNA" ;
VAL_ 1984 moduleTemperature100_BMS01 255 "SNA" ;
VAL_ 768 essShutdownTarget_BMS 15 "STATE_INVALID" 6 "STATE_SYSTEM_FAULT" 5 "STATE_STRING_FAULT" 4 "STATE_LIMPHOME" 3 "STATE_ACCESSORY" 2 "STATE_CHARGE" 1 "STATE_DRIVE" 0 "STATE_STANDBY" ;
VAL_ 768 essShutdownTimer_BMS 65535 "SNA" ;
VAL_ 768 essMstrState_BMS01 15 "STATE_INVALID" 6 "STATE_ESS_FAULT" 5 "STATE_STRING_FAULT" 4 "STATE_LIMPHOME" 3 "STATE_ACCESSORY" 2 "STATE_CHARGE" 1 "STATE_DRIVE" 0 "STATE_STANDBY" ;
VAL_ 768 essMstrStateRequest_BMS 15 "STATE_INVALID" 6 "STATE_ESS_FAULT" 5 "STATE_STRING_FAULT" 4 "STATE_LIMPHOME" 3 "STATE_ACCESSORY" 2 "STATE_CHARGE" 1 "STATE_DRIVE" 0 "STATE_STANDBY" ;
VAL_ 768 essMstrOverallChargeState_BMS 15 "CHARGESTATE_INVALID" 1 "CHARGESTATE_COMPLETE" 0 "CHARGESTATE_NOTCOMPLETE" ;
VAL_ 284 rangeRequestCmdIgnoreVehicle_ME 255 "NO_COMMAND" 1 "IGNORE" 0 "DO_NOT_IGNORE" ;
VAL_ 284 rangeRequestCmdEepromValue_ME 255 "NO_COMMAND" 15 "RANGE_INVALID" 14 "RANGE_MAXIMUM" 13 "RANGE_MODESOH8" 12 "RANGE_MODESOH7" 11 "RANGE_MODESOH6" 10 "RANGE_MODESOH5" 9 "RANGE_MODESOH4" 8 "RANGE_MODESOH3" 7 "RANGE_MODESOH2" 6 "RANGE_MODESOH1" 5 "RANGE_MODE407" 4 "RANGE_MODE405" 3 "RANGE_MODE4175" 2 "RANGE_MODE415" 1 "RANGE_LIMITED" 0 "RANGE_SHIPPING" ;
VAL_ 284 rangeRequestCmdPassword_ME 65535 "SNA" ;
VAL_ 284 resetAuxCntrOpnUnderLoadCntr_ME 255 "SNA" ;
VAL_ 284 thermalEventResetPass_ME 65535 "SNA" ;
VAL_ 284 thermalEventReset_ME 1 "THERMAL_RESET_RESET" 255 "THERMAL_RESET_SNA" ;
VAL_ 284 selfTestFault_ME 6 "SELFTEST_DATA_ABORT" 5 "SELFTEST_2_BIT_FLASH_ECC" 4 "SELFTEST_1_BIT_FLASH_ECC" 3 "SELFTEST_2_BIT_ODD_RAM_ECC" 2 "SELFTEST_1_BIT_ODD_RAM_ECC" 1 "SELFTEST_2_BIT_EVEN_RAM_ECC" 0 "SELFTEST_1_BIT_EVEN_RAM_ECC" 255 "SELFTEST_FAULT_NONE" ;
VAL_ 284 selfTestFaultInjectPass_ME 65535 "SNA" ;
VAL_ 284 resetStatistics_ME 255 "SNA" ;
VAL_ 284 safetyCANMsgFault_ME 1 "SAFETY_MSG_SPI_BROKEN" 0 "SAFETY_MSG_SPI_CRC" 255 "SAFETY_MSG_FAULT_NONE" ;
VAL_ 284 safetyCANMsgID_ME 4 "SAFETY_MSG_ALL" 3 "SAFETY_MSG_VEPM_REQ_ST3" 2 "SAFETY_MSG_BMS1_ST3" 1 "SAFETY_MSG_HV_BAT" 0 "SAFETY_MSG_BMS_DISP_REQ" 255 "SAFETY_MSG_NONE" ;
VAL_ 284 safetyCANFaultInjectPass_ME 65535 "SNA" ;
VAL_ 284 setResetHVLockPassword_ME 65535 "SNA" ;
VAL_ 284 setResetHVLock_ME 255 "SNA" ;
VAL_ 284 initialCapacityPW_ME 65535 "SNA" ;
VAL_ 284 initialCapacity_ME 65535 "SNA" ;
VAL_ 284 resetFusiLockPassword_ME 65535 "SNA" ;
VAL_ 284 resetFusiLock_ME 255 "SNA" ;
VAL_ 284 eventMapDebugEventStatus_ME 3 "DEM_INVALID" 2 "DEM_FAILED" 1 "DEM_PASSED" 0 "DEM_NOTTESTED" ;
VAL_ 284 setPerformanceMode_ME 1 "High Performance" 0 "Normal" ;
VAL_ 284 debugCtrlChargerCC_ME 255 "SW_NOCONTROL" 1 "SW_ON" 0 "SW_OFF" ;
VAL_ 284 BMSIDmult31_ME 255 "SNA" ;
VAL_ 284 BMSIDmult30_ME 255 "SNA" ;
VAL_ 284 storeCalibrationsInEeprom_ME 1 "CALIBRATIONS_STORE_PRESENT" 0 "CALIBRATIONS_REVERT_TO_INITIAL" ;
VAL_ 284 debugCtrlZDWLSDEN_ME 255 "NOCOMMAND" ;
VAL_ 284 debugCtrlPyroEN_ME 255 "NOCOMMAND" ;
VAL_ 284 ssaRTOffsetDay_ME 255 "SNA" ;
VAL_ 284 ssaRTOffsetMonth_ME 255 "SNA" ;
VAL_ 284 BMSIDmult28_ME 255 "SNA" ;
VAL_ 284 setDebugMsgSpeed_ME 3 "DEBUGSPEED_SLOW" 2 "DEBUGSPEED_MEDIUM" 1 "DEBUGSPEED_FAST" 0 "DEBUGSPEED_AUTO" ;
VAL_ 284 commandOCVRecalibration_ME 255 "OCVRECALIBRATION_INVALID" 1 "OCVRECALIBRATION_ACTIVE" 0 "OCVRECALIBRATION_INACTIVE" ;
VAL_ 284 ctrOffTimeSetPW_ME 65535 "SNA" ;
VAL_ 284 setCtrOffTime_ME 65535 "SNA" ;
VAL_ 284 BMSIDmult27_ME 255 "SNA" ;
VAL_ 284 BMSIDmult26_ME 255 "SNA" ;
VAL_ 284 BMSIDmult24_ME 255 "SNA" ;
VAL_ 284 BMSIDmult23_ME 255 "SNA" ;
VAL_ 284 resetHistoPassword_ME 65535 "SNA" ;
VAL_ 284 resetCntrHistograms_ME 255 "SNA" ;
VAL_ 284 BMSIDmult22_ME 255 "SNA" ;
VAL_ 284 contactorTypeResetPassword_ME 65535 "SNA" ;
VAL_ 284 contactorType_ME 15 "SNA" 1 "CTR_TYPE_GV240_12V" 0 "CTR_TYPE_CALIBRATION (GV240_24V)" ;
VAL_ 284 BMSIDmult21_ME 255 "SNA" ;
VAL_ 284 SOHRecalDiagPassword_ME 65535 "SNA" ;
VAL_ 284 SOHBrickIndex_ME 4095 "SNA" 4094 "ALL_BRICKS" ;
VAL_ 284 SOHValue_ME 65535 "SNA" ;
VAL_ 284 SOHType_ME 15 "SNA" 4 "SOC" 3 "SOH_ALL" 2 "SOHR_REGEN" 1 "SOHR_DCHG" 0 "SOHC" ;
VAL_ 284 clearEventDebugExtIso_ME 255 "NOCOMMAND" ;
VAL_ 284 clearEventDebugVPlausibility_ME 255 "NOCOMMAND" ;
VAL_ 284 clearEventDebugHighSevCrash_ME 255 "NOCOMMAND" ;
VAL_ 284 BMSIDmult20_ME 64 "ALL" 255 "SNA" ;
VAL_ 284 enableDbgMsgsPTCAN_ME 255 "INVALID" 1 "ENABLE" 0 "DISABLE" ;
VAL_ 284 BMSIDmult19_ME 64 "ALL" 255 "SNA" ;
VAL_ 284 contactorRequestPos3_ME 255 "CONTACTOR_NOCONTROL" 1 "CONTACTOR_ON" 0 "CONTACTOR_OFF" ;
VAL_ 284 contactorRequestNeg3_ME 255 "CONTACTOR_NOCONTROL" 1 "CONTACTOR_ON" 0 "CONTACTOR_OFF" ;
VAL_ 284 contactorRequestPrechg2_ME 255 "CONTACTOR_NOCONTROL" 1 "CONTACTOR_ON" 0 "CONTACTOR_OFF" ;
VAL_ 284 contactorRequestPos2_ME 255 "CONTACTOR_NOCONTROL" 1 "CONTACTOR_ON" 0 "CONTACTOR_OFF" ;
VAL_ 284 contactorRequestNeg2_ME 255 "CONTACTOR_NOCONTROL" 1 "CONTACTOR_ON" 0 "CONTACTOR_OFF" ;
VAL_ 284 BMSIDmult18_ME 64 "ALL" 255 "SNA" ;
VAL_ 284 BMSIDmult17_ME 64 "ALL" 255 "SNA" ;
VAL_ 284 commandPumpSpeed_ME 255 "SNA" ;
VAL_ 284 pumpSpeedMaxLimit_ME 255 "SNA" ;
VAL_ 284 isoSwRequestLink_ME 255 "SW_NOCONTROL" 1 "SW_ON" 0 "SW_OFF" ;
VAL_ 284 debugCtrlGPIO2_ME 255 "NOCOMMAND" ;
VAL_ 284 debugCtrlGPIO1_ME 255 "NOCOMMAND" ;
VAL_ 284 debugCtrlGPIsenseSel_ME 255 "NOCOMMAND" ;
VAL_ 284 BMSIDmult16_ME 255 "SNA" ;
VAL_ 284 BMSIDmult15_ME 255 "SNA" ;
VAL_ 284 debugCtrlCurrentSense_ME 255 "NOCOMMAND" ;
VAL_ 284 BMSIDmult14_ME 255 "SNA" ;
VAL_ 284 clearEventDebugVDeepDch_ME 255 "NOCOMMAND" ;
VAL_ 284 BMSIDmult13_ME 255 "SNA" ;
VAL_ 284 eventMapDebugEventID_ME 65535 "SNA" ;
VAL_ 284 BMSIDmult12_ME 64 "ALL" 255 "SNA" ;
VAL_ 284 BMSIDmult11_ME 64 "ALL" 255 "SNA" ;
VAL_ 284 BMSIDmult10_ME 64 "ALL" 255 "SNA" ;
VAL_ 284 desiccantTimer_ME -1 "SNA" ;
VAL_ 284 isoSwRequestPos_ME 255 "SW_NOCONTROL" 1 "SW_ON" 0 "SW_OFF" ;
VAL_ 284 isoSwRequestNeg_ME 255 "SW_NOCONTROL" 1 "SW_ON" 0 "SW_OFF" ;
VAL_ 284 eepromResetStruct_ME 171 "EEPROM_INVALIDATE_ALLBLOCKS" 170 "EEPROM_RESET_ALLBLOCKS" 8 "EEPROM_RESET_CHRONOSTACK" 7 "EEPROM_RESET_UDSDATA" 6 "EEPROM_RESET_CUSTDATA" 4 "EEPROM_RESET_SOH" 3 "EEPROM_RESET_SOC" 2 "EEPROM_RESET_DIAGDATA" 1 "EEPROM_RESET_BASICDATA" ;
VAL_ 284 BMSIDmult09_ME 64 "ALL" 255 "SNA" ;
VAL_ 284 BMSIDmult08_ME 64 "ALL" 255 "SNA" ;
VAL_ 284 BMSIDmult07_ME 64 "ALL" 255 "SNA" ;
VAL_ 284 BMSIDmult06_ME 64 "ALL" 255 "SNA" ;
VAL_ 284 BMSIDmult05_ME 64 "ALL" 255 "SNA" ;
VAL_ 284 ecuSerialNumberChar01_ME 90 "'Z'" 89 "'Y'" 88 "'X'" 87 "'W'" 86 "'V'" 85 "'U'" 84 "'T'" 83 "'S'" 82 "'R'" 81 "'Q'" 80 "'P'" 79 "'O'" 78 "'N'" 77 "'M'" 76 "'L'" 75 "'K'" 74 "'J'" 73 "'I'" 72 "'H'" 71 "'G'" 70 "'F'" 69 "'E'" 68 "'D'" 67 "'C'" 66 "'B'" 65 "'A'" 57 "'9'" 56 "'8'" 55 "'7'" 54 "'6'" 53 "'5'" 52 "'4'" 51 "'3'" 50 "'2'" 49 "'1'" 48 "'0'" ;
VAL_ 284 ecuSerialNumberChar02_ME 90 "'Z'" 89 "'Y'" 88 "'X'" 87 "'W'" 86 "'V'" 85 "'U'" 84 "'T'" 83 "'S'" 82 "'R'" 81 "'Q'" 80 "'P'" 79 "'O'" 78 "'N'" 77 "'M'" 76 "'L'" 75 "'K'" 74 "'J'" 73 "'I'" 72 "'H'" 71 "'G'" 70 "'F'" 69 "'E'" 68 "'D'" 67 "'C'" 66 "'B'" 65 "'A'" 57 "'9'" 56 "'8'" 55 "'7'" 54 "'6'" 53 "'5'" 52 "'4'" 51 "'3'" 50 "'2'" 49 "'1'" 48 "'0'" ;
VAL_ 284 ecuSerialNumberChar03_ME 90 "'Z'" 89 "'Y'" 88 "'X'" 87 "'W'" 86 "'V'" 85 "'U'" 84 "'T'" 83 "'S'" 82 "'R'" 81 "'Q'" 80 "'P'" 79 "'O'" 78 "'N'" 77 "'M'" 76 "'L'" 75 "'K'" 74 "'J'" 73 "'I'" 72 "'H'" 71 "'G'" 70 "'F'" 69 "'E'" 68 "'D'" 67 "'C'" 66 "'B'" 65 "'A'" 57 "'9'" 56 "'8'" 55 "'7'" 54 "'6'" 53 "'5'" 52 "'4'" 51 "'3'" 50 "'2'" 49 "'1'" 48 "'0'" ;
VAL_ 284 ecuSerialNumberChar04_ME 90 "'Z'" 89 "'Y'" 88 "'X'" 87 "'W'" 86 "'V'" 85 "'U'" 84 "'T'" 83 "'S'" 82 "'R'" 81 "'Q'" 80 "'P'" 79 "'O'" 78 "'N'" 77 "'M'" 76 "'L'" 75 "'K'" 74 "'J'" 73 "'I'" 72 "'H'" 71 "'G'" 70 "'F'" 69 "'E'" 68 "'D'" 67 "'C'" 66 "'B'" 65 "'A'" 57 "'9'" 56 "'8'" 55 "'7'" 54 "'6'" 53 "'5'" 52 "'4'" 51 "'3'" 50 "'2'" 49 "'1'" 48 "'0'" ;
VAL_ 284 ecuSerialNumberChar05_ME 90 "'Z'" 89 "'Y'" 88 "'X'" 87 "'W'" 86 "'V'" 85 "'U'" 84 "'T'" 83 "'S'" 82 "'R'" 81 "'Q'" 80 "'P'" 79 "'O'" 78 "'N'" 77 "'M'" 76 "'L'" 75 "'K'" 74 "'J'" 73 "'I'" 72 "'H'" 71 "'G'" 70 "'F'" 69 "'E'" 68 "'D'" 67 "'C'" 66 "'B'" 65 "'A'" 57 "'9'" 56 "'8'" 55 "'7'" 54 "'6'" 53 "'5'" 52 "'4'" 51 "'3'" 50 "'2'" 49 "'1'" 48 "'0'" ;
VAL_ 284 ecuSerialNumberChar06_ME 90 "'Z'" 89 "'Y'" 88 "'X'" 87 "'W'" 86 "'V'" 85 "'U'" 84 "'T'" 83 "'S'" 82 "'R'" 81 "'Q'" 80 "'P'" 79 "'O'" 78 "'N'" 77 "'M'" 76 "'L'" 75 "'K'" 74 "'J'" 73 "'I'" 72 "'H'" 71 "'G'" 70 "'F'" 69 "'E'" 68 "'D'" 67 "'C'" 66 "'B'" 65 "'A'" 57 "'9'" 56 "'8'" 55 "'7'" 54 "'6'" 53 "'5'" 52 "'4'" 51 "'3'" 50 "'2'" 49 "'1'" 48 "'0'" ;
VAL_ 284 ecuSerialNumberChar07_ME 90 "'Z'" 89 "'Y'" 88 "'X'" 87 "'W'" 86 "'V'" 85 "'U'" 84 "'T'" 83 "'S'" 82 "'R'" 81 "'Q'" 80 "'P'" 79 "'O'" 78 "'N'" 77 "'M'" 76 "'L'" 75 "'K'" 74 "'J'" 73 "'I'" 72 "'H'" 71 "'G'" 70 "'F'" 69 "'E'" 68 "'D'" 67 "'C'" 66 "'B'" 65 "'A'" 57 "'9'" 56 "'8'" 55 "'7'" 54 "'6'" 53 "'5'" 52 "'4'" 51 "'3'" 50 "'2'" 49 "'1'" 48 "'0'" ;
VAL_ 284 ecuSerialNumberChar08_ME 90 "'Z'" 89 "'Y'" 88 "'X'" 87 "'W'" 86 "'V'" 85 "'U'" 84 "'T'" 83 "'S'" 82 "'R'" 81 "'Q'" 80 "'P'" 79 "'O'" 78 "'N'" 77 "'M'" 76 "'L'" 75 "'K'" 74 "'J'" 73 "'I'" 72 "'H'" 71 "'G'" 70 "'F'" 69 "'E'" 68 "'D'" 67 "'C'" 66 "'B'" 65 "'A'" 57 "'9'" 56 "'8'" 55 "'7'" 54 "'6'" 53 "'5'" 52 "'4'" 51 "'3'" 50 "'2'" 49 "'1'" 48 "'0'" ;
VAL_ 284 ecuSerialNumberChar09_ME 90 "'Z'" 89 "'Y'" 88 "'X'" 87 "'W'" 86 "'V'" 85 "'U'" 84 "'T'" 83 "'S'" 82 "'R'" 81 "'Q'" 80 "'P'" 79 "'O'" 78 "'N'" 77 "'M'" 76 "'L'" 75 "'K'" 74 "'J'" 73 "'I'" 72 "'H'" 71 "'G'" 70 "'F'" 69 "'E'" 68 "'D'" 67 "'C'" 66 "'B'" 65 "'A'" 57 "'9'" 56 "'8'" 55 "'7'" 54 "'6'" 53 "'5'" 52 "'4'" 51 "'3'" 50 "'2'" 49 "'1'" 48 "'0'" ;
VAL_ 284 ecuSerialNumberChar10_ME 90 "'Z'" 89 "'Y'" 88 "'X'" 87 "'W'" 86 "'V'" 85 "'U'" 84 "'T'" 83 "'S'" 82 "'R'" 81 "'Q'" 80 "'P'" 79 "'O'" 78 "'N'" 77 "'M'" 76 "'L'" 75 "'K'" 74 "'J'" 73 "'I'" 72 "'H'" 71 "'G'" 70 "'F'" 69 "'E'" 68 "'D'" 67 "'C'" 66 "'B'" 65 "'A'" 57 "'9'" 56 "'8'" 55 "'7'" 54 "'6'" 53 "'5'" 52 "'4'" 51 "'3'" 50 "'2'" 49 "'1'" 48 "'0'" ;
VAL_ 284 ecuSerialNumberChar11_ME 90 "'Z'" 89 "'Y'" 88 "'X'" 87 "'W'" 86 "'V'" 85 "'U'" 84 "'T'" 83 "'S'" 82 "'R'" 81 "'Q'" 80 "'P'" 79 "'O'" 78 "'N'" 77 "'M'" 76 "'L'" 75 "'K'" 74 "'J'" 73 "'I'" 72 "'H'" 71 "'G'" 70 "'F'" 69 "'E'" 68 "'D'" 67 "'C'" 66 "'B'" 65 "'A'" 57 "'9'" 56 "'8'" 55 "'7'" 54 "'6'" 53 "'5'" 52 "'4'" 51 "'3'" 50 "'2'" 49 "'1'" 48 "'0'" ;
VAL_ 284 ecuSerialNumberChar12_ME 90 "'Z'" 89 "'Y'" 88 "'X'" 87 "'W'" 86 "'V'" 85 "'U'" 84 "'T'" 83 "'S'" 82 "'R'" 81 "'Q'" 80 "'P'" 79 "'O'" 78 "'N'" 77 "'M'" 76 "'L'" 75 "'K'" 74 "'J'" 73 "'I'" 72 "'H'" 71 "'G'" 70 "'F'" 69 "'E'" 68 "'D'" 67 "'C'" 66 "'B'" 65 "'A'" 57 "'9'" 56 "'8'" 55 "'7'" 54 "'6'" 53 "'5'" 52 "'4'" 51 "'3'" 50 "'2'" 49 "'1'" 48 "'0'" ;
VAL_ 284 ecuSerialNumberChar13_ME 90 "'Z'" 89 "'Y'" 88 "'X'" 87 "'W'" 86 "'V'" 85 "'U'" 84 "'T'" 83 "'S'" 82 "'R'" 81 "'Q'" 80 "'P'" 79 "'O'" 78 "'N'" 77 "'M'" 76 "'L'" 75 "'K'" 74 "'J'" 73 "'I'" 72 "'H'" 71 "'G'" 70 "'F'" 69 "'E'" 68 "'D'" 67 "'C'" 66 "'B'" 65 "'A'" 57 "'9'" 56 "'8'" 55 "'7'" 54 "'6'" 53 "'5'" 52 "'4'" 51 "'3'" 50 "'2'" 49 "'1'" 48 "'0'" ;
VAL_ 284 ecuSerialNumberChar14_ME 90 "'Z'" 89 "'Y'" 88 "'X'" 87 "'W'" 86 "'V'" 85 "'U'" 84 "'T'" 83 "'S'" 82 "'R'" 81 "'Q'" 80 "'P'" 79 "'O'" 78 "'N'" 77 "'M'" 76 "'L'" 75 "'K'" 74 "'J'" 73 "'I'" 72 "'H'" 71 "'G'" 70 "'F'" 69 "'E'" 68 "'D'" 67 "'C'" 66 "'B'" 65 "'A'" 57 "'9'" 56 "'8'" 55 "'7'" 54 "'6'" 53 "'5'" 52 "'4'" 51 "'3'" 50 "'2'" 49 "'1'" 48 "'0'" ;
VAL_ 284 ecuSerialNumberChar15_ME 90 "'Z'" 89 "'Y'" 88 "'X'" 87 "'W'" 86 "'V'" 85 "'U'" 84 "'T'" 83 "'S'" 82 "'R'" 81 "'Q'" 80 "'P'" 79 "'O'" 78 "'N'" 77 "'M'" 76 "'L'" 75 "'K'" 74 "'J'" 73 "'I'" 72 "'H'" 71 "'G'" 70 "'F'" 69 "'E'" 68 "'D'" 67 "'C'" 66 "'B'" 65 "'A'" 57 "'9'" 56 "'8'" 55 "'7'" 54 "'6'" 53 "'5'" 52 "'4'" 51 "'3'" 50 "'2'" 49 "'1'" 48 "'0'" ;
VAL_ 284 ecuSerialNumberChar16_ME 90 "'Z'" 89 "'Y'" 88 "'X'" 87 "'W'" 86 "'V'" 85 "'U'" 84 "'T'" 83 "'S'" 82 "'R'" 81 "'Q'" 80 "'P'" 79 "'O'" 78 "'N'" 77 "'M'" 76 "'L'" 75 "'K'" 74 "'J'" 73 "'I'" 72 "'H'" 71 "'G'" 70 "'F'" 69 "'E'" 68 "'D'" 67 "'C'" 66 "'B'" 65 "'A'" 57 "'9'" 56 "'8'" 55 "'7'" 54 "'6'" 53 "'5'" 52 "'4'" 51 "'3'" 50 "'2'" 49 "'1'" 48 "'0'" ;
VAL_ 284 ecuSerialNumberChar17_ME 90 "'Z'" 89 "'Y'" 88 "'X'" 87 "'W'" 86 "'V'" 85 "'U'" 84 "'T'" 83 "'S'" 82 "'R'" 81 "'Q'" 80 "'P'" 79 "'O'" 78 "'N'" 77 "'M'" 76 "'L'" 75 "'K'" 74 "'J'" 73 "'I'" 72 "'H'" 71 "'G'" 70 "'F'" 69 "'E'" 68 "'D'" 67 "'C'" 66 "'B'" 65 "'A'" 57 "'9'" 56 "'8'" 55 "'7'" 54 "'6'" 53 "'5'" 52 "'4'" 51 "'3'" 50 "'2'" 49 "'1'" 48 "'0'" ;
VAL_ 284 ecuSerialNumberChar18_ME 90 "'Z'" 89 "'Y'" 88 "'X'" 87 "'W'" 86 "'V'" 85 "'U'" 84 "'T'" 83 "'S'" 82 "'R'" 81 "'Q'" 80 "'P'" 79 "'O'" 78 "'N'" 77 "'M'" 76 "'L'" 75 "'K'" 74 "'J'" 73 "'I'" 72 "'H'" 71 "'G'" 70 "'F'" 69 "'E'" 68 "'D'" 67 "'C'" 66 "'B'" 65 "'A'" 57 "'9'" 56 "'8'" 55 "'7'" 54 "'6'" 53 "'5'" 52 "'4'" 51 "'3'" 50 "'2'" 49 "'1'" 48 "'0'" ;
VAL_ 284 ecuSerialNumberChar19_ME 90 "'Z'" 89 "'Y'" 88 "'X'" 87 "'W'" 86 "'V'" 85 "'U'" 84 "'T'" 83 "'S'" 82 "'R'" 81 "'Q'" 80 "'P'" 79 "'O'" 78 "'N'" 77 "'M'" 76 "'L'" 75 "'K'" 74 "'J'" 73 "'I'" 72 "'H'" 71 "'G'" 70 "'F'" 69 "'E'" 68 "'D'" 67 "'C'" 66 "'B'" 65 "'A'" 57 "'9'" 56 "'8'" 55 "'7'" 54 "'6'" 53 "'5'" 52 "'4'" 51 "'3'" 50 "'2'" 49 "'1'" 48 "'0'" ;
VAL_ 284 BMSIDmult04_ME 64 "ALL" 255 "SNA" ;
VAL_ 284 BMSIDmult03_ME 64 "ALL" 255 "SNA" ;
VAL_ 284 BMSIDmult02_ME 64 "ALL" 255 "SNA" ;
VAL_ 284 BMSIDmult01_ME 64 "ALL" 255 "SNA" ;
VAL_ 284 sleepRequest_ME 255 "SLEEP_NOCOMMAND" 1 "SLEEP_ON" 0 "SLEEP_OFF" ;
VAL_ 284 heaterRequestCMB_ME 16777215 "NOCOMMAND" ;
VAL_ 284 contactorRequestPrechg_ME 255 "CONTACTOR_NOCONTROL" 1 "CONTACTOR_ON" 0 "CONTACTOR_OFF" ;
VAL_ 284 contactorRequestPos_ME 255 "CONTACTOR_NOCONTROL" 1 "CONTACTOR_ON" 0 "CONTACTOR_OFF" ;
VAL_ 284 contactorRequestNeg_ME 255 "CONTACTOR_NOCONTROL" 1 "CONTACTOR_ON" 0 "CONTACTOR_OFF" ;
VAL_ 284 balancingRequestIndex_ME 255 "BALANCING_NOCONTROL" ;
VAL_ 284 commandMultiplexor_ME 43 "ME43_rangeRequestCmd" 42 "ME42_hvWithstandCounterReset" 41 "ME41_thermalDEMReset" 40 "ME40_selfTestFaultInjection" 39 "ME39_safetyMsgFaultInjection" 38 "ME38_setResetHVLock" 37 "ME37_enableIsenseDebug" 36 "ME36_resetAuxWeldFlags" 35 "ME35_cmdInitialCapacity" 34 "ME34_resetFusiLock" 33 "ME33_setPerformanceMode" 32 "ME32_commandActiveIsoTest" 31 "ME31_storeCalibrationinEeprom" 30 "ME30_developmentCmds" 29 "ME29_resetSSATimeM_RTOffs" 28 "ME28_enterBootloader" 27 "ME27_overwriteLimits" 26 "ME26_writeBMSSerial4" 25 "ME25_writeBMSSerial3" 24 "ME24_writeBMSProdDate" 23 "ME23_resetCntrHistograms" 22 "ME22_setContactorType" 21 "ME21_SOHRecalControl" 20 "ME20_safetyDebugMsgsControl" 19 "ME19_cntrsControl" 18 "ME18_setPumpSpeed" 17 "ME17_setMaxPumpSpeedLimit" 16 "ME16_OCVRecalControl" 15 "ME15_setCurrentSenseSupply" 14 "ME14_cmdClearEventDebug" 13 "ME13_cmdEventMapDebug" 12 "ME12_cmdEnergyThroughput" 11 "ME11_cmdNumberOfStrings" 10 "ME10_cmdDesiccant" 9 "ME9_cmdIsoSw" 8 "ME8_writeBMSSerial2" 7 "ME7_writeBMSSerial1" 5 "ME5_cmdWriteEEPROMWords" 6 "ME6_cmdReadEEPROMWords" 4 "ME4_cmdWriteEEPROMByte" 2 "ME2_cmdBalancingPattern" 1 "ME1_cmdCtrsBalOneCell" 3 "ME3_cmdResetEEPROMStructs" ;
VAL_ 368 fktCommand 5 "SEND_KEY" 4 "REQUEST_SEED" 3 "START_PROCEDURE" ;
VAL_ 352 obdOccurrence_BMS01 127 "SNA" ;
VAL_ 352 obdClearFaultMemory_BMS01 1 "Triggered" 0 "Not triggered" ;
VAL_ 352 obdDTCOdometer_BMS01 65535 "SNA" ;
VAL_ 352 obdDTCId_BMS01 255 "SNA" ;
VAL_ 336 maxSOCIndex_BMS01 65535 "SNA" ;
VAL_ 336 minSOCIndex_BMS01 65535 "SNA" ;
VAL_ 320 cusDschrgEnrgyLifeTime_BMS01 65535 "SNA" ;
VAL_ 320 cusChrgEnrgyLifeTime_BMS01 65535 "SNA" ;
VAL_ 208 stringShutdownTarget_BMS01 6 "STATE_ESS_FAULT" 15 "STATE_INVALID" 5 "STATE_STRING_FAULT" 4 "STATE_LIMPHOME" 3 "STATE_ACCESSORY" 2 "STATE_CHARGE" 1 "STATE_DRIVE" 0 "STATE_STANDBY" ;
VAL_ 208 stringShutdownTimer_BMS01 65535 "SNA" ;
VAL_ 192 cntrStatePrechg2_BMS01 3 "CTR_INVALID" 1 "CTR_ON" 0 "CTR_OFF" ;
VAL_ 192 cntrStatePrechg1_BMS01 3 "CTR_INVALID" 1 "CTR_ON" 0 "CTR_OFF" ;
VAL_ 192 cntrStatePos3_BMS01 3 "CTR_INVALID" 1 "CTR_ON" 0 "CTR_OFF" ;
VAL_ 192 cntrStatePos2_BMS01 3 "CTR_INVALID" 1 "CTR_ON" 0 "CTR_OFF" ;
VAL_ 192 cntrStatePos1_BMS01 3 "CTR_INVALID" 1 "CTR_ON" 0 "CTR_OFF" ;
VAL_ 192 cntrStateNeg3_BMS01 3 "CTR_INVALID" 1 "CTR_ON" 0 "CTR_OFF" ;
VAL_ 192 cntrStateNeg2_BMS01 3 "CTR_INVALID" 1 "CTR_ON" 0 "CTR_OFF" ;
VAL_ 192 cntrStateNeg1_BMS01 3 "CTR_INVALID" 1 "CTR_ON" 0 "CTR_OFF" ;
VAL_ 192 cntrWeldState_BMS01 15 "CTR_WELD_UNKNWON" 3 "CTR_NEG1_WELDED" 2 "CTR_POS1_WELDED" 0 "CTR_NOTWELDED" 1 "CTR_BOTH_WELDED" ;
VAL_ 192 cntrState_BMS01 15 "CTR_INVALID" 3 "CTR_STRING_OPENING" 2 "CTR_STRING_ON" 1 "CTR_STRING_PRECHARGE" 0 "CTR_STRING_OFF" ;
VAL_ 160 regenPowerPredShrt_BMS01 65535 "SNA" ;
VAL_ 160 regenPowerPredLong_BMS01 65535 "SNA" ;
VAL_ 160 dchgPowerPredShrt_BMS01 65535 "SNA" ;
VAL_ 160 dchgPowerPredLong_BMS01 65535 "SNA" ;
VAL_ 176 cusMaxCellVLimit_BMS01 65535 "SNA" ;
VAL_ 176 cusMinCellVLimit_BMS01 65535 "SNA" ;
VAL_ 144 dchgVoltagePredShrt_BMS01 65535 "SNA" ;
VAL_ 144 dchgVoltagePredLong_BMS01 65535 "SNA" ;
VAL_ 144 regenVoltagePredShrt_BMS01 65535 "SNA" ;
VAL_ 144 regenVoltagePredLong_BMS01 65535 "SNA" ;
VAL_ 128 regenCurrentPredShrt_BMS01 65535 "SNA" ;
VAL_ 128 regenCurrentPredLong_BMS01 65535 "SNA" ;
VAL_ 128 dchgCurrentPredShrt_BMS01 65535 "SNA" ;
VAL_ 128 dchgCurrentPredLong_BMS01 65535 "SNA" ;
VAL_ 96 maxDewPointTemperature_BMS01 255 "SNA" ;
VAL_ 96 meanModuleTemperature_BMS01 255 "SNA" ;
VAL_ 96 minBrickCapacity_BMS01 65535 "SNA" ;
VAL_ 96 maxModuleTempIndex_BMS01 255 "SNA" ;
VAL_ 96 minModuleTempIndex_BMS01 255 "SNA" ;
VAL_ 96 maxModuleTempString_BMS01 255 "SNA" ;
VAL_ 96 minModuleTempString_BMS01 255 "SNA" ;
VAL_ 32 brickOpenCircuitV_BMS01 65535 "SNA" ;
VAL_ 32 meanSOC_BMS01 65535 "SNA" ;
VAL_ 32 stringVoltage_BMS01 65535 "SNA" ;
VAL_ 32 chargerCurrentLimit_BMS01 65535 "SNA" ;
VAL_ 0 isolationRequest_BMS01_BMS 4 "ISOLATION_AUXWELD" 15 "ISOLATION_INVALID" 1 "ISOLATION_ACTIVE" 0 "ISOLATION_INACTIVE" ;
VAL_ 0 stringStateReq_BMS01_BMS 6 "STATE_ESS_FAULT" 15 "STATE_INVALID" 5 "STATE_STRING_FAULT" 4 "STATE_LIMPHOME" 3 "STATE_ACCESSORY" 2 "STATE_CHARGE" 1 "STATE_DRIVE" 0 "STATE_STANDBY" ;
VAL_ 0 sleepRequest_BMS01_BMS 15 "SLEEP_INVALID" 1 "SLEEP_ACTIVE" 0 "SLEEP_INACTIVE" ;
VAL_ 80 maxBrickVoltageIndex_BMS01 65535 "SNA" ;
VAL_ 80 minBrickVoltageIndex_BMS01 65535 "SNA" ;
VAL_ 80 minBrickVoltage_BMS01 65535 "SNA" ;
VAL_ 80 maxBrickVoltage_BMS01 65535 "SNA" ;
VAL_ 48 maxSOC_BMS01 65535 "SNA" ;
VAL_ 48 minSOC_BMS01 65535 "SNA" ;
VAL_ 48 isolationResInternal_BMS01 65535 "SNA" ;
VAL_ 48 isolationResExternal_BMS01 65535 "SNA" ;
VAL_ 64 dchgIntResistance_BMS01 65535 "SNA" ;
VAL_ 64 regenIntResistance_BMS01 65535 "SNA" ;
VAL_ 64 maxSOH_BMS01 255 "SNA" ;
VAL_ 64 minSOH_BMS01 255 "SNA" ;
VAL_ 64 energyAvailable_BMS01 65535 "SNA" ;
VAL_ 112 dchgCurrentLimit_BMS01 65535 "SNA" ;
VAL_ 112 regenCurrentLimit_BMS01 65535 "SNA" ;
VAL_ 112 minStringVLimit_BMS01 65535 "SNA" ;
VAL_ 112 maxStringVLimit_BMS01 65535 "SNA" ;
VAL_ 16 linkVoltage_BMS01 65535 "SNA" ;
VAL_ 16 current_BMS01 0 "SHORT_CIRCUIT" 65535 "SNA" ;
VAL_ 16 chargeState_BMS01 15 "CHARGESTATE_INVALID" 1 "CHARGESTATE_COMPLETE" 0 "CHARGESTATE_NOTCOMPLETE" ;
VAL_ 16 stringState_BMS01 6 "STATE_ESS_FAULT" 15 "STATE_INVALID" 5 "STATE_STRING_FAULT" 4 "STATE_LIMPHOME" 3 "STATE_ACCESSORY" 2 "STATE_CHARGE" 1 "STATE_DRIVE" 0 "STATE_STANDBY" ;
